VERSION ""

NS_ :

BS_:

BU_: ADSP CH ChassisBus DIPF DIPR ETH FC GTW GTWU HVI HVS ODIN PARTY PartyBus Receiver SDCV SUI UI UIS VEH VIRT VITALS VehicleBus X

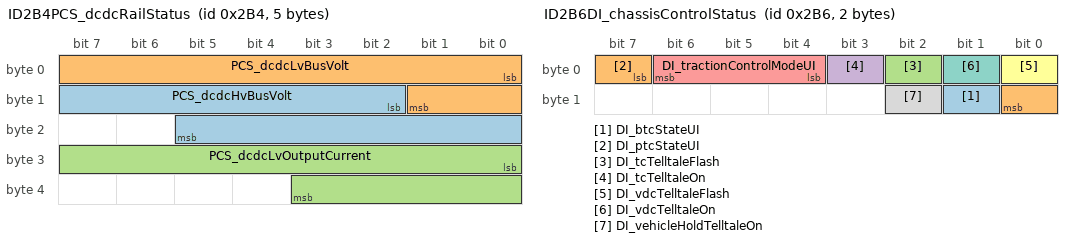
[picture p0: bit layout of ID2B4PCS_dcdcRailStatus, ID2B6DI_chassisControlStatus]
BO_ 692 ID2B4PCS_dcdcRailStatus: 5 VehicleBus
 SG_ PCS_dcdcHvBusVolt : 10|12@1+ (0.146484,0) [0|599.854] "V"  Receiver
 SG_ PCS_dcdcLvBusVolt : 0|10@1+ (0.0390625,0) [0|39.9609] "V"  Receiver
 SG_ PCS_dcdcLvOutputCurrent : 24|12@1+ (0.1,0) [0|400] "A"  Receiver

BO_ 694 ID2B6DI_chassisControlStatus: 2 VehicleBus
 SG_ DI_btcStateUI : 9|1@1+ (1,0) [0|1] ""  Receiver
 SG_ DI_ptcStateUI : 7|2@1+ (1,0) [0|3] ""  Receiver
 SG_ DI_tcTelltaleFlash : 2|1@1+ (1,0) [0|1] ""  Receiver
 SG_ DI_tcTelltaleOn : 3|1@1+ (1,0) [0|1] ""  Receiver
 SG_ DI_tractionControlModeUI : 4|3@1+ (1,0) [0|6] ""  Receiver
 SG_ DI_vdcTelltaleFlash : 0|1@1+ (1,0) [0|1] ""  Receiver
 SG_ DI_vdcTelltaleOn : 1|1@1+ (1,0) [0|1] ""  Receiver
 SG_ DI_vehicleHoldTelltaleOn : 10|1@1+ (1,0) [0|1] ""  Receiver

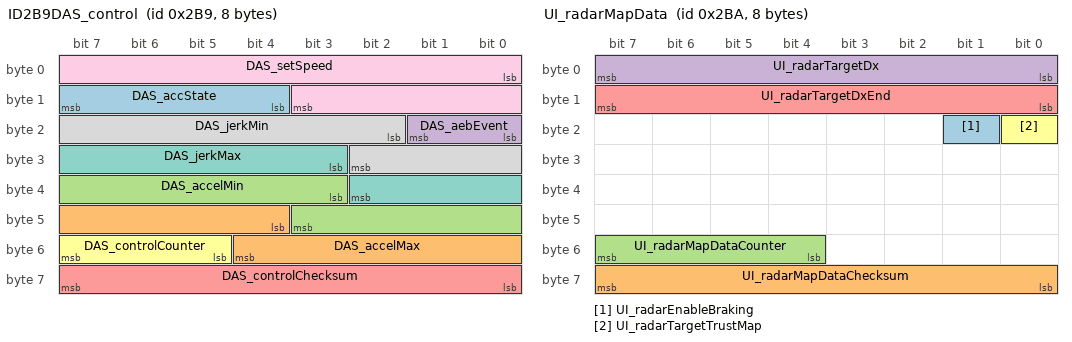
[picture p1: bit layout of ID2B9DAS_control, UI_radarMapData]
BO_ 697 ID2B9DAS_control: 8 ChassisBus
 SG_ DAS_accState : 12|4@1+ (1,0) [0|15] ""  Receiver
 SG_ DAS_accelMax : 44|9@1+ (0.04,-15) [-15|5.44] "m/s^2"  Receiver
 SG_ DAS_accelMin : 35|9@1+ (0.04,-15) [-15|5.44] "m/s^2"  Receiver
 SG_ DAS_aebEvent : 16|2@1+ (1,0) [0|3] ""  Receiver
 SG_ DAS_controlChecksum : 56|8@1+ (1,0) [0|255] ""  Receiver
 SG_ DAS_controlCounter : 53|3@1+ (1,0) [0|7] ""  Receiver
 SG_ DAS_jerkMax : 27|8@1+ (0.059,0) [0|15.045] "m/s^3"  Receiver
 SG_ DAS_jerkMin : 18|9@1+ (0.03,-15.232) [-15.232|0.098] "m/s^3"  Receiver
 SG_ DAS_setSpeed : 0|12@1+ (0.1,0) [0|409.4] "kph"  Receiver

BO_ 698 UI_radarMapData: 8 VEH
 SG_ UI_radarEnableBraking: 17|1@1+ (1,0) [0|0] "" X
 SG_ UI_radarMapDataChecksum: 56|8@1+ (1,0) [0|0] "" X
 SG_ UI_radarMapDataCounter: 52|4@1+ (1,0) [0|0] "" X
 SG_ UI_radarTargetDx: 0|8@1+ (1,-95) [0|0] "m" X
 SG_ UI_radarTargetDxEnd: 8|8@1+ (1,0) [0|0] "m" X
 SG_ UI_radarTargetTrustMap: 16|1@1+ (1,0) [0|0] "" X

BO_ 701 ID2BDCP_dcPowerLimits: 4 VehicleBus
 SG_ CP_evseInstantDcPowerLimit : 0|13@1+ (0.0622559,0) [0|509.938] "kW"  Receiver
 SG_ CP_evseMaxDcPowerLimit : 16|13@1+ (0.0622559,0) [0|509.938] "kW"  Receiver

BO_ 705 VCFRONT_logging10Hz: 8 VEH
 SG_ VCFRONT_logging10HzIndex M : 0|3@1+ (1,0) [0|7] "" X
 SG_ VCFRONT_activeLouverAbnormalKT m4 : 3|1@1+ (1,0) [0|1] "" X
 SG_ VCFRONT_activeLouverCalibRange m4 : 53|8@1+ (1,630) [630|880] "ticks" X
 SG_ VCFRONT_activeLouverCommSuccess m4 : 63|1@1+ (1,0) [0|1] "" X
 SG_ VCFRONT_activeLouverDemand m4 : 32|7@1+ (1,0) [0|100] "%" X
 SG_ VCFRONT_activeLouverDisconnect m4 : 6|1@1+ (1,0) [0|1] "" X
 SG_ VCFRONT_activeLouverFalsStallCal m4 : 62|1@1+ (1,0) [0|1] "" X
 SG_ VCFRONT_activeLouverFalsStallRun m4 : 61|1@1+ (1,0) [0|1] "" X
 SG_ VCFRONT_activeLouverIsCalibrated m4 : 15|1@1+ (1,0) [0|1] "" X
 SG_ VCFRONT_activeLouverMotorCounts m4 : 16|11@1+ (1,-100) [-100|1900] "ticks" X
 SG_ VCFRONT_activeLouverMotorState m4 : 8|3@1+ (1,0) [0|7] "" X
 SG_ VCFRONT_activeLouverOverCurrent m4 : 4|1@1+ (1,0) [0|1] "" X
 SG_ VCFRONT_activeLouverOverTemp m4 : 5|1@1+ (1,0) [0|1] "" X
 SG_ VCFRONT_activeLouverStallCounter m4 : 40|3@1+ (1,0) [0|7] "" X
 SG_ VCFRONT_activeLouverStallLength m4 : 43|10@1+ (1,0) [0|1000] "ticks" X
 SG_ VCFRONT_activeLouverStalled m4 : 7|1@1+ (1,0) [0|1] "" X
 SG_ VCFRONT_activeLouverState m4 : 11|4@1+ (1,0) [0|8] "" X
 SG_ VCFRONT_compLimitDeadband m3 : 8|1@1+ (1,0) [0|1] "" X
 SG_ VCFRONT_compLimitNvh m3 : 6|1@1+ (1,0) [0|1] "" X
 SG_ VCFRONT_compLimitPresDischargeHi m3 : 3|1@1+ (1,0) [0|1] "" X
 SG_ VCFRONT_compLimitScrollSepRamp m3 : 7|1@1+ (1,0) [0|1] "" X
 SG_ VCFRONT_compLimitScrollSepRegion m3 : 5|1@1+ (1,0) [0|1] "" X
 SG_ VCFRONT_compLimitTempDischargeHi m3 : 4|1@1+ (1,0) [0|1] "" X
 SG_ VCFRONT_compLimitTempDischargeSi m3 : 19|1@1+ (1,0) [0|1] "" X
 SG_ VCFRONT_compRampRateUpMax m3 : 20|6@1+ (0.1,0) [0|6] "%/s" X
 SG_ VCFRONT_compStandbyCoastDownMode m3 : 15|1@1+ (1,0) [0|1] "" X
 SG_ VCFRONT_compStandbyCommunication m3 : 10|1@1+ (1,0) [0|1] "" X
 SG_ VCFRONT_compStandbyHVNotReady m3 : 11|1@1+ (1,0) [0|1] "" X
 SG_ VCFRONT_compStandbyHighSuctionSu m3 : 16|1@1+ (1,0) [0|1] "" X
 SG_ VCFRONT_compStandbyLowAmbient m3 : 12|1@1+ (1,0) [0|1] "" X
 SG_ VCFRONT_compStandbyLowDischPress m3 : 13|1@1+ (1,0) [0|1] "" X
 SG_ VCFRONT_compStandbyMultiplePdCut m3 : 17|1@1+ (1,0) [0|1] "" X
 SG_ VCFRONT_compStandbyRefrigNotOk m3 : 14|1@1+ (1,0) [0|1] "" X
 SG_ VCFRONT_compStandbySelfNotReady m3 : 9|1@1+ (1,0) [0|1] "" X
 SG_ VCFRONT_compStandbyShowroomMode m3 : 18|1@1+ (1,0) [0|1] "" X
 SG_ VCFRONT_coolantFlowAmbSourceActu m0 : 48|8@1+ (0.1,0) [0|25] "LPM" X
 SG_ VCFRONT_coolantFlowAmbSourceTarg m0 : 56|8@1+ (0.1,0) [0|25] "LPM" X
 SG_ VCFRONT_coolantTempBasedMode m2 : 3|2@1+ (1,0) [0|3] "" X
 SG_ VCFRONT_coolantValveAngleActual m2 : 8|11@1+ (0.25,-100) [-100|410] "deg" X
 SG_ VCFRONT_coolantValveAngleTarget m2 : 19|10@1+ (0.25,-5) [-5|245] "deg" X
 SG_ VCFRONT_coolantValveAngleTravel m2 : 40|10@1+ (5,0) [0|5000] "deg" X
 SG_ VCFRONT_coolantValveDuty m2 : 32|8@1- (1,0) [-100|100] "%" X
 SG_ VCFRONT_coolantValveISense m2 : 56|7@1+ (0.01,0) [0|1.2] "A" X
 SG_ VCFRONT_coolantValveModeWrong m2 : 5|1@1+ (1,0) [0|1] "" X
 SG_ VCFRONT_coolantValveState m2 : 29|2@1+ (1,0) [0|3] "" X
 SG_ VCFRONT_exvFlow m3 : 32|10@1+ (0.1,0) [0|100] "%" X
 SG_ VCFRONT_exvIsFlooding m3 : 42|1@1+ (1,0) [0|1] "" X
 SG_ VCFRONT_exvMotorState m3 : 28|4@1+ (1,0) [0|10] "" X
 SG_ VCFRONT_exvPrechillActive m3 : 43|1@1+ (1,0) [0|1] "" X
 SG_ VCFRONT_pumpBatSpiError m0 : 46|1@1+ (1,0) [0|1] "" X
 SG_ VCFRONT_pumpBatteryEnabled m0 : 41|1@1+ (1,0) [0|1] "" X
 SG_ VCFRONT_pumpBatteryInitd m0 : 39|1@1+ (1,0) [0|1] "" X
 SG_ VCFRONT_pumpBatteryOutVoltage m0 : 24|7@1+ (0.2,0) [0|20] "V" X
 SG_ VCFRONT_pumpBatteryPowerOn m0 : 43|1@1+ (1,0) [0|1] "" X
 SG_ VCFRONT_pumpBatteryRPMTarget m0 : 3|10@1+ (10,0) [0|10000] "rpm" X
 SG_ VCFRONT_pumpPowertrainEnabled m0 : 42|1@1+ (1,0) [0|1] "" X
 SG_ VCFRONT_pumpPowertrainInitd m0 : 40|1@1+ (1,0) [0|1] "" X
 SG_ VCFRONT_pumpPowertrainOutVoltage m0 : 32|7@1+ (0.2,0) [0|20] "V" X
 SG_ VCFRONT_pumpPowertrainPowerOn m0 : 44|1@1+ (1,0) [0|1] "" X
 SG_ VCFRONT_pumpPowertrainRPMTarget m0 : 13|10@1+ (10,0) [0|10000] "rpm" X
 SG_ VCFRONT_pumpPtSpiError m0 : 47|1@1+ (1,0) [0|1] "" X
 SG_ VCFRONT_pumpsWake m0 : 45|1@1+ (1,0) [0|1] "" X
 SG_ VCFRONT_radarHeaterCurrent m6 : 8|8@1+ (0.1,0) [0|25.5] "A" X
 SG_ VCFRONT_radarHeaterDuty m6 : 16|7@1+ (1,0) [0|100] "%" X
 SG_ VCFRONT_radarHeaterTargetVoltage m6 : 24|8@1+ (0.1,0) [0|16] "V" X
 SG_ VCFRONT_radiatorFanDemandLimit m1 : 48|7@1+ (1,0) [0|100] "%" X
 SG_ VCFRONT_radiatorFanDemandLimited m1 : 47|1@1+ (1,0) [0|1] "" X
 SG_ VCFRONT_radiatorFanEnabled m1 : 27|1@1+ (1,0) [0|1] "" X
 SG_ VCFRONT_radiatorFanInitd m1 : 26|1@1+ (1,0) [0|1] "" X
 SG_ VCFRONT_radiatorFanOutVoltage m1 : 8|7@1+ (0.2,0) [0|20] "V" X
 SG_ VCFRONT_radiatorFanPhaseCurrent m1 : 32|8@1+ (0.25,-10) [-10|50] "A" X
 SG_ VCFRONT_radiatorFanPhaseIMax m1 : 40|7@1+ (0.25,0) [5|35] "A" X
 SG_ VCFRONT_radiatorFanPowerOn m1 : 28|1@1+ (1,0) [0|1] "" X
 SG_ VCFRONT_radiatorFanRPMTarget m1 : 16|10@1+ (10,0) [0|10000] "rpm" X
 SG_ VCFRONT_refrigerantHasBeenFilled m3 : 27|1@1+ (1,0) [0|1] "" X
 SG_ VCFRONT_refrigerantValvesClosed m3 : 26|1@1+ (1,0) [0|1] "" X
 SG_ VCFRONT_solenoidEvapCurrent m3 : 58|6@1+ (0.04,0) [0|2.4] "A" X
 SG_ VCFRONT_subcoolFeedbackFlow m5 : 13|10@1- (0.1,0) [-50|50] "%" X
 SG_ VCFRONT_subcoolFeedforwardFlow m5 : 3|10@1+ (0.1,0) [0|100] "%" X
 SG_ VCFRONT_subcoolProtectionFlow m5 : 24|10@1+ (0.1,0) [0|100] "%" X
 SG_ VCFRONT_subcoolProtectionType m5 : 34|3@1+ (1,0) [0|4] "" X
 SG_ VCFRONT_tempDischargeSimulated m3 : 44|11@1+ (0.125,-40) [-40|150] "C" X
 SG_ VCFRONT_thmlFanSpiError m1 : 55|1@1+ (1,0) [0|1] "" X
 SG_ VCFRONT_usingSimulatedAmbTemp m3 : 57|1@1+ (1,0) [0|1] "" X
 SG_ VCFRONT_usingSimulatedDischTemp m3 : 56|1@1+ (1,0) [0|1] "" X
 SG_ VCFRONT_usingSimulatedSuctTemp m3 : 55|1@1+ (1,0) [0|1] "" X

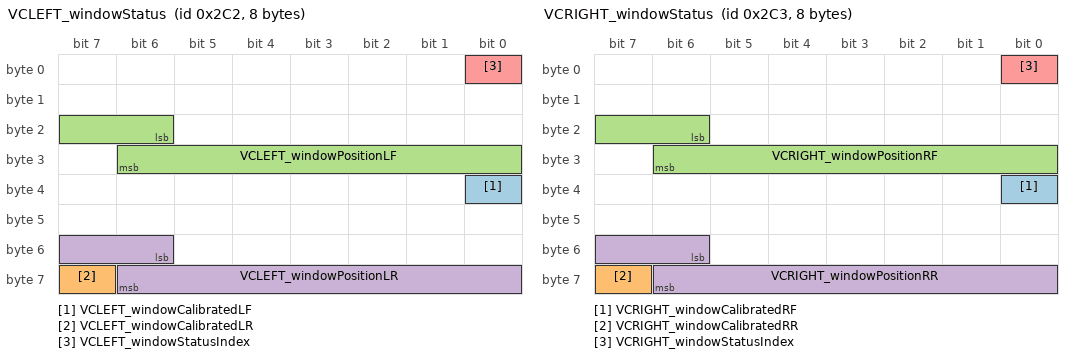
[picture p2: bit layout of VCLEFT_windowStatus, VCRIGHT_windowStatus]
BO_ 706 VCLEFT_windowStatus: 8 GTW
 SG_ VCLEFT_windowCalibratedLF : 32|1@1+ (1,0) [0|1] "" ODIN,SUI,UI
 SG_ VCLEFT_windowCalibratedLR : 63|1@1+ (1,0) [0|1] "" ODIN,SUI,UI
 SG_ VCLEFT_windowPositionLF : 22|9@1- (1.25,265.0) [-50|580] "mm" ODIN,UI
 SG_ VCLEFT_windowPositionLR : 54|9@1- (1.25,265.0) [-50|580] "mm" ODIN,UI
 SG_ VCLEFT_windowStatusIndex : 0|1@1+ (1,0) [0|1] "" XXX

BO_ 707 VCRIGHT_windowStatus: 8 GTW
 SG_ VCRIGHT_windowCalibratedRF : 32|1@1+ (1,0) [0|1] "" ODIN,SUI,UI
 SG_ VCRIGHT_windowCalibratedRR : 63|1@1+ (1,0) [0|1] "" ODIN,SUI,UI
 SG_ VCRIGHT_windowPositionRF : 22|9@1- (1.25,265.0) [-50|580] "mm" ODIN,UI
 SG_ VCRIGHT_windowPositionRR : 54|9@1- (1.25,265.0) [-50|580] "mm" ODIN,UI
 SG_ VCRIGHT_windowStatusIndex : 0|1@1+ (1,0) [0|1] "" XXX

BO_ 708 PCS_logging: 8 VEH
 SG_ PCS_logMessageSelect M: 0|5@1+ (1,0) [0|0] "" X
 SG_ PCS_chgPhAInputIrms m0: 5|9@1+ (0.1,0) [0|0] "A" X
 SG_ PCS_chgPhAIntBusV m0: 14|9@1+ (1,0) [0|0] "V" X
 SG_ PCS_chgPhAIntBusVTarget m0: 23|9@1+ (1,0) [0|0] "V" X
 SG_ PCS_chgPhAOutputI m0: 32|8@1+ (0.1,0) [0|0] "A" X
 SG_ PCS_chgPhBInputIrms m1: 5|9@1+ (0.1,0) [0|0] "A" X
 SG_ PCS_chgPhBIntBusV m1: 14|9@1+ (1,0) [0|0] "V" X
 SG_ PCS_chgPhBIntBusVTarget m1: 23|9@1+ (1,0) [0|0] "V" X
 SG_ PCS_chgPhBOutputI m1: 32|8@1+ (0.1,0) [0|0] "A" X
 SG_ PCS_chgPhCInputIrms m2: 5|9@1+ (0.1,0) [0|0] "A" X
 SG_ PCS_chgPhCIntBusV m2: 14|9@1+ (1,0) [0|0] "V" X
 SG_ PCS_chgPhCIntBusVTarget m2: 23|9@1+ (1,0) [0|0] "V" X
 SG_ PCS_chgPhCOutputI m2: 32|8@1+ (0.1,0) [0|0] "A" X
 SG_ PCS_chgInputL1NVrms m3: 5|12@1+ (0.2,0) [0|0] "V" X
 SG_ PCS_chgInputL2NVrms m3: 17|12@1+ (0.2,0) [0|0] "V" X
 SG_ PCS_chgInputL3NVrms m3: 29|12@1+ (0.2,0) [0|0] "V" X
 SG_ PCS_chgInputL1L2Vrms m3: 41|12@1+ (0.2,0) [0|0] "V" X
 SG_ PCS_chgInputNGVrms m3: 53|9@1+ (1,0) [0|0] "V" X
 SG_ PCS_chgInputFrequencyL1N m4: 8|12@1+ (0.01,40) [0|0] "Hz" X
 SG_ PCS_chgInputFrequencyL2N m4: 20|12@1+ (0.01,40) [0|0] "Hz" X
 SG_ PCS_chgInputFrequencyL3N m4: 32|12@1+ (0.01,40) [0|0] "Hz" X
 SG_ PCS_chgInternalPhaseConfig m4: 44|3@1+ (1,0) [0|0] "" X
 SG_ PCS_chgOutputV m4: 48|12@1+ (0.146484,0) [0|0] "V" X
 SG_ PCS_chgPhAState m5: 5|4@1+ (1,0) [0|0] "" X
 SG_ PCS_chgPhBState m5: 9|4@1+ (1,0) [0|0] "" X
 SG_ PCS_chgPhCState m5: 13|4@1+ (1,0) [0|0] "" X
 SG_ PCS_chgPhALastShutdownReason m5: 17|5@1+ (1,0) [0|0] "" X
 SG_ PCS_chgPhBLastShutdownReason m5: 22|5@1+ (1,0) [0|0] "" X
 SG_ PCS_chgPhCLastShutdownReason m5: 27|5@1+ (1,0) [0|0] "" X
 SG_ PCS_chgPhARetryCount m5: 32|3@1+ (1,0) [0|0] "" X
 SG_ PCS_chgPhBRetryCount m5: 35|3@1+ (1,0) [0|0] "" X
 SG_ PCS_chgPhCRetryCount m5: 38|3@1+ (1,0) [0|0] "" X
 SG_ PCS_chgRetryCount m5: 41|3@1+ (1,0) [0|0] "" X
 SG_ PCS_chgPhManCurrentToDist m5: 44|10@1+ (0.1,0) [0|0] "A" X
 SG_ PCS_chgL1NPllLocked m5: 54|1@1+ (1,0) [0|0] "" X
 SG_ PCS_chgL2NPllLocked m5: 55|1@1+ (1,0) [0|0] "" X
 SG_ PCS_chgL3NPllLocked m5: 56|1@1+ (1,0) [0|0] "" X
 SG_ PCS_chgL1L2PllLocked m5: 57|1@1+ (1,0) [0|0] "" X
 SG_ PCS_chgNgPllLocked m5: 58|1@1+ (1,0) [0|0] "" X
 SG_ PCS_chgPhManOptimalPhsToUse m5: 59|2@1+ (1,0) [0|0] "" X
 SG_ PCS_chg5VL1Enable m5: 61|1@1+ (1,0) [0|0] "" X
 SG_ PCS_dcdcMaxLvOutputCurrent m6: 28|12@1+ (0.1,0) [0|0] "A" X
 SG_ PCS_dcdcCurrentLimit m6: 40|12@1+ (0.1,0) [0|0] "A" X
 SG_ PCS_dcdcLvOutputCurrentTempLimit m6: 52|12@1+ (0.1,0) [0|0] "A" X
 SG_ PCS_dcdcUnifiedCommand m7: 5|10@1+ (0.001,0) [0|0] "1" X
 SG_ PCS_dcdcCLAControllerOutput m7: 16|10@1+ (0.001,0) [0|0] "1" X
 SG_ PCS_dcdcTankVoltage m7: 26|11@1- (1,0) [0|0] "V" X
 SG_ PCS_dcdcTankVoltageTarget m7: 37|10@1+ (1,0) [0|0] "V" X
 SG_ PCS_dcdcClaCurrentFreq m7: 48|12@1+ (0.0976563,0) [0|0] "kHz" X
 SG_ PCS_dcdcTCommMeasured m8: 8|16@1- (0.00195313,0) [0|0] "us" X
 SG_ PCS_dcdcShortTimeUs m8: 24|16@1+ (0.000488281,0) [0|0] "us" X
 SG_ PCS_dcdcHalfPeriodUs m8: 40|16@1+ (0.000488281,0) [0|0] "us" X
 SG_ PCS_cpu2BootState m9: 5|2@1+ (1,0) [0|0] "" X
 SG_ PCS_acChargeSelfTestState m9: 7|1@1+ (1,0) [0|0] "" X
 SG_ PCS_1V5Min10s m9: 8|11@1+ (0.001,0) [0|0] "V" X
 SG_ PCS_1V5Max10s m9: 19|11@1+ (0.001,0) [0|0] "V" X
 SG_ PCS_1V2Min10s m9: 32|11@1+ (0.001,0) [0|0] "V" X
 SG_ PCS_1V2Max10s m9: 43|11@1+ (0.001,0) [0|0] "V" X
 SG_ PCS_numAlertsSet m9: 56|7@1+ (1,0) [0|0] "" X
 SG_ PCS_chgPhAIntBusVMin10s m10: 5|9@1+ (1,0) [0|0] "V" X
 SG_ PCS_chgPhAIntBusVMax10s m10: 14|9@1+ (1,0) [0|0] "V" X
 SG_ PCS_chgPhAPchgVoltDeltaMax10s m10: 23|8@1+ (0.5,0) [0|0] "V" X
 SG_ PCS_chgPhALifetimekWh m10: 31|24@1+ (0.01,0) [0|0] "kWh" X
 SG_ PCS_chgPhATransientRetryCount m10: 55|9@1+ (0.1,0) [0|0] "-" X
 SG_ PCS_chgPhBIntBusVMin10s m11: 5|9@1+ (1,0) [0|0] "V" X
 SG_ PCS_chgPhBIntBusVMax10s m11: 14|9@1+ (1,0) [0|0] "V" X
 SG_ PCS_chgPhBPchgVoltDeltaMax10s m11: 23|8@1+ (0.5,0) [0|0] "V" X
 SG_ PCS_chgPhBLifetimekWh m11: 31|24@1+ (0.01,0) [0|0] "kWh" X
 SG_ PCS_chgPhBTransientRetryCount m11: 55|9@1+ (0.1,0) [0|0] "-" X
 SG_ PCS_chgPhCIntBusVMin10s m12: 5|9@1+ (1,0) [0|0] "V" X
 SG_ PCS_chgPhCIntBusVMax10s m12: 14|9@1+ (1,0) [0|0] "V" X
 SG_ PCS_chgPhCPchgVoltDeltaMax10s m12: 23|8@1+ (0.5,0) [0|0] "V" X
 SG_ PCS_chgPhCLifetimekWh m12: 31|24@1+ (0.01,0) [0|0] "kWh" X
 SG_ PCS_chgPhCTransientRetryCount m12: 55|9@1+ (0.1,0) [0|0] "-" X
 SG_ PCS_chgInputL1NVPeak10s m13: 5|9@1+ (1,0) [0|0] "V" X
 SG_ PCS_chgInputL2NVPeak10s m13: 14|9@1+ (1,0) [0|0] "V" X
 SG_ PCS_chgInputL3NVPeak10s m13: 23|9@1+ (1,0) [0|0] "V" X
 SG_ PCS_chgInputFreqWobblePHAPeak m13: 32|8@1+ (0.01,0) [0|0] "Hz" X
 SG_ PCS_chgInputFreqWobblePHBPeak m13: 40|8@1+ (0.01,0) [0|0] "Hz" X
 SG_ PCS_chgInputFreqWobblePHCPeak m13: 48|8@1+ (0.01,0) [0|0] "Hz" X
 SG_ PCS_dLogPhAChannel1Content m14: 5|2@1+ (1,0) [0|0] "" X
 SG_ PCS_dLogPhBChannel1Content m14: 8|2@1+ (1,0) [0|0] "" X
 SG_ PCS_dLogPhCChannel1Content m14: 10|2@1+ (1,0) [0|0] "" X
 SG_ PCS_dLogPhAChannel1Data m14: 16|16@1- (0.02,0) [0|0] "-" X
 SG_ PCS_dLogPhBChannel1Data m14: 32|16@1- (0.02,0) [0|0] "-" X
 SG_ PCS_dLogPhCChannel1Data m14: 48|16@1- (0.02,0) [0|0] "-" X
 SG_ PCS_dLogPhAChannel2Content m15: 5|2@1+ (1,0) [0|0] "" X
 SG_ PCS_dLogPhBChannel2Content m15: 8|2@1+ (1,0) [0|0] "" X
 SG_ PCS_dLogPhCChannel2Content m15: 10|2@1+ (1,0) [0|0] "" X
 SG_ PCS_dLogPhAChannel2Data m15: 16|16@1- (0.02,0) [0|0] "-" X
 SG_ PCS_dLogPhBChannel2Data m15: 32|16@1- (0.02,0) [0|0] "-" X
 SG_ PCS_dLogPhCChannel2Data m15: 48|16@1- (0.02,0) [0|0] "-" X
 SG_ PCS_dLogPhAChannel3Content m16: 5|2@1+ (1,0) [0|0] "" X
 SG_ PCS_dLogPhBChannel3Content m16: 8|2@1+ (1,0) [0|0] "" X
 SG_ PCS_dLogPhCChannel3Content m16: 10|2@1+ (1,0) [0|0] "" X
 SG_ PCS_dLogPhAChannel3Data m16: 16|16@1- (0.02,0) [0|0] "-" X
 SG_ PCS_dLogPhBChannel3Data m16: 32|16@1- (0.02,0) [0|0] "-" X
 SG_ PCS_dLogPhCChannel3Data m16: 48|16@1- (0.02,0) [0|0] "-" X
 SG_ PCS_dLogPhAChannel4Content m17: 5|2@1+ (1,0) [0|0] "" X
 SG_ PCS_dLogPhBChannel4Content m17: 8|2@1+ (1,0) [0|0] "" X
 SG_ PCS_dLogPhCChannel4Content m17: 10|2@1+ (1,0) [0|0] "" X
 SG_ PCS_dLogPhAChannel4Data m17: 16|16@1- (0.02,0) [0|0] "-" X
 SG_ PCS_dLogPhBChannel4Data m17: 32|16@1- (0.02,0) [0|0] "-" X
 SG_ PCS_dLogPhCChannel4Data m17: 48|16@1- (0.02,0) [0|0] "-" X
 SG_ PCS_dcdcIntervalMaxFrequency m18: 8|12@1+ (1,0) [0|0] "kHz" X
 SG_ PCS_dcdcIntervalMaxHvBusVolt m18: 24|13@1+ (0.1,0) [0|0] "V" X
 SG_ PCS_dcdcIntervalMaxLvBusVolt m18: 37|9@1+ (0.1,0) [0|0] "V" X
 SG_ PCS_dcdcIntervalMaxLvOutputCurr m18: 48|12@1+ (1,0) [0|0] "A" X
 SG_ PCS_dcdcIntervalMinFrequency m19: 8|12@1+ (1,0) [0|0] "kHz" X
 SG_ PCS_dcdcIntervalMinHvBusVolt m19: 24|13@1+ (0.1,0) [0|0] "V" X
 SG_ PCS_dcdcIntervalMinLvBusVolt m19: 37|9@1+ (0.1,0) [0|0] "V" X
 SG_ PCS_dcdcIntervalMinLvOutputCurr m19: 48|12@1+ (1,0) [0|0] "A" X
 SG_ PCS_chgPhANoFlowBucket m20: 5|9@1+ (0.01,0) [0|0] "-" X
 SG_ PCS_chgPhBNoFlowBucket m20: 14|9@1+ (0.01,0) [0|0] "-" X
 SG_ PCS_chgPhCNoFlowBucket m20: 23|9@1+ (0.01,0) [0|0] "-" X
 SG_ PCS_chgInputL1NVdc m21: 5|10@1- (1,0) [0|0] "V" X
 SG_ PCS_chgInputL2NVdc m21: 16|10@1- (1,0) [0|0] "V" X
 SG_ PCS_chgInputL3NVdc m21: 26|10@1- (1,0) [0|0] "V" X
 SG_ PCS_chgInputL1L2Vdc m21: 36|10@1- (1,0) [0|0] "V" X
 SG_ PCS_chgInputNGVdc m21: 46|10@1- (1,0) [0|0] "V" X
 SG_ PCS_dcdc12vSupportLifetimekWh m22: 8|24@1+ (0.01,0) [0|0] "kWh" X

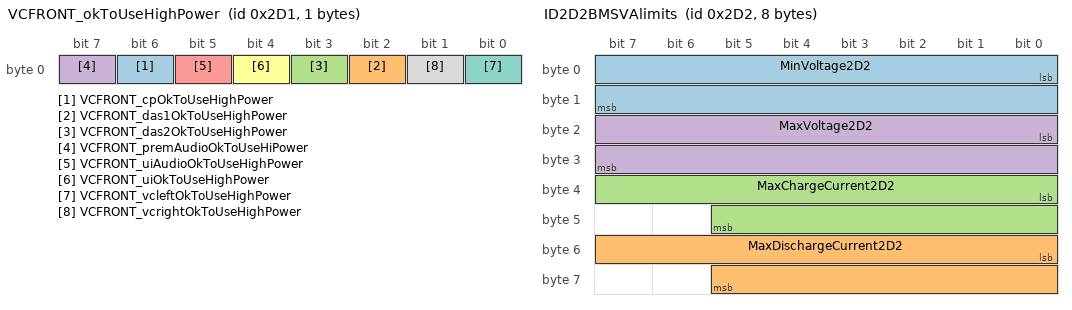
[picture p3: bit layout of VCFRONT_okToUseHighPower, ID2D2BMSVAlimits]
BO_ 721 VCFRONT_okToUseHighPower: 1 VEH
 SG_ VCFRONT_cpOkToUseHighPower: 6|1@1+ (1,0) [0|0] "" X
 SG_ VCFRONT_das1OkToUseHighPower: 2|1@1+ (1,0) [0|0] "" X
 SG_ VCFRONT_das2OkToUseHighPower: 3|1@1+ (1,0) [0|0] "" X
 SG_ VCFRONT_premAudioOkToUseHiPower: 7|1@1+ (1,0) [0|0] "" X
 SG_ VCFRONT_uiAudioOkToUseHighPower: 5|1@1+ (1,0) [0|0] "" X
 SG_ VCFRONT_uiOkToUseHighPower: 4|1@1+ (1,0) [0|0] "" X
 SG_ VCFRONT_vcleftOkToUseHighPower: 0|1@1+ (1,0) [0|0] "" X
 SG_ VCFRONT_vcrightOkToUseHighPower: 1|1@1+ (1,0) [0|0] "" X

BO_ 722 ID2D2BMSVAlimits: 8 VehicleBus
 SG_ MinVoltage2D2 : 0|16@1+ (0.01,0) [0|430] "V"  Receiver
 SG_ MaxDischargeCurrent2D2 : 48|14@1+ (0.128,0) [0|2096.9] "A"  Receiver
 SG_ MaxChargeCurrent2D2 : 32|14@1+ (0.1,0) [0|1638.2] "A"  Receiver
 SG_ MaxVoltage2D2 : 16|16@1+ (0.01,0) [0|430] "V"  Receiver

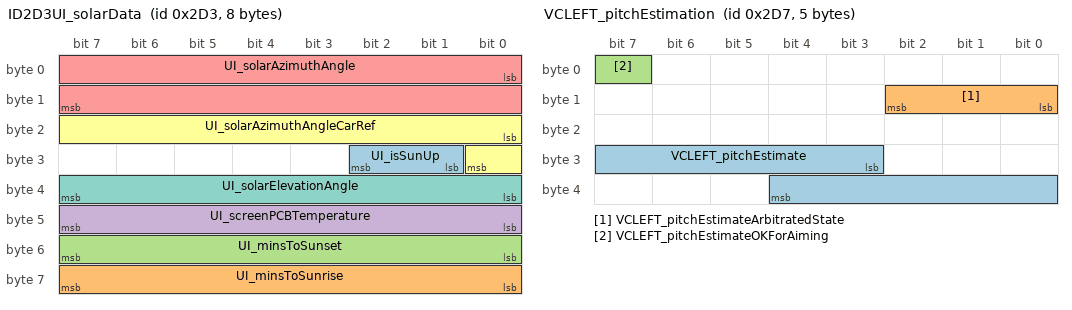
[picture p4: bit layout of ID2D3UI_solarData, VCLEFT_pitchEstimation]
BO_ 723 ID2D3UI_solarData: 8 ChassisBus
 SG_ UI_isSunUp : 25|2@1+ (1,0) [0|3] ""  Receiver
 SG_ UI_minsToSunrise : 56|8@1+ (10,0) [0|2550] "min"  Receiver
 SG_ UI_minsToSunset : 48|8@1+ (10,0) [0|2550] "min"  Receiver
 SG_ UI_screenPCBTemperature : 40|8@1- (0.5,40) [-20|100] "C"  Receiver
 SG_ UI_solarAzimuthAngle : 0|16@1- (1,0) [-32767|32767] "deg"  Receiver
 SG_ UI_solarAzimuthAngleCarRef : 16|9@1- (1,0) [-256|254] "deg"  Receiver
 SG_ UI_solarElevationAngle : 32|8@1- (1,0) [-128|126] "deg"  Receiver

BO_ 725 DIF_status: 7 GTW
 SG_ DIF_wasteState : 32|2@1+ (1,0) [0|3] "" ODIN,SUI

BO_ 727 VCLEFT_pitchEstimation: 5 GTW
 SG_ VCLEFT_pitchEstimate : 27|10@1- (0.0002,0) [-0.1022|0.1022] "rad" ODIN
 SG_ VCLEFT_pitchEstimateArbitratedState : 8|3@1+ (1,0) [0|7] "" ODIN
 SG_ VCLEFT_pitchEstimateOKForAiming : 7|1@1+ (1,0) [0|1] "" ODIN,UI

BO_ 737 ID2E1VCFRONT_status: 8 VehicleBus
 SG_ VCFRONT_statusIndex M : 0|3@1+ (1,0) [0|6] ""  Receiver
 SG_ VCFRONT_12VARailStable m5 : 5|1@1+ (1,0) [0|1] ""  Receiver
 SG_ VCFRONT_12VBRailStable m5 : 6|1@1+ (1,0) [0|1] ""  Receiver
 SG_ VCFRONT_12VOverchargeCounter m4 : 16|4@1+ (1,0) [0|15] ""  Receiver
 SG_ VCFRONT_5VARailStable m5 : 3|1@1+ (1,0) [0|1] ""  Receiver
 SG_ VCFRONT_5VBRailStable m5 : 4|1@1+ (1,0) [0|1] ""  Receiver
 SG_ VCFRONT_AS8510Voltage m5 : 28|12@1+ (0.00544368,0) [0|22.2864] "V"  Receiver
 SG_ VCFRONT_ChargePumpVoltageStable m5 : 9|1@1+ (1,0) [0|1] ""  Receiver
 SG_ VCFRONT_HSDInitCompleteU13 m5 : 11|1@1+ (1,0) [0|1] ""  Receiver
 SG_ VCFRONT_HSDInitCompleteU16 m5 : 12|1@1+ (1,0) [0|1] ""  Receiver
 SG_ VCFRONT_IBSFault m4 : 15|1@1+ (1,0) [0|1] ""  Receiver
 SG_ VCFRONT_PCSMia m4 : 14|1@1+ (1,0) [0|1] ""  Receiver
 SG_ VCFRONT_PEResetLineState m5 : 10|1@1+ (1,0) [0|1] ""  Receiver
 SG_ VCFRONT_airCompressorStatus m0 : 25|3@1+ (1,0) [0|7] ""  Receiver
 SG_ VCFRONT_anyClosureOpen m0 : 49|1@1+ (1,0) [0|1] ""  Receiver
 SG_ VCFRONT_anyDoorOpen m0 : 50|1@1+ (1,0) [0|1] ""  Receiver
 SG_ VCFRONT_batterySMState m1 : 16|4@1+ (1,0) [0|8] ""  Receiver
 SG_ VCFRONT_chargeNeeded m4 : 13|1@1+ (1,0) [0|1] ""  Receiver
 SG_ VCFRONT_chillerDemandActive m3 : 26|1@1+ (1,0) [0|1] ""  Receiver
 SG_ VCFRONT_compPerfRecoveryLimited m3 : 27|1@1+ (1,0) [0|1] ""  Receiver
 SG_ VCFRONT_coolantFillRoutineStatus m3 : 50|2@1+ (1,0) [0|3] ""  Receiver
 SG_ VCFRONT_crashDetectedType m0 : 20|2@1+ (1,0) [0|3] ""  Receiver
 SG_ VCFRONT_crashState m0 : 22|2@1+ (1,0) [0|3] ""  Receiver
 SG_ VCFRONT_crashUnlockOverrideSet m0 : 24|1@1+ (1,0) [0|1] ""  Receiver
 SG_ VCFRONT_epasWakeLine m1 : 4|1@1+ (1,0) [0|1] ""  Receiver
 SG_ VCFRONT_freezeEvapITerm m3 : 24|1@1+ (1,0) [0|1] ""  Receiver
 SG_ VCFRONT_frunkAccessPost m0 : 62|1@1+ (1,0) [0|1] ""  Receiver
 SG_ VCFRONT_frunkInteriorRelSwitch m0 : 48|1@1+ (1,0) [0|1] ""  Receiver
 SG_ VCFRONT_frunkLatchStatus m0 : 3|4@1+ (1,0) [0|8] ""  Receiver
 SG_ VCFRONT_frunkLatchType m0 : 58|2@1+ (1,0) [0|2] ""  Receiver
 SG_ VCFRONT_hasLowRefrigerant m3 : 29|1@1+ (1,0) [0|1] ""  Receiver
 SG_ VCFRONT_headlampLeftFanStatus m0 : 60|1@1+ (1,0) [0|1] ""  Receiver
 SG_ VCFRONT_headlampRightFanStatus m0 : 61|1@1+ (1,0) [0|1] ""  Receiver
 SG_ VCFRONT_headlightLeftVPosition m0 : 28|10@1+ (1,0) [0|1023] "ticks"  Receiver
 SG_ VCFRONT_headlightRightVPosition m0 : 38|10@1+ (1,0) [0|1023] "ticks"  Receiver
 SG_ VCFRONT_homelinkCommStatus m2 : 48|2@1+ (1,0) [0|3] ""  Receiver
 SG_ VCFRONT_homelinkV2Response0 m2 : 8|8@1+ (1,0) [0|255] ""  Receiver
 SG_ VCFRONT_homelinkV2Response1 m2 : 16|8@1+ (1,0) [0|255] ""  Receiver
 SG_ VCFRONT_homelinkV2Response2 m2 : 24|8@1+ (1,0) [0|255] ""  Receiver
 SG_ VCFRONT_homelinkV2Response3 m2 : 32|8@1+ (1,0) [0|255] ""  Receiver
 SG_ VCFRONT_homelinkV2Response4 m2 : 40|8@1+ (1,0) [0|255] ""  Receiver
 SG_ VCFRONT_hornOn m0 : 51|1@1+ (1,0) [0|1] ""  Receiver
 SG_ VCFRONT_hvacModeNotAttainable m3 : 28|1@1+ (1,0) [0|1] ""  Receiver
 SG_ VCFRONT_hvacPerfTestCommand m3 : 48|2@1+ (1,0) [0|3] ""  Receiver
 SG_ VCFRONT_iBoosterStateDBG m1 : 5|3@1+ (1,0) [0|4] ""  Receiver
 SG_ VCFRONT_iBoosterWakeLine m1 : 3|1@1+ (1,0) [0|1] ""  Receiver
 SG_ VCFRONT_isActiveHeatingBattery m0 : 63|1@1+ (1,0) [0|1] ""  Receiver
 SG_ VCFRONT_isColdStartRunning m3 : 30|1@1+ (1,0) [0|1] ""  Receiver
 SG_ VCFRONT_isEvapOperationAllowed m3 : 25|1@1+ (1,0) [0|1] ""  Receiver
 SG_ VCFRONT_isHeatPumpOilPurgeActive m3 : 31|1@1+ (1,0) [0|1] ""  Receiver
 SG_ VCFRONT_maxEvapHeatRejection m3 : 8|8@1+ (65,0) [0|16575] "W"  Receiver
 SG_ VCFRONT_minEvapHeatRejection m3 : 16|8@1+ (10,0) [0|2500] "W"  Receiver
 SG_ VCFRONT_passengerBuckleStatus m0 : 57|1@1+ (1,0) [0|1] ""  Receiver
 SG_ VCFRONT_pressureRefrigDischarge m3 : 40|8@1+ (0.125,0) [0|31.75] "bar"  Receiver
 SG_ VCFRONT_pressureRefrigSuction m3 : 32|7@1+ (0.125,0) [0|11.5] "bar"  Receiver
 SG_ VCFRONT_radarHeaterState m0 : 52|3@1+ (1,0) [0|4] ""  Receiver
 SG_ VCFRONT_railAState m5 : 7|1@1+ (1,0) [0|1] ""  Receiver
 SG_ VCFRONT_railBState m5 : 8|1@1+ (1,0) [0|1] ""  Receiver
 SG_ VCFRONT_refrigFillRoutineStatus m3 : 52|2@1+ (1,0) [0|3] ""  Receiver
 SG_ VCFRONT_reverseBatteryFault m4 : 30|1@1+ (1,0) [0|1] ""  Receiver
 SG_ VCFRONT_shortedCellFaultCounter m4 : 44|3@1+ (1,0) [0|7] ""  Receiver
 SG_ VCFRONT_silentWakeIBSCurrent m4 : 32|12@1- (0.1,-204.7) [-409.5|0] "mA"  Receiver
 SG_ VCFRONT_sleepCurrent m1 : 32|12@1- (0.1,-204.7) [-409.5|0] "mA"  Receiver
 SG_ VCFRONT_tempCompTargetVoltage m4 : 3|10@1+ (0.01,9) [9|16] "V"  Receiver
 SG_ VCFRONT_timeSpentSleeping m1 : 24|8@1+ (1,0) [0|255] "s"  Receiver
 SG_ VCFRONT_vbatMonitorVoltage m5 : 16|12@1+ (0.00544368,0) [0|22.2864] "V"  Receiver
 SG_ VCFRONT_vbatProt m5 : 40|12@1+ (0.00544368,0) [0|22.2919] "V"  Receiver
 SG_ VCFRONT_vehicleStatusDBG m1 : 8|5@1+ (1,0) [0|17] ""  Receiver
 SG_ VCFRONT_voltageDropCounter m4 : 20|4@1+ (1,0) [0|15] ""  Receiver
 SG_ VCFRONT_voltageFloorReachedCount m4 : 24|4@1+ (1,0) [0|15] ""  Receiver
 SG_ VCFRONT_voltageProfile m4 : 28|2@1+ (1,0) [0|3] ""  Receiver
 SG_ VCFRONT_wiperPosition m0 : 12|3@1+ (1,0) [0|4] ""  Receiver
 SG_ VCFRONT_wiperSpeed m0 : 8|4@1+ (1,0) [0|8] ""  Receiver
 SG_ VCFRONT_wiperState m0 : 16|4@1+ (1,0) [0|12] ""  Receiver

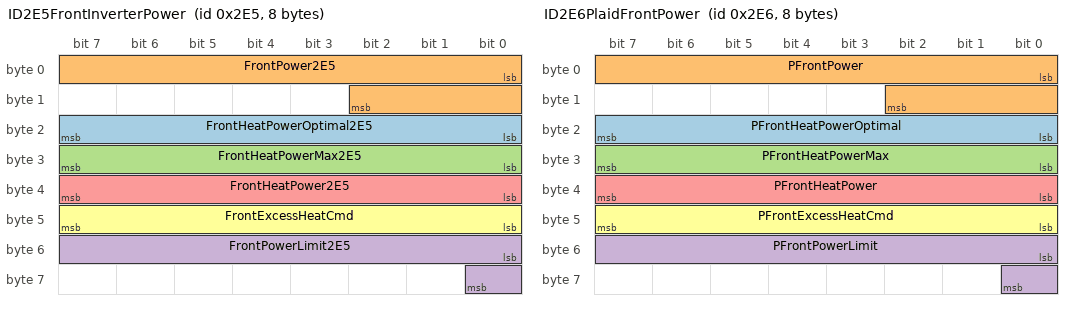
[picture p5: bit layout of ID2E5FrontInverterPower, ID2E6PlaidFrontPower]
BO_ 741 ID2E5FrontInverterPower: 8 VehicleBus
 SG_ FrontHeatPowerOptimal2E5 : 16|8@1+ (0.08,0) [0|20.4] "kW"  Receiver
 SG_ FrontPower2E5 : 0|11@1- (0.5,0) [-512|511.5] "kW"  Receiver
 SG_ FrontHeatPowerMax2E5 : 24|8@1+ (0.08,0) [0|20.4] "kW"  Receiver
 SG_ FrontPowerLimit2E5 : 48|9@1+ (1,0) [0|400] "kW"  Receiver
 SG_ FrontHeatPower2E5 : 32|8@1+ (0.08,0) [0|20.4] "kW"  Receiver
 SG_ FrontExcessHeatCmd : 40|8@1+ (0.08,0) [0|20] "kW"  Receiver

BO_ 742 ID2E6PlaidFrontPower: 8 VehicleBus
 SG_ PFrontHeatPowerOptimal : 16|8@1+ (0.08,0) [0|20.4] "kW"  Receiver
 SG_ PFrontPower : 0|11@1- (0.5,0) [-512|511.5] "kW"  Receiver
 SG_ PFrontHeatPowerMax : 24|8@1+ (0.08,0) [0|20.4] "kW"  Receiver
 SG_ PFrontPowerLimit : 48|9@1+ (1,0) [0|400] "kW"  Receiver
 SG_ PFrontHeatPower : 32|8@1+ (0.08,0) [0|20.4] "kW"  Receiver
 SG_ PFrontExcessHeatCmd : 40|8@1+ (0.08,0) [0|20] "kW"  Receiver

BO_ 744 EPBR_status: 8 GTW
 SG_ EPBR_systemStatus : 0|4@1+ (1,0) [0|8] "" ODIN,SUI,UI,VITALS

BO_ 753 ID2F1VCFRONT_eFuseDebugStatus: 8 VehicleBus
 SG_ VCFRONT_eFuseDebugStatusIndex M : 0|5@1+ (1,0) [0|18] ""  Receiver
 SG_ VCFRONT_ChargePumpVoltage m16 : 24|16@1+ (0.00544368,0) [0|356.751] "V"  Receiver
 SG_ VCFRONT_EPAS3PCurrent m4 : 47|16@1+ (0.1,0) [0|6553.5] "A"  Receiver
 SG_ VCFRONT_EPAS3PFault m4 : 10|1@1+ (1,0) [0|1] ""  Receiver
 SG_ VCFRONT_EPAS3PSelfTestResult m4 : 11|4@1+ (1,0) [0|11] ""  Receiver
 SG_ VCFRONT_EPAS3PState m4 : 8|2@1+ (1,0) [0|2] ""  Receiver
 SG_ VCFRONT_EPAS3PTemp m4 : 15|11@1+ (0.125,-40) [-40|150] "C"  Receiver
 SG_ VCFRONT_EPAS3PVoltage m4 : 31|16@1+ (0.1,0) [0|6553.5] "V"  Receiver
 SG_ VCFRONT_EPAS3SCurrent m5 : 47|16@1+ (0.1,0) [0|6553.5] "A"  Receiver
 SG_ VCFRONT_EPAS3SFault m5 : 10|1@1+ (1,0) [0|1] ""  Receiver
 SG_ VCFRONT_EPAS3SSelfTestResult m5 : 11|4@1+ (1,0) [0|11] ""  Receiver
 SG_ VCFRONT_EPAS3SState m5 : 8|2@1+ (1,0) [0|2] ""  Receiver
 SG_ VCFRONT_EPAS3STemp m5 : 15|11@1+ (0.125,-40) [-40|150] "C"  Receiver
 SG_ VCFRONT_EPAS3SVoltage m5 : 31|16@1+ (0.1,0) [0|6553.5] "V"  Receiver
 SG_ VCFRONT_ESPMotorCurrent m6 : 47|16@1+ (0.1,0) [0|6553.5] "A"  Receiver
 SG_ VCFRONT_ESPMotorFault m6 : 10|1@1+ (1,0) [0|1] ""  Receiver
 SG_ VCFRONT_ESPMotorSelfTestResult m6 : 11|4@1+ (1,0) [0|11] ""  Receiver
 SG_ VCFRONT_ESPMotorState m6 : 8|2@1+ (1,0) [0|2] ""  Receiver
 SG_ VCFRONT_ESPMotorTemp m6 : 15|11@1+ (0.125,-40) [-40|150] "C"  Receiver
 SG_ VCFRONT_ESPMotorVoltage m6 : 31|16@1+ (0.1,0) [0|6553.5] "V"  Receiver
 SG_ VCFRONT_ESPValveCurrent m7 : 44|16@1+ (0.1,0) [0|6553.5] "A"  Receiver
 SG_ VCFRONT_ESPValveFault m7 : 10|1@1+ (1,0) [0|1] ""  Receiver
 SG_ VCFRONT_ESPValveState m7 : 8|2@1+ (1,0) [0|2] ""  Receiver
 SG_ VCFRONT_ESPValveTemp m7 : 12|11@1+ (0.125,-40) [-40|150] "C"  Receiver
 SG_ VCFRONT_ESPValveVoltage m7 : 28|16@1+ (0.1,0) [0|6553.5] "V"  Receiver
 SG_ VCFRONT_IBSUnfilteredTemperature m17 : 40|16@1- (0.01,0) [-327.68|327.67] "C"  Receiver
 SG_ VCFRONT_PCSCurrent m2 : 47|16@1- (0.1,0) [-3276.8|3276.7] "A"  Receiver
 SG_ VCFRONT_PCSFault m2 : 10|1@1+ (1,0) [0|1] ""  Receiver
 SG_ VCFRONT_PCSState m2 : 8|2@1+ (1,0) [0|2] ""  Receiver
 SG_ VCFRONT_PCSTemp m2 : 15|11@1+ (0.125,-40) [-40|150] "C"  Receiver
 SG_ VCFRONT_PCSVoltage m2 : 31|16@1+ (0.1,0) [0|6553.5] "V"  Receiver
 SG_ VCFRONT_autopilot1Current m8 : 43|16@1+ (0.1,0) [0|6553.5] "A"  Receiver
 SG_ VCFRONT_autopilot1Fault m8 : 10|1@1+ (1,0) [0|1] ""  Receiver
 SG_ VCFRONT_autopilot1State m8 : 8|2@1+ (1,0) [0|2] ""  Receiver
 SG_ VCFRONT_autopilot1Temp m8 : 11|11@1+ (0.125,-40) [-40|150] "C"  Receiver
 SG_ VCFRONT_autopilot1Voltage m8 : 27|16@1+ (0.1,0) [0|6553.5] "V"  Receiver
 SG_ VCFRONT_autopilot2Current m9 : 43|16@1+ (0.1,0) [0|6553.5] "A"  Receiver
 SG_ VCFRONT_autopilot2Fault m9 : 10|1@1+ (1,0) [0|1] ""  Receiver
 SG_ VCFRONT_autopilot2State m9 : 8|2@1+ (1,0) [0|2] ""  Receiver
 SG_ VCFRONT_autopilot2Temp m9 : 11|11@1+ (0.125,-40) [-40|150] "C"  Receiver
 SG_ VCFRONT_autopilot2Voltage m9 : 27|16@1+ (0.1,0) [0|6553.5] "V"  Receiver
 SG_ VCFRONT_chargedIBSAmpHours m17 : 8|16@1+ (1,0) [0|65535] "Ah"  Receiver
 SG_ VCFRONT_dischargedIBSAmpHours m17 : 24|16@1+ (1,0) [0|65535] "Ah"  Receiver
 SG_ VCFRONT_eFuseLockoutVoltage m16 : 8|12@1+ (0.00544368,0) [0|22.2919] "V"  Receiver
 SG_ VCFRONT_headlampLeftCurrent m12 : 10|10@1+ (0.1,0) [0|102.3] "A"  Receiver
 SG_ VCFRONT_headlampLeftFault m12 : 9|1@1+ (1,0) [0|1] ""  Receiver
 SG_ VCFRONT_headlampLeftState m12 : 8|1@1+ (1,0) [0|1] ""  Receiver
 SG_ VCFRONT_headlampLeftTemperature m12 : 48|8@1- (1,-40) [-40|150] "C"  Receiver
 SG_ VCFRONT_headlampLeftVoltage m12 : 20|8@1+ (0.1,0) [0|25.4] "V"  Receiver
 SG_ VCFRONT_headlampRightCurrent m12 : 30|10@1+ (0.1,0) [0|102.3] "A"  Receiver
 SG_ VCFRONT_headlampRightFault m12 : 29|1@1+ (1,0) [0|1] ""  Receiver
 SG_ VCFRONT_headlampRightState m12 : 28|1@1+ (1,0) [0|1] ""  Receiver
 SG_ VCFRONT_headlampRightTemperature m12 : 56|8@1- (1,-40) [-40|150] "C"  Receiver
 SG_ VCFRONT_headlampRightVoltage m12 : 40|8@1+ (0.1,0) [0|25.4] "V"  Receiver
 SG_ VCFRONT_iBoosterCurrent m3 : 47|16@1+ (0.1,0) [0|6553.5] "A"  Receiver
 SG_ VCFRONT_iBoosterFault m3 : 10|1@1+ (1,0) [0|1] ""  Receiver
 SG_ VCFRONT_iBoosterSelfTestResult m3 : 11|4@1+ (1,0) [0|11] ""  Receiver
 SG_ VCFRONT_iBoosterState m3 : 8|2@1+ (1,0) [0|2] ""  Receiver
 SG_ VCFRONT_iBoosterTemp m3 : 15|11@1+ (0.125,-40) [-40|150] "C"  Receiver
 SG_ VCFRONT_iBoosterVoltage m3 : 31|16@1+ (0.1,0) [0|6553.5] "V"  Receiver
 SG_ VCFRONT_leftControllerCurrent m1 : 47|16@1+ (0.1,0) [0|6553.5] "A"  Receiver
 SG_ VCFRONT_leftControllerFault m1 : 10|1@1+ (1,0) [0|1] ""  Receiver
 SG_ VCFRONT_leftControllerState m1 : 8|2@1+ (1,0) [0|2] ""  Receiver
 SG_ VCFRONT_leftControllerTemp m1 : 15|11@1+ (0.125,-40) [-40|150] "C"  Receiver
 SG_ VCFRONT_leftControllerVoltage m1 : 31|16@1+ (0.1,0) [0|6553.5] "V"  Receiver
 SG_ VCFRONT_pcsSelfTestResult m2 : 11|4@1+ (1,0) [0|11] ""  Receiver
 SG_ VCFRONT_pump1AndFanCurrent m14 : 6|16@1+ (0.1,0) [0|6553.5] "A"  Receiver
 SG_ VCFRONT_pump1AndFanState m14 : 5|1@1+ (1,0) [0|1] ""  Receiver
 SG_ VCFRONT_pump1AndFanVoltage m14 : 22|12@1+ (0.1,0) [0|409.5] "V"  Receiver
 SG_ VCFRONT_pump2AndAirCompCurrent m14 : 35|16@1+ (0.1,0) [0|6553.5] "A"  Receiver
 SG_ VCFRONT_pump2AndAirCompState m14 : 34|1@1+ (1,0) [0|1] ""  Receiver
 SG_ VCFRONT_pump2AndAirCompVoltage m14 : 51|12@1+ (0.1,0) [0|409.5] "V"  Receiver
 SG_ VCFRONT_railA_12v m15 : 8|12@1+ (0.00544368,0) [0|22.2919] "V"  Receiver
 SG_ VCFRONT_railA_5v m15 : 32|12@1+ (0.00544368,0) [0|22.2919] "V"  Receiver
 SG_ VCFRONT_railB_12v m15 : 20|12@1+ (0.00544368,0) [0|22.2919] "V"  Receiver
 SG_ VCFRONT_railB_5v m15 : 44|12@1+ (0.00544368,0) [0|22.2919] "V"  Receiver
 SG_ VCFRONT_rightControllerCurrent m0 : 47|16@1+ (0.1,0) [0|6553.5] "A"  Receiver
 SG_ VCFRONT_rightControllerFault m0 : 10|1@1+ (1,0) [0|1] ""  Receiver
 SG_ VCFRONT_rightControllerState m0 : 8|2@1+ (1,0) [0|2] ""  Receiver
 SG_ VCFRONT_rightControllerTemp m0 : 15|11@1+ (0.125,-40) [-40|150] "C"  Receiver
 SG_ VCFRONT_rightControllerVoltage m0 : 31|16@1+ (0.1,0) [0|6553.5] "V"  Receiver
 SG_ VCFRONT_sleepBypassCurrent m10 : 26|16@1+ (0.1,0) [0|6553.5] "A"  Receiver
 SG_ VCFRONT_sleepBypassFault m10 : 9|1@1+ (1,0) [0|1] ""  Receiver
 SG_ VCFRONT_sleepBypassState m10 : 8|1@1+ (1,0) [0|1] ""  Receiver
 SG_ VCFRONT_sleepBypassVoltage m10 : 10|16@1+ (0.1,0) [0|6553.5] "V"  Receiver
 SG_ VCFRONT_uiAudioCurrent m11 : 8|16@1+ (0.1,0) [0|6553.5] "A"  Receiver
 SG_ VCFRONT_uiAudioFault m11 : 6|1@1+ (1,0) [0|1] ""  Receiver
 SG_ VCFRONT_uiAudioState m11 : 5|1@1+ (1,0) [0|1] ""  Receiver
 SG_ VCFRONT_uiCurrent m11 : 32|16@1+ (0.1,0) [0|6553.5] "A"  Receiver
 SG_ VCFRONT_uiFault m11 : 25|1@1+ (1,0) [0|1] ""  Receiver
 SG_ VCFRONT_uiState m11 : 24|1@1+ (1,0) [0|1] ""  Receiver
 SG_ VCFRONT_vbatFusedHighCurrent m13 : 46|16@1+ (0.1,0) [0|6553.5] "A"  Receiver
 SG_ VCFRONT_vbatFusedHighFault m13 : 9|1@1+ (1,0) [0|1] ""  Receiver
 SG_ VCFRONT_vbatFusedHighState m13 : 8|1@1+ (1,0) [0|1] ""  Receiver
 SG_ VCFRONT_vbatFusedHighTemp m13 : 14|11@1+ (0.125,-40) [-40|150] "C"  Receiver
 SG_ VCFRONT_vbatFusedHighVoltage m13 : 30|16@1+ (0.1,0) [0|6553.5] "V"  Receiver
 SG_ VCFRONT_vbatFusedSelfTestResult m13 : 10|4@1+ (1,0) [0|11] ""  Receiver
 SG_ VCFRONT_vcleftSelfTestResult m1 : 11|4@1+ (1,0) [0|11] ""  Receiver
 SG_ VCFRONT_vcrightSelfTestResult m0 : 11|4@1+ (1,0) [0|11] ""  Receiver

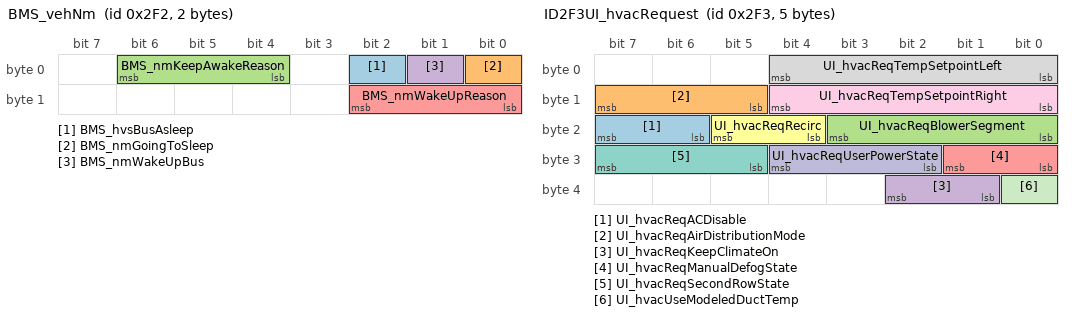
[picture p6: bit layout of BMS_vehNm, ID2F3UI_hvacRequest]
BO_ 754 BMS_vehNm: 2 VEH
 SG_ BMS_hvsBusAsleep: 2|1@1+ (1,0) [0|0] "" X
 SG_ BMS_nmGoingToSleep: 0|1@1+ (1,0) [0|0] "" X
 SG_ BMS_nmKeepAwakeReason: 4|3@1+ (1,0) [0|0] "" X
 SG_ BMS_nmWakeUpBus: 1|1@1+ (1,0) [0|0] "" X
 SG_ BMS_nmWakeUpReason: 8|3@1+ (1,0) [0|0] "" X

BO_ 755 ID2F3UI_hvacRequest: 5 VehicleBus
 SG_ UI_hvacReqACDisable : 22|2@1+ (1,0) [0|2] ""  Receiver
 SG_ UI_hvacReqAirDistributionMode : 13|3@1+ (1,0) [0|7] ""  Receiver
 SG_ UI_hvacReqBlowerSegment : 16|4@1+ (1,0) [0|11] ""  Receiver
 SG_ UI_hvacReqKeepClimateOn : 33|2@1+ (1,0) [0|3] ""  Receiver
 SG_ UI_hvacReqManualDefogState : 24|2@1+ (1,0) [0|2] ""  Receiver
 SG_ UI_hvacReqRecirc : 20|2@1+ (1,0) [0|2] ""  Receiver
 SG_ UI_hvacReqSecondRowState : 29|3@1+ (1,0) [0|4] ""  Receiver
 SG_ UI_hvacReqTempSetpointLeft : 0|5@1+ (0.5,15) [15|28] "C"  Receiver
 SG_ UI_hvacReqTempSetpointRight : 8|5@1+ (0.5,15) [15|28] "C"  Receiver
 SG_ UI_hvacReqUserPowerState : 26|3@1+ (1,0) [0|4] ""  Receiver
 SG_ UI_hvacUseModeledDuctTemp : 32|1@1+ (1,0) [0|1] ""  Receiver

BO_ 768 ID300BMS_info: 8 VehicleBus
 SG_ BMS_infoIndex M : 0|8@1+ (1,0) [0|255] ""  Receiver
 SG_ BMS_appCrc m13 : 32|32@1+ (1,0) [0|4294970000] ""  Receiver
 SG_ BMS_appGitHash m17 : 8|56@1+ (1,0) [0|7.20576E+016] ""  Receiver
 SG_ BMS_assemblyId m11 : 24|8@1+ (1,0) [0|255] ""  Receiver
 SG_ BMS_bootCrc m20 : 32|32@1+ (1,0) [0|4294970000] ""  Receiver
 SG_ BMS_bootGitHash m18 : 8|56@1+ (1,0) [0|7.20576E+016] ""  Receiver
 SG_ BMS_bootUdsProtoVersion m20 : 8|8@1+ (1,0) [0|255] ""  Receiver
 SG_ BMS_buildConfigId m10 : 16|16@1+ (1,0) [0|65535] ""  Receiver
 SG_ BMS_buildType m10 : 8|3@1+ (1,0) [0|4] ""  Receiver
 SG_ BMS_componentId m10 : 48|16@1+ (1,0) [0|65535] ""  Receiver
 SG_ BMS_hardwareId m10 : 32|16@1+ (1,0) [0|65535] ""  Receiver
 SG_ BMS_pcbaId m11 : 16|8@1+ (1,0) [0|255] ""  Receiver
 SG_ BMS_platformType m13 : 8|8@1+ (1,0) [0|255] ""  Receiver
 SG_ BMS_subUsageId m11 : 48|16@1+ (1,0) [0|65535] ""  Receiver
 SG_ BMS_usageId m11 : 32|16@1+ (1,0) [0|65535] ""  Receiver

BO_ 769 ID301VCFRONT_info: 8 VehicleBus
 SG_ VCFRONT_infoIndex M : 0|8@1+ (1,0) [0|255] ""  Receiver
 SG_ VCFRONT_hcmlAppCRC m16 : 32|32@1+ (1,0) [0|4294970000] ""  Receiver
 SG_ VCFRONT_hcmrAppCRC m23 : 32|32@1+ (1,0) [0|4294970000] ""  Receiver
 SG_ VCFRONT_infoAppCrc m13 : 8|32@1+ (1,0) [0|4294970000] ""  Receiver
 SG_ VCFRONT_infoAppGitHash m17 : 8|56@1+ (1,0) [0|7.20576E+016] ""  Receiver
 SG_ VCFRONT_infoAssemblyId m11 : 16|8@1+ (1,0) [0|255] ""  Receiver
 SG_ VCFRONT_infoBootCrc m20 : 24|32@1+ (1,0) [0|4294970000] ""  Receiver
 SG_ VCFRONT_infoBootGitHash m18 : 8|56@1+ (1,0) [0|7.20576E+016] ""  Receiver
 SG_ VCFRONT_infoBootUdsProtoVersion m20 : 8|16@1+ (1,0) [0|65535] ""  Receiver
 SG_ VCFRONT_infoBuildConfigId m10 : 16|16@1+ (1,0) [0|65535] ""  Receiver
 SG_ VCFRONT_infoBuildType m10 : 8|3@1+ (1,0) [0|4] ""  Receiver
 SG_ VCFRONT_infoComponentId m10 : 48|16@1+ (1,0) [0|65535] ""  Receiver
 SG_ VCFRONT_infoHardwareId m10 : 32|16@1+ (1,0) [0|65535] ""  Receiver
 SG_ VCFRONT_infoPcbaId m11 : 8|8@1+ (1,0) [0|255] ""  Receiver
 SG_ VCFRONT_infoPlatformType m19 : 8|8@1+ (1,0) [0|255] ""  Receiver
 SG_ VCFRONT_infoSubUsageId m11 : 40|16@1+ (1,0) [0|65535] ""  Receiver
 SG_ VCFRONT_infoSubcomponent3 m24 : 32|32@1+ (1,0) [0|4294970000] ""  Receiver
 SG_ VCFRONT_infoSubcomponent4 m31 : 32|32@1+ (1,0) [0|4294970000] ""  Receiver
 SG_ VCFRONT_infoSubcomponent5 m32 : 32|32@1+ (1,0) [0|4294970000] ""  Receiver
 SG_ VCFRONT_infoSubcomponent6 m33 : 32|32@1+ (1,0) [0|4294970000] ""  Receiver
 SG_ VCFRONT_infoUsageId m11 : 24|16@1+ (1,0) [0|65535] ""  Receiver

BO_ 770 VCLEFT_info: 8 VEH
 SG_ VCLEFT_infoIndex M: 0|8@1+ (1,0) [0|0] "" X
 SG_ VCLEFT_infoBuildType m10: 8|3@1+ (1,0) [0|0] "" X
 SG_ VCLEFT_infoBuildConfigId m10: 16|16@1+ (1,0) [0|0] "" X
 SG_ VCLEFT_infoHardwareId m10: 32|16@1+ (1,0) [0|0] "" X
 SG_ VCLEFT_infoComponentId m10: 48|16@1+ (1,0) [0|0] "" X
 SG_ VCLEFT_infoPcbaId m11: 8|8@1+ (1,0) [0|0] "" X
 SG_ VCLEFT_infoAssemblyId m11: 16|8@1+ (1,0) [0|0] "" X
 SG_ VCLEFT_infoUsageId m11: 24|16@1+ (1,0) [0|0] "" X
 SG_ VCLEFT_infoSubUsageId m11: 40|16@1+ (1,0) [0|0] "" X
 SG_ VCLEFT_infoAppCrc m13: 8|32@1+ (1,0) [0|0] "" X
 SG_ VCLEFT_infoSubcomponent1 m16: 32|32@1+ (1,0) [0|0] "" X
 SG_ VCLEFT_infoAppGitHash m17: 10|54@1+ (4,0) [0|0] "" X
 SG_ VCLEFT_infoBootGitHash m18: 10|54@1+ (4,0) [0|0] "" X
 SG_ VCLEFT_infoPlatformType m19: 8|8@1+ (1,0) [0|0] "" X
 SG_ VCLEFT_infoBootUdsProtoVersion m20: 8|16@1+ (1,0) [0|0] "" X
 SG_ VCLEFT_infoBootCrc m20: 24|32@1+ (1,0) [0|0] "" X
 SG_ VCLEFT_swcAppCRC m23: 32|32@1+ (1,0) [0|0] "" X
 SG_ VCLEFT_infoSubcomponent3 m24: 32|32@1+ (1,0) [0|0] "" X
 SG_ VCLEFT_infoCBCAppCRC m31: 32|32@1+ (1,0) [0|0] "" X

BO_ 771 OCS1P_status: 8 GTW
 SG_ OCS1P_occupiedState : 9|2@1+ (1,0) [0|3] "" ODIN

BO_ 772 PM_alertMatrix1: 8 VEH
 SG_ PM_a001_absoluteTorque: 0|1@1+ (1,0) [0|0] "" X
 SG_ PM_a002_accumulatedTorque: 1|1@1+ (1,0) [0|0] "" X
 SG_ PM_a003_torqueReversal: 2|1@1+ (1,0) [0|0] "" X
 SG_ PM_a004_regenTorque: 3|1@1+ (1,0) [0|0] "" X
 SG_ PM_a005_torqueInNeutral: 4|1@1+ (1,0) [0|0] "" X
 SG_ PM_a006_inconsistentDIGear: 5|1@1+ (1,0) [0|0] "" X
 SG_ PM_a007_watchdogReset: 6|1@1+ (1,0) [0|0] "" X
 SG_ PM_a008_memoryError: 7|1@1+ (1,0) [0|0] "" X
 SG_ PM_a009_espMIA: 8|1@1+ (1,0) [0|0] "" X
 SG_ PM_a010_diMIA: 9|1@1+ (1,0) [0|0] "" X
 SG_ PM_a011_phaseCurrentIrrational: 10|1@1+ (1,0) [0|0] "" X
 SG_ PM_a012_canDataBusA: 11|1@1+ (1,0) [0|0] "" X
 SG_ PM_a013_canHardwareBusA: 12|1@1+ (1,0) [0|0] "" X
 SG_ PM_a014_accelPedalError: 13|1@1+ (1,0) [0|0] "" X
 SG_ PM_a015_shifterMIA: 14|1@1+ (1,0) [0|0] "" X
 SG_ PM_a016_cruiseMIA: 15|1@1+ (1,0) [0|0] "" X
 SG_ PM_a017_brakeMIA: 16|1@1+ (1,0) [0|0] "" X
 SG_ PM_a018_encoderIrrational: 17|1@1+ (1,0) [0|0] "" X
 SG_ PM_a019_statorTempIrrational: 18|1@1+ (1,0) [0|0] "" X
 SG_ PM_a023_crsCmdOffStateOn: 22|1@1+ (1,0) [0|0] "" X
 SG_ PM_a024_brakeIrrational: 23|1@1+ (1,0) [0|0] "" X
 SG_ PM_a026_diHeartBeatMIA: 25|1@1+ (1,0) [0|0] "" X
 SG_ PM_a027_torqueOutOfMap: 26|1@1+ (1,0) [0|0] "" X
 SG_ PM_a028_torqueCmdError: 27|1@1+ (1,0) [0|0] "" X
 SG_ PM_a030_inconsistentAebState: 29|1@1+ (1,0) [0|0] "" X
 SG_ PM_a031_highStackUsage: 30|1@1+ (1,0) [0|0] "" X
 SG_ PM_a032_registerConfigError: 31|1@1+ (1,0) [0|0] "" X
 SG_ PM_a033_selfTest: 32|1@1+ (1,0) [0|0] "" X
 SG_ PM_a034_trqCrossCheck: 33|1@1+ (1,0) [0|0] "" X
 SG_ PM_a038_inconsistentTorqueSign: 37|1@1+ (1,0) [0|0] "" X
 SG_ PM_a039_disMIA: 38|1@1+ (1,0) [0|0] "" X
 SG_ PM_a040_pmMIA: 39|1@1+ (1,0) [0|0] "" X
 SG_ PM_a041_dasMIA: 40|1@1+ (1,0) [0|0] "" X
 SG_ PM_a042_gtwMIA: 41|1@1+ (1,0) [0|0] "" X
 SG_ PM_a043_inconsistentConfig: 42|1@1+ (1,0) [0|0] "" X
 SG_ PM_a044_ebrIntervention: 43|1@1+ (1,0) [0|0] "" X
 SG_ PM_a045_motorMovementDetected: 44|1@1+ (1,0) [0|0] "" X
 SG_ PM_a046_inconsVehicleHoldState: 45|1@1+ (1,0) [0|0] "" X
 SG_ PM_a047_inconsAutoparkState: 46|1@1+ (1,0) [0|0] "" X
 SG_ PM_a048_stabilityControlInhibit: 47|1@1+ (1,0) [0|0] "" X
 SG_ PM_a049_stbCtrlInWrongDir: 48|1@1+ (1,0) [0|0] "" X
 SG_ PM_a050_excessiveStbCtrlTrq: 49|1@1+ (1,0) [0|0] "" X
 SG_ PM_a051_unintDecelStbCtrl: 50|1@1+ (1,0) [0|0] "" X
 SG_ PM_a052_stbCtrlDrvrDecelCflct: 51|1@1+ (1,0) [0|0] "" X
 SG_ PM_a053_vcfrontMIA: 52|1@1+ (1,0) [0|0] "" X
 SG_ PM_a054_uiMIA: 53|1@1+ (1,0) [0|0] "" X
 SG_ PM_a055_resolver: 54|1@1+ (1,0) [0|0] "" X
 SG_ PM_a056_canHardwareBusB: 55|1@1+ (1,0) [0|0] "" X
 SG_ PM_a057_canDataBusB: 56|1@1+ (1,0) [0|0] "" X
 SG_ PM_a058_cmpMIA: 57|1@1+ (1,0) [0|0] "" X
 SG_ PM_a059_ptcMIA: 58|1@1+ (1,0) [0|0] "" X
 SG_ PM_a061_DIPMVersionMismatch: 60|1@1+ (1,0) [0|0] "" X
 SG_ PM_a063_debugAlert: 62|1@1+ (1,0) [0|0] "" X
 SG_ PM_a064_torqueIntervention: 63|1@1+ (1,0) [0|0] "" X

BO_ 774 VCRIGHT_info: 8 VEH
 SG_ VCRIGHT_infoIndex M: 0|8@1+ (1,0) [0|0] "" X
 SG_ VCRIGHT_infoBuildType m10: 8|3@1+ (1,0) [0|0] "" X
 SG_ VCRIGHT_infoBuildConfigId m10: 16|16@1+ (1,0) [0|0] "" X
 SG_ VCRIGHT_infoHardwareId m10: 32|16@1+ (1,0) [0|0] "" X
 SG_ VCRIGHT_infoComponentId m10: 48|16@1+ (1,0) [0|0] "" X
 SG_ VCRIGHT_infoPcbaId m11: 8|8@1+ (1,0) [0|0] "" X
 SG_ VCRIGHT_infoAssemblyId m11: 16|8@1+ (1,0) [0|0] "" X
 SG_ VCRIGHT_infoUsageId m11: 24|16@1+ (1,0) [0|0] "" X
 SG_ VCRIGHT_infoSubUsageId m11: 40|16@1+ (1,0) [0|0] "" X
 SG_ VCRIGHT_infoAppCrc m13: 8|32@1+ (1,0) [0|0] "" X
 SG_ VCRIGHT_infoAppGitHash m17: 10|54@1+ (4,0) [0|0] "" X
 SG_ VCRIGHT_infoBootGitHash m18: 10|54@1+ (4,0) [0|0] "" X
 SG_ VCRIGHT_infoPlatformType m19: 8|8@1+ (1,0) [0|0] "" X
 SG_ VCRIGHT_infoBootUdsProtoVersion m20: 8|16@1+ (1,0) [0|0] "" X
 SG_ VCRIGHT_infoBootCrc m20: 24|32@1+ (1,0) [0|0] "" X

BO_ 777 ID309DAS_object: 8 VehicleBus
 SG_ DAS_objectId M : 0|3@1+ (1,0) [0|5] ""  Receiver
 SG_ DAS_cutinVehDx m3 : 8|8@1+ (0.5,0) [0|127] "m"  Receiver
 SG_ DAS_cutinVehDy m3 : 20|7@1+ (0.35,-22.05) [-22.05|22.4] "m"  Receiver
 SG_ DAS_cutinVehHeading m5 : 56|8@1+ (0.0245437,-3.14159) [-3.14159|3.09251] "rad"  Receiver
 SG_ DAS_cutinVehId m3 : 27|7@1+ (1,0) [0|127] ""  Receiver
 SG_ DAS_cutinVehRelevantForControl m3 : 7|1@1+ (1,0) [0|1] ""  Receiver
 SG_ DAS_cutinVehType m3 : 3|3@1+ (1,0) [0|5] ""  Receiver
 SG_ DAS_cutinVehVxRel m3 : 16|4@1+ (4,-30) [-30|26] "m/s"  Receiver
 SG_ DAS_leadVeh2Dx m0 : 39|8@1+ (0.5,0) [0|127] "m"  Receiver
 SG_ DAS_leadVeh2Dy m0 : 51|7@1+ (0.35,-22.05) [-22.05|22.4] "m"  Receiver
 SG_ DAS_leadVeh2Heading m5 : 16|8@1+ (0.0245437,-3.14159) [-3.14159|3.09251] "rad"  Receiver
 SG_ DAS_leadVeh2Id m0 : 58|6@1+ (1,0) [0|63] ""  Receiver
 SG_ DAS_leadVeh2RelevantForControl m0 : 38|1@1+ (1,0) [0|1] ""  Receiver
 SG_ DAS_leadVeh2Type m0 : 34|3@1+ (1,0) [0|5] ""  Receiver
 SG_ DAS_leadVeh2VxRel m0 : 47|4@1+ (4,-30) [-30|26] "m/s"  Receiver
 SG_ DAS_leadVehDx m0 : 8|8@1+ (0.5,0) [0|127] "m"  Receiver
 SG_ DAS_leadVehDy m0 : 20|7@1+ (0.35,-22.05) [-22.05|22.4] "m"  Receiver
 SG_ DAS_leadVehHeading m5 : 8|8@1+ (0.0245437,-3.14159) [-3.14159|3.09251] "rad"  Receiver
 SG_ DAS_leadVehId m0 : 27|7@1+ (1,0) [0|127] ""  Receiver
 SG_ DAS_leadVehRelevantForControl m0 : 7|1@1+ (1,0) [0|1] ""  Receiver
 SG_ DAS_leadVehType m0 : 3|3@1+ (1,0) [0|6] ""  Receiver
 SG_ DAS_leadVehVxRel m0 : 16|4@1+ (4,-30) [-30|26] "m/s"  Receiver
 SG_ DAS_leftVeh2Dx m1 : 39|8@1+ (0.5,0) [0|127] "m"  Receiver
 SG_ DAS_leftVeh2Dy m1 : 51|7@1+ (0.35,-22.05) [-22.05|22.4] "m"  Receiver
 SG_ DAS_leftVeh2Heading m5 : 32|8@1+ (0.0245437,-3.14159) [-3.14159|3.09251] "rad"  Receiver
 SG_ DAS_leftVeh2Id m1 : 58|6@1+ (1,0) [0|63] ""  Receiver
 SG_ DAS_leftVeh2RelevantForControl m1 : 38|1@1+ (1,0) [0|1] ""  Receiver
 SG_ DAS_leftVeh2Type m1 : 34|3@1+ (1,0) [0|5] ""  Receiver
 SG_ DAS_leftVeh2VxRel m1 : 47|4@1+ (4,-30) [-30|26] "m/s"  Receiver
 SG_ DAS_leftVehDx m1 : 8|8@1+ (0.5,0) [0|127] "m"  Receiver
 SG_ DAS_leftVehDy m1 : 20|7@1+ (0.35,-22.05) [-22.05|22.4] "m"  Receiver
 SG_ DAS_leftVehHeading m5 : 24|8@1+ (0.0245437,-3.14159) [-3.14159|3.09251] "rad"  Receiver
 SG_ DAS_leftVehId m1 : 27|7@1+ (1,0) [0|127] ""  Receiver
 SG_ DAS_leftVehRelevantForControl m1 : 7|1@1+ (1,0) [0|1] ""  Receiver
 SG_ DAS_leftVehType m1 : 3|3@1+ (1,0) [0|5] ""  Receiver
 SG_ DAS_leftVehVxRel m1 : 16|4@1+ (4,-30) [-30|26] "m/s"  Receiver
 SG_ DAS_rightVeh2Dx m2 : 39|8@1+ (0.5,0) [0|127] "m"  Receiver
 SG_ DAS_rightVeh2Dy m2 : 51|7@1+ (0.35,-22.05) [-22.05|22.4] "m"  Receiver
 SG_ DAS_rightVeh2Heading m5 : 48|8@1+ (0.0245437,-3.14159) [-3.14159|3.09251] "rad"  Receiver
 SG_ DAS_rightVeh2Id m2 : 58|6@1+ (1,0) [0|63] ""  Receiver
 SG_ DAS_rightVeh2RelevantForControl m2 : 38|1@1+ (1,0) [0|1] ""  Receiver
 SG_ DAS_rightVeh2Type m2 : 34|3@1+ (1,0) [0|5] ""  Receiver
 SG_ DAS_rightVeh2VxRel m2 : 47|4@1+ (4,-30) [-30|26] "m/s"  Receiver
 SG_ DAS_rightVehDx m2 : 8|8@1+ (0.5,0) [0|127] "m"  Receiver
 SG_ DAS_rightVehDy m2 : 20|7@1+ (0.35,-22.05) [-22.05|22.4] "m"  Receiver
 SG_ DAS_rightVehHeading m5 : 40|8@1+ (0.0245437,-3.14159) [-3.14159|3.09251] "rad"  Receiver
 SG_ DAS_rightVehId m2 : 27|7@1+ (1,0) [0|127] ""  Receiver
 SG_ DAS_rightVehRelevantForControl m2 : 7|1@1+ (1,0) [0|1] ""  Receiver
 SG_ DAS_rightVehType m2 : 3|3@1+ (1,0) [0|5] ""  Receiver
 SG_ DAS_rightVehVxRel m2 : 16|4@1+ (4,-30) [-30|26] "m/s"  Receiver
 SG_ DAS_roadSignArrow m4 : 27|3@1+ (1,0) [0|4] ""  Receiver
 SG_ DAS_roadSignColor m4 : 3|3@1+ (1,0) [0|4] ""  Receiver
 SG_ DAS_roadSignControlActive m4 : 24|1@1+ (1,0) [0|1] ""  Receiver
 SG_ DAS_roadSignId m4 : 6|8@1+ (1,0) [0|255] ""  Receiver
 SG_ DAS_roadSignOrientation m4 : 30|2@1+ (1,0) [0|2] ""  Receiver
 SG_ DAS_roadSignSource m4 : 25|2@1+ (1,0) [0|2] ""  Receiver
 SG_ DAS_roadSignStopLineDist m4 : 14|10@1+ (0.2,-20) [-20|184.4] "m"  Receiver

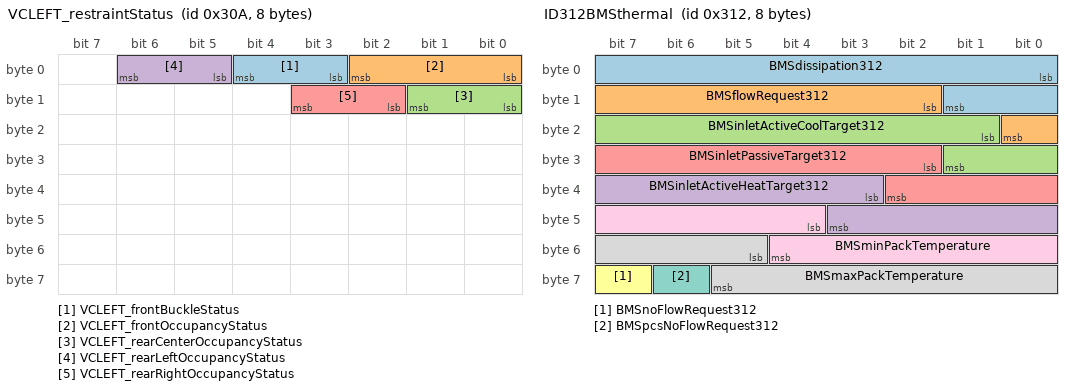
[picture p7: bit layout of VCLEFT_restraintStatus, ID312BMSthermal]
BO_ 778 VCLEFT_restraintStatus: 8 GTW
 SG_ VCLEFT_frontBuckleStatus : 3|2@1+ (1,0) [0|3] "" ODIN,SUI,UI
 SG_ VCLEFT_frontOccupancyStatus : 0|3@1+ (1,0) [0|7] "" ODIN,SUI,UI
 SG_ VCLEFT_rearCenterOccupancyStatus : 8|2@1+ (1,0) [0|3] "" ODIN,SUI,UI
 SG_ VCLEFT_rearLeftOccupancyStatus : 5|2@1+ (1,0) [0|3] "" ODIN,SUI,UI
 SG_ VCLEFT_rearRightOccupancyStatus : 10|2@1+ (1,0) [0|3] "" ODIN,SUI,UI

BO_ 782 PARK_status2: 8 GTW
 SG_ PARK_sdiActive : 24|1@1+ (1,0) [0|1] "" ODIN,SUI,UI

BO_ 784 HVP_info: 8 VEH
 SG_ HVP_infoIndex M: 0|8@1+ (1,0) [0|0] "" X
 SG_ HVP_buildType m10: 8|3@1+ (1,0) [0|0] "" X
 SG_ HVP_buildConfigId m10: 16|16@1+ (1,0) [0|0] "" X
 SG_ HVP_hardwareId m10: 32|16@1+ (1,0) [0|0] "" X
 SG_ HVP_componentId m10: 48|16@1+ (1,0) [0|0] "" X
 SG_ HVP_pcbaId m11: 16|8@1+ (1,0) [0|0] "" X
 SG_ HVP_assemblyId m11: 24|8@1+ (1,0) [0|0] "" X
 SG_ HVP_usageId m11: 32|16@1+ (1,0) [0|0] "" X
 SG_ HVP_subUsageId m11: 48|16@1+ (1,0) [0|0] "" X
 SG_ HVP_platformType m13: 8|8@1+ (1,0) [0|0] "" X
 SG_ HVP_appCrc m13: 32|32@1+ (1,0) [0|0] "" X
 SG_ HVP_appGitHash m17: 10|54@1+ (4,0) [0|0] "" X
 SG_ HVP_bootGitHash m18: 10|54@1+ (4,0) [0|0] "" X
 SG_ HVP_bootUdsProtoVersion m20: 8|8@1+ (1,0) [0|0] "" X
 SG_ HVP_bootCrc m20: 32|32@1+ (1,0) [0|0] "" X

BO_ 785 EPAS3S_info: 8 CH
 SG_ EPAS3S_infoIndex M: 0|8@1+ (1,0) [0|0] "" X
 SG_ EPAS3S_infoBuildType m10: 8|8@1+ (1,0) [0|0] "" X
 SG_ EPAS3S_infoComponentID m10: 48|16@1+ (1,0) [0|0] "" X
 SG_ EPAS3S_infoPcbaID m11: 16|8@1+ (1,0) [0|0] "" X
 SG_ EPAS3S_infoAssemblyID m11: 24|8@1+ (1,0) [0|0] "" X
 SG_ EPAS3S_infoUsageID m11: 32|16@1+ (1,0) [0|0] "" X
 SG_ EPAS3S_infoBootUdsProtoVersion m20: 8|8@1+ (1,0) [0|0] "" X
 SG_ EPAS3S_infoBootloaderCRC m20: 32|32@1+ (1,0) [0|0] "" X
 SG_ EPAS3S_infoApplicationCRC m13: 32|32@1+ (1,0) [0|0] "" X

BO_ 786 ID312BMSthermal: 8 VehicleBus
 SG_ BMSdissipation312 : 0|10@1+ (0.02,0) [0|20] "kW"  Receiver
 SG_ BMSflowRequest312 : 10|7@1+ (0.3,0) [0|30] "LPM"  Receiver
 SG_ BMSinletActiveCoolTarget312 : 17|9@1+ (0.25,-25) [-25|100] "C"  Receiver
 SG_ BMSinletActiveHeatTarget312 : 35|9@1+ (0.25,-25) [-25|100] "C"  Receiver
 SG_ BMSinletPassiveTarget312 : 26|9@1+ (0.25,-25) [-25|100] "C"  Receiver
 SG_ BMSnoFlowRequest312 : 63|1@1+ (1,0) [0|1] ""  Receiver
 SG_ BMSpcsNoFlowRequest312 : 62|1@1+ (1,0) [0|1] ""  Receiver
 SG_ BMSmaxPackTemperature : 53|9@1+ (0.25,-25) [-25|100] "C"  Receiver
 SG_ BMSminPackTemperature : 44|9@1+ (0.25,-25) [-25|100] "C"  Receiver

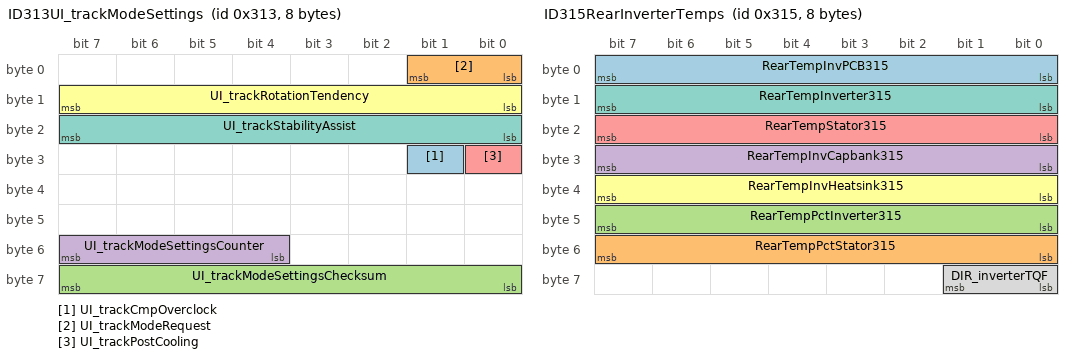
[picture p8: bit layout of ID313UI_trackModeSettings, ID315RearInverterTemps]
BO_ 787 ID313UI_trackModeSettings: 8 VehicleBus
 SG_ UI_trackCmpOverclock : 25|1@1+ (1,0) [0|1] ""  Receiver
 SG_ UI_trackModeRequest : 0|2@1+ (1,0) [0|2] ""  Receiver
 SG_ UI_trackModeSettingsChecksum : 56|8@1+ (1,0) [0|255] ""  Receiver
 SG_ UI_trackModeSettingsCounter : 52|4@1+ (1,0) [0|15] ""  Receiver
 SG_ UI_trackPostCooling : 24|1@1+ (1,0) [0|1] ""  Receiver
 SG_ UI_trackRotationTendency : 8|8@1+ (0.5,0) [0|100] "%"  Receiver
 SG_ UI_trackStabilityAssist : 16|8@1+ (0.5,0) [0|100] "%"  Receiver

BO_ 789 ID315RearInverterTemps: 8 VehicleBus
 SG_ RearTempInvPCB315 : 0|8@1+ (1,-40) [-40|215] "C"  Receiver
 SG_ RearTempPctStator315 : 48|8@1+ (0.4,0) [0|102] "%"  Receiver
 SG_ RearTempPctInverter315 : 40|8@1+ (0.4,0) [0|102] "%"  Receiver
 SG_ RearTempInvCapbank315 : 24|8@1+ (1,-40) [-40|215] "C"  Receiver
 SG_ RearTempStator315 : 16|8@1+ (1,-40) [-40|215] "C"  Receiver
 SG_ RearTempInvHeatsink315 : 32|8@1+ (1,-40) [-40|215] "C"  Receiver
 SG_ RearTempInverter315 : 8|8@1+ (1,-40) [-40|215] "C"  Receiver
 SG_ DIR_inverterTQF : 56|2@1+ (1,0) [0|3] ""  Receiver

BO_ 790 PM_info: 8 VEH
 SG_ PM_infoIndex M: 0|8@1+ (1,0) [0|0] "" X
 SG_ PM_buildType m10: 8|8@1+ (1,0) [0|0] "" X
 SG_ PM_buildConfigurationId m10: 16|16@1+ (1,0) [0|0] "" X
 SG_ PM_hardwareId m10: 32|8@1+ (1,0) [0|0] "" X
 SG_ PM_componentId m10: 48|16@1+ (1,0) [0|0] "" X
 SG_ PM_pcbaId m11: 16|8@1+ (1,0) [0|0] "" X
 SG_ PM_assemblyId m11: 24|8@1+ (1,0) [0|0] "" X
 SG_ PM_usageId m11: 32|16@1+ (1,0) [0|0] "" X
 SG_ PM_subUsageId m11: 48|16@1+ (1,0) [0|0] "" X
 SG_ PM_applicationCrc m13: 32|32@1+ (1,0) [0|0] "" X
 SG_ PM_bootloaderSvnRevision m14: 8|24@1+ (1,0) [0|0] "" X
 SG_ PM_bootloaderSvnUrlHash m14: 32|32@1+ (1,0) [0|0] "" X
 SG_ PM_appGitHash m17: 10|54@1+ (4,0) [0|0] "" X
 SG_ PM_bootGitHash m18: 10|54@1+ (4,0) [0|0] "" X
 SG_ PM_platformTyp m19: 8|8@1+ (1,0) [0|0] "" X
 SG_ PM_udsProtocolVersion m20: 8|8@1+ (1,0) [0|0] "" X
 SG_ PM_bootloaderCrc m20: 32|32@1+ (1,0) [0|0] "" X

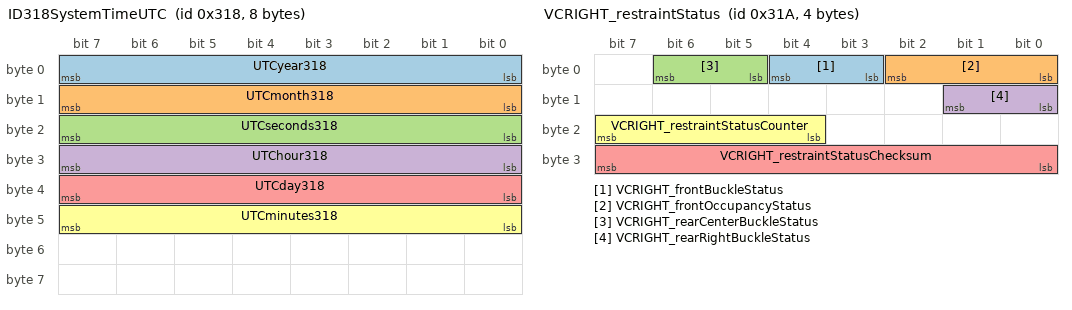
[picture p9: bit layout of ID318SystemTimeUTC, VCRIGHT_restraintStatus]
BO_ 792 ID318SystemTimeUTC: 8 VehicleBus
 SG_ UTCyear318 : 0|8@1+ (1,0) [0|0] "yr"  Receiver
 SG_ UTCmonth318 : 8|8@1+ (1,0) [0|0] "mo"  Receiver
 SG_ UTCseconds318 : 16|8@1+ (1,0) [0|0] "sec"  Receiver
 SG_ UTChour318 : 24|8@1+ (1,0) [0|0] "hr"  Receiver
 SG_ UTCday318 : 32|8@1+ (1,0) [0|0] "dy"  Receiver
 SG_ UTCminutes318 : 40|8@1+ (1,0) [0|0] "min"  Receiver

BO_ 793 VCSEC_info: 8 VEH
 SG_ VCSEC_infoIndex M: 0|8@1+ (1,0) [0|0] "" X
 SG_ VCSEC_infoBuildType m10: 8|3@1+ (1,0) [0|0] "" X
 SG_ VCSEC_infoBuildConfigId m10: 16|16@1+ (1,0) [0|0] "" X
 SG_ VCSEC_infoHardwareId m10: 32|16@1+ (1,0) [0|0] "" X
 SG_ VCSEC_infoComponentId m10: 48|16@1+ (1,0) [0|0] "" X
 SG_ VCSEC_infoPcbaId m11: 8|8@1+ (1,0) [0|0] "" X
 SG_ VCSEC_infoAssemblyId m11: 16|8@1+ (1,0) [0|0] "" X
 SG_ VCSEC_infoUsageId m11: 32|16@1+ (1,0) [0|0] "" X
 SG_ VCSEC_infoSubUsageId m11: 48|16@1+ (1,0) [0|0] "" X
 SG_ VCSEC_infoAppCrc m13: 32|32@1+ (1,0) [0|0] "" X
 SG_ VCSEC_infoSubcomponent1 m16: 32|32@1+ (1,0) [0|0] "" X
 SG_ VCSEC_infoAppGitHash m17: 10|54@1+ (4,0) [0|0] "" X
 SG_ VCSEC_infoBootGitHash m18: 10|54@1+ (4,0) [0|0] "" X
 SG_ VCSEC_infoPlatformType m19: 8|8@1+ (1,0) [0|0] "" X
 SG_ VCSEC_infoBootUdsProtoVersion m20: 8|16@1+ (1,0) [0|0] "" X
 SG_ VCSEC_infoBootCrc m20: 24|32@1+ (1,0) [0|0] "" X
 SG_ VCSEC_infoSubcomponent2 m23: 32|32@1+ (1,0) [0|0] "" X
 SG_ VCSEC_infoSubcomponent3 m24: 32|32@1+ (1,0) [0|0] "" X
 SG_ VCSEC_infoSubcomponent4 m31: 32|32@1+ (1,0) [0|0] "" X

BO_ 794 VCRIGHT_restraintStatus: 4 VEH
 SG_ VCRIGHT_frontBuckleStatus: 3|2@1+ (1,0) [0|0] "" X
 SG_ VCRIGHT_frontOccupancyStatus: 0|3@1+ (1,0) [0|0] "" X
 SG_ VCRIGHT_rearCenterBuckleStatus: 5|2@1+ (1,0) [0|0] "" X
 SG_ VCRIGHT_rearRightBuckleStatus: 8|2@1+ (1,0) [0|0] "" X
 SG_ VCRIGHT_restraintStatusChecksum: 24|8@1+ (1,0) [0|0] "" X
 SG_ VCRIGHT_restraintStatusCounter: 20|4@1+ (1,0) [0|0] "" X

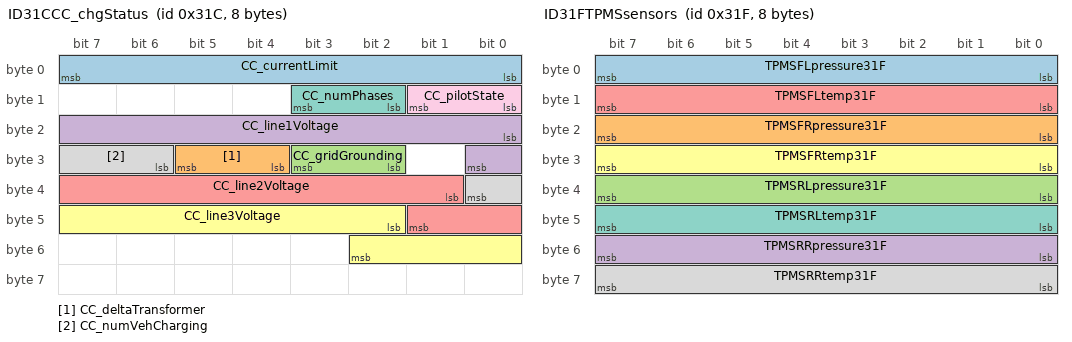
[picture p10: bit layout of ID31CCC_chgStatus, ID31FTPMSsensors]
BO_ 796 ID31CCC_chgStatus: 8 VehicleBus
 SG_ CC_currentLimit : 0|8@1+ (0.5,0) [0|127.5] "A"  Receiver
 SG_ CC_deltaTransformer : 28|2@1+ (1,0) [0|3] ""  Receiver
 SG_ CC_gridGrounding : 26|2@1+ (1,0) [0|2] ""  Receiver
 SG_ CC_line1Voltage : 16|9@1+ (1,0) [0|511] "V"  Receiver
 SG_ CC_line2Voltage : 33|9@1+ (1,0) [0|511] "V"  Receiver
 SG_ CC_line3Voltage : 42|9@1+ (1,0) [0|511] "V"  Receiver
 SG_ CC_numPhases : 10|2@1+ (1,0) [0|3] ""  Receiver
 SG_ CC_numVehCharging : 30|3@1+ (1,0) [0|7] ""  Receiver
 SG_ CC_pilotState : 8|2@1+ (1,0) [0|3] ""  Receiver

BO_ 797 CC_chgStatus2: 8 VEH
 SG_ CC_chgStatus2Index M: 0|8@1+ (1,0) [0|0] "" X
 SG_ CC_buttonState m0: 8|1@1+ (1,0) [0|0] "" X

BO_ 798 CP_alertMatrix: 8 VEH
 SG_ CP_matrixIndex M: 0|4@1+ (1,0) [0|0] "" X
 SG_ CP_a001_canRx m0: 4|1@1+ (1,0) [0|0] "" X
 SG_ CP_a002_canTx m0: 5|1@1+ (1,0) [0|0] "" X
 SG_ CP_a003_canError m0: 6|1@1+ (1,0) [0|0] "" X
 SG_ CP_a004_proximityRationality m0: 7|1@1+ (1,0) [0|0] "" X
 SG_ CP_a005_gbdcLiveDisconnect m0: 8|1@1+ (1,0) [0|0] "" X
 SG_ CP_a006_lostCommsBMS m0: 9|1@1+ (1,0) [0|0] "" X
 SG_ CP_a007_watchdog m0: 10|1@1+ (1,0) [0|0] "" X
 SG_ CP_a008_memoryError m0: 11|1@1+ (1,0) [0|0] "" X
 SG_ CP_a009_coverOpen m0: 12|1@1+ (1,0) [0|0] "" X
 SG_ CP_a010_pilotRationality m0: 13|1@1+ (1,0) [0|0] "" X
 SG_ CP_a011_eeprom m0: 14|1@1+ (1,0) [0|0] "" X
 SG_ CP_a012_ledDriver m0: 15|1@1+ (1,0) [0|0] "" X
 SG_ CP_a013_lostCommsGTW m0: 16|1@1+ (1,0) [0|0] "" X
 SG_ CP_a014_lostCommsCHG m0: 17|1@1+ (1,0) [0|0] "" X
 SG_ CP_a015_apsVov m0: 18|1@1+ (1,0) [0|0] "" X
 SG_ CP_a016_apsVuv m0: 19|1@1+ (1,0) [0|0] "" X
 SG_ CP_a017_fiveVov m0: 20|1@1+ (1,0) [0|0] "" X
 SG_ CP_a018_fiveVuv m0: 21|1@1+ (1,0) [0|0] "" X
 SG_ CP_a019_threeVov m0: 22|1@1+ (1,0) [0|0] "" X
 SG_ CP_a020_threeVuv m0: 23|1@1+ (1,0) [0|0] "" X
 SG_ CP_a021_zeroVov m0: 24|1@1+ (1,0) [0|0] "" X
 SG_ CP_a022_zeroVuv m0: 25|1@1+ (1,0) [0|0] "" X
 SG_ CP_a023_gbdcSessionFailed m0: 26|1@1+ (1,0) [0|0] "" X
 SG_ CP_a024_ledsUC m0: 27|1@1+ (1,0) [0|0] "" X
 SG_ CP_a025_ledsOC m0: 28|1@1+ (1,0) [0|0] "" X
 SG_ CP_a026_networkManagement m0: 29|1@1+ (1,0) [0|0] "" X
 SG_ CP_a027_doorSensorOutOfSpec m0: 30|1@1+ (1,0) [0|0] "" X
 SG_ CP_a028_insertEnableMismatch m0: 31|1@1+ (1,0) [0|0] "" X
 SG_ CP_a029_doorClosedProxPilot m0: 32|1@1+ (1,0) [0|0] "" X
 SG_ CP_a030_busOff m0: 33|1@1+ (1,0) [0|0] "" X
 SG_ CP_a031_doorClosedCommandedOpen m0: 34|1@1+ (1,0) [0|0] "" X
 SG_ CP_a032_doorOpenExpectedClosed m0: 35|1@1+ (1,0) [0|0] "" X
 SG_ CP_a033_spiOpen m0: 36|1@1+ (1,0) [0|0] "" X
 SG_ CP_a034_calibrationIncomplete m0: 37|1@1+ (1,0) [0|0] "" X
 SG_ CP_a035_latchMovement_1 m0: 38|1@1+ (1,0) [0|0] "" X
 SG_ CP_a036_latchNotDisengaged m0: 39|1@1+ (1,0) [0|0] "" X
 SG_ CP_a037_latchNotEngaged m0: 40|1@1+ (1,0) [0|0] "" X
 SG_ CP_a038_latchNotBlocking m0: 41|1@1+ (1,0) [0|0] "" X
 SG_ CP_a039_latchMovement_2 m0: 42|1@1+ (1,0) [0|0] "" X
 SG_ CP_a040_doNotUse m0: 43|1@1+ (1,0) [0|0] "" X
 SG_ CP_a041_doorSensorUnplugged m0: 44|1@1+ (1,0) [0|0] "" X
 SG_ CP_a042_doorAssemblyBroken m0: 45|1@1+ (1,0) [0|0] "" X
 SG_ CP_a043_doorPotIrrational m0: 46|1@1+ (1,0) [0|0] "" X
 SG_ CP_a044_lostCommsHVP m0: 47|1@1+ (1,0) [0|0] "" X
 SG_ CP_a045_lostCommsVCSEC m0: 48|1@1+ (1,0) [0|0] "" X
 SG_ CP_a046_lostCommsEVSE m0: 49|1@1+ (1,0) [0|0] "" X
 SG_ CP_a047_lostCommsVCFRONT m0: 50|1@1+ (1,0) [0|0] "" X
 SG_ CP_a048_lostCommsUI m0: 51|1@1+ (1,0) [0|0] "" X
 SG_ CP_a049_multipleCablesDetected m0: 52|1@1+ (1,0) [0|0] "" X
 SG_ CP_a050_latchNotConnected m0: 53|1@1+ (1,0) [0|0] "" X
 SG_ CP_a051_doorInductiveSensorMIA m0: 54|1@1+ (1,0) [0|0] "" X
 SG_ CP_a052_evseNotSupported m0: 55|1@1+ (1,0) [0|0] "" X
 SG_ CP_a053_proxLatchedNoPilot m0: 56|1@1+ (1,0) [0|0] "" X
 SG_ CP_a054_cableNotSecured m0: 57|1@1+ (1,0) [0|0] "" X
 SG_ CP_a055_chargeStoppedNoPilot m0: 58|1@1+ (1,0) [0|0] "" X
 SG_ CP_a056_proxDisconnected m0: 59|1@1+ (1,0) [0|0] "" X
 SG_ CP_a057_evseFaulted m0: 60|1@1+ (1,0) [0|0] "" X
 SG_ CP_a058_acChargingBlocked m0: 61|1@1+ (1,0) [0|0] "" X
 SG_ CP_a059_swcanError m0: 62|1@1+ (1,0) [0|0] "" X
 SG_ CP_a060_lostCommsPCS m0: 63|1@1+ (1,0) [0|0] "" X
 SG_ CP_a061_uhfReceiverMIA m1: 4|1@1+ (1,0) [0|0] "" X
 SG_ CP_a062_scOutOfService m1: 5|1@1+ (1,0) [0|0] "" X
 SG_ CP_a063_scUpdateInProgress m1: 6|1@1+ (1,0) [0|0] "" X
 SG_ CP_a064_superchargingBlocked m1: 7|1@1+ (1,0) [0|0] "" X
 SG_ CP_a065_selfTestFailed m1: 8|1@1+ (1,0) [0|0] "" X
 SG_ CP_a066_proxLatchedIdlePilot m1: 9|1@1+ (1,0) [0|0] "" X
 SG_ CP_a067_gbdcConnFault m1: 10|1@1+ (1,0) [0|0] "" X
 SG_ CP_a068_doorSensorMismatch m1: 11|1@1+ (1,0) [0|0] "" X
 SG_ CP_a069_doorInductiveSensorError m1: 12|1@1+ (1,0) [0|0] "" X
 SG_ CP_a256_unused m1: 13|1@1+ (1,0) [0|0] "" X

BO_ 799 ID31FTPMSsensors: 8 ChassisBus
 SG_ TPMSFLpressure31F : 0|8@1+ (0.025,0) [0|6.375] "bar"  Receiver
 SG_ TPMSFRpressure31F : 16|8@1+ (0.025,0) [0|6.375] "bar"  Receiver
 SG_ TPMSRLpressure31F : 32|8@1+ (0.025,0) [0|6.375] "bar"  Receiver
 SG_ TPMSRRpressure31F : 48|8@1+ (0.025,0) [0|6.375] "bar"  Receiver
 SG_ TPMSFLtemp31F : 8|8@1+ (1,-40) [-40|215] "C"  Receiver
 SG_ TPMSFRtemp31F : 24|8@1+ (1,-40) [-40|215] "C"  Receiver
 SG_ TPMSRLtemp31F : 40|8@1+ (1,-40) [-40|215] "C"  Receiver
 SG_ TPMSRRtemp31F : 56|8@1+ (1,-40) [-40|215] "C"  Receiver

BO_ 800 BMS_alertMatrix: 8 VEH
 SG_ BMS_matrixIndex M: 0|4@1+ (1,0) [0|0] "" X
 SG_ BMS_a017_SW_Brick_OV m0: 20|1@1+ (1,0) [0|0] "" X
 SG_ BMS_a018_SW_Brick_UV m0: 21|1@1+ (1,0) [0|0] "" X
 SG_ BMS_a019_SW_Module_OT m0: 22|1@1+ (1,0) [0|0] "" X
 SG_ BMS_a021_SW_Dr_Limits_Regulation m0: 24|1@1+ (1,0) [0|0] "" X
 SG_ BMS_a022_SW_Over_Current m0: 25|1@1+ (1,0) [0|0] "" X
 SG_ BMS_a023_SW_Stack_OV m0: 26|1@1+ (1,0) [0|0] "" X
 SG_ BMS_a024_SW_Islanded_Brick m0: 27|1@1+ (1,0) [0|0] "" X
 SG_ BMS_a025_SW_PwrBalance_Anomaly m0: 28|1@1+ (1,0) [0|0] "" X
 SG_ BMS_a026_SW_HFCurrent_Anomaly m0: 29|1@1+ (1,0) [0|0] "" X
 SG_ BMS_a034_SW_Passive_Isolation m0: 37|1@1+ (1,0) [0|0] "" X
 SG_ BMS_a035_SW_Isolation m0: 38|1@1+ (1,0) [0|0] "" X
 SG_ BMS_a036_SW_HvpHvilFault m0: 39|1@1+ (1,0) [0|0] "" X
 SG_ BMS_a037_SW_Flood_Port_Open m0: 40|1@1+ (1,0) [0|0] "" X
 SG_ BMS_a039_SW_DC_Link_Over_Voltage m0: 42|1@1+ (1,0) [0|0] "" X
 SG_ BMS_a041_SW_Power_On_Reset m0: 44|1@1+ (1,0) [0|0] "" X
 SG_ BMS_a042_SW_MPU_Error m0: 45|1@1+ (1,0) [0|0] "" X
 SG_ BMS_a043_SW_Watch_Dog_Reset m0: 46|1@1+ (1,0) [0|0] "" X
 SG_ BMS_a044_SW_Assertion m0: 47|1@1+ (1,0) [0|0] "" X
 SG_ BMS_a045_SW_Exception m0: 48|1@1+ (1,0) [0|0] "" X
 SG_ BMS_a046_SW_Task_Stack_Usage m0: 49|1@1+ (1,0) [0|0] "" X
 SG_ BMS_a047_SW_Task_Stack_Overflow m0: 50|1@1+ (1,0) [0|0] "" X
 SG_ BMS_a048_SW_Log_Upload_Request m0: 51|1@1+ (1,0) [0|0] "" X
 SG_ BMS_a050_SW_Brick_Voltage_MIA m0: 53|1@1+ (1,0) [0|0] "" X
 SG_ BMS_a051_SW_HVC_Vref_Bad m0: 54|1@1+ (1,0) [0|0] "" X
 SG_ BMS_a052_SW_PCS_MIA m0: 55|1@1+ (1,0) [0|0] "" X
 SG_ BMS_a053_SW_ThermalModel_Sanity m0: 56|1@1+ (1,0) [0|0] "" X
 SG_ BMS_a054_SW_Ver_Supply_Fault m0: 57|1@1+ (1,0) [0|0] "" X
 SG_ BMS_a059_SW_Pack_Voltage_Sensing m0: 62|1@1+ (1,0) [0|0] "" X
 SG_ BMS_a060_SW_Leakage_Test_Failure m0: 63|1@1+ (1,0) [0|0] "" X
 SG_ BMS_a061_robinBrickOverVoltage m1: 4|1@1+ (1,0) [0|0] "" X
 SG_ BMS_a062_SW_BrickV_Imbalance m1: 5|1@1+ (1,0) [0|0] "" X
 SG_ BMS_a063_SW_ChargePort_Fault m1: 6|1@1+ (1,0) [0|0] "" X
 SG_ BMS_a064_SW_SOC_Imbalance m1: 7|1@1+ (1,0) [0|0] "" X
 SG_ BMS_a069_SW_Low_Power m1: 12|1@1+ (1,0) [0|0] "" X
 SG_ BMS_a071_SW_SM_TransCon_Not_Met m1: 14|1@1+ (1,0) [0|0] "" X
 SG_ BMS_a075_SW_Chg_Disable_Failure m1: 18|1@1+ (1,0) [0|0] "" X
 SG_ BMS_a076_SW_Dch_While_Charging m1: 19|1@1+ (1,0) [0|0] "" X
 SG_ BMS_a077_SW_Charger_Regulation m1: 20|1@1+ (1,0) [0|0] "" X
 SG_ BMS_a081_SW_Ctr_Close_Blocked m1: 24|1@1+ (1,0) [0|0] "" X
 SG_ BMS_a082_SW_Ctr_Force_Open m1: 25|1@1+ (1,0) [0|0] "" X
 SG_ BMS_a083_SW_Ctr_Close_Failure m1: 26|1@1+ (1,0) [0|0] "" X
 SG_ BMS_a084_SW_Sleep_Wake_Aborted m1: 27|1@1+ (1,0) [0|0] "" X
 SG_ BMS_a087_SW_Feim_Test_Blocked m1: 30|1@1+ (1,0) [0|0] "" X
 SG_ BMS_a088_SW_VcFront_MIA_InDrive m1: 31|1@1+ (1,0) [0|0] "" X
 SG_ BMS_a089_SW_VcFront_MIA m1: 32|1@1+ (1,0) [0|0] "" X
 SG_ BMS_a090_SW_Gateway_MIA m1: 33|1@1+ (1,0) [0|0] "" X
 SG_ BMS_a091_SW_ChargePort_MIA m1: 34|1@1+ (1,0) [0|0] "" X
 SG_ BMS_a092_SW_ChargePort_Mia_On_Hvs m1: 35|1@1+ (1,0) [0|0] "" X
 SG_ BMS_a094_SW_Drive_Inverter_MIA m1: 37|1@1+ (1,0) [0|0] "" X
 SG_ BMS_a099_SW_BMB_Communication m1: 42|1@1+ (1,0) [0|0] "" X
 SG_ BMS_a105_SW_One_Module_Tsense m1: 48|1@1+ (1,0) [0|0] "" X
 SG_ BMS_a106_SW_All_Module_Tsense m1: 49|1@1+ (1,0) [0|0] "" X
 SG_ BMS_a107_SW_Stack_Voltage_MIA m1: 50|1@1+ (1,0) [0|0] "" X
 SG_ BMS_a121_SW_NVRAM_Config_Error m2: 4|1@1+ (1,0) [0|0] "" X
 SG_ BMS_a122_SW_BMS_Therm_Irrational m2: 5|1@1+ (1,0) [0|0] "" X
 SG_ BMS_a123_SW_Internal_Isolation m2: 6|1@1+ (1,0) [0|0] "" X
 SG_ BMS_a127_SW_shunt_SNA m2: 10|1@1+ (1,0) [0|0] "" X
 SG_ BMS_a128_SW_shunt_MIA m2: 11|1@1+ (1,0) [0|0] "" X
 SG_ BMS_a129_SW_VSH_Failure m2: 12|1@1+ (1,0) [0|0] "" X
 SG_ BMS_a130_IO_CAN_Error m2: 13|1@1+ (1,0) [0|0] "" X
 SG_ BMS_a131_Bleed_FET_Failure m2: 14|1@1+ (1,0) [0|0] "" X
 SG_ BMS_a132_HW_BMB_OTP_Uncorrctbl m2: 15|1@1+ (1,0) [0|0] "" X
 SG_ BMS_a134_SW_Delayed_Ctr_Off m2: 17|1@1+ (1,0) [0|0] "" X
 SG_ BMS_a136_SW_Module_OT_Warning m2: 19|1@1+ (1,0) [0|0] "" X
 SG_ BMS_a137_SW_Brick_UV_Warning m2: 20|1@1+ (1,0) [0|0] "" X
 SG_ BMS_a138_SW_Brick_OV_Warning m2: 21|1@1+ (1,0) [0|0] "" X
 SG_ BMS_a139_SW_DC_Link_V_Irrational m2: 22|1@1+ (1,0) [0|0] "" X
 SG_ BMS_a141_SW_BMB_Status_Warning m2: 24|1@1+ (1,0) [0|0] "" X
 SG_ BMS_a144_Hvp_Config_Mismatch m2: 27|1@1+ (1,0) [0|0] "" X
 SG_ BMS_a145_SW_SOC_Change m2: 28|1@1+ (1,0) [0|0] "" X
 SG_ BMS_a146_SW_Brick_Overdischarged m2: 29|1@1+ (1,0) [0|0] "" X
 SG_ BMS_a149_SW_Missing_Config_Block m2: 32|1@1+ (1,0) [0|0] "" X
 SG_ BMS_a151_SW_external_isolation m2: 34|1@1+ (1,0) [0|0] "" X
 SG_ BMS_a156_SW_BMB_Vref_bad m2: 39|1@1+ (1,0) [0|0] "" X
 SG_ BMS_a157_SW_HVP_HVS_Comms m2: 40|1@1+ (1,0) [0|0] "" X
 SG_ BMS_a158_SW_HVP_HVI_Comms m2: 41|1@1+ (1,0) [0|0] "" X
 SG_ BMS_a159_SW_HVP_ECU_Error m2: 42|1@1+ (1,0) [0|0] "" X
 SG_ BMS_a161_SW_DI_Open_Request m2: 44|1@1+ (1,0) [0|0] "" X
 SG_ BMS_a162_SW_No_Power_For_Support m2: 45|1@1+ (1,0) [0|0] "" X
 SG_ BMS_a163_SW_Contactor_Mismatch m2: 46|1@1+ (1,0) [0|0] "" X
 SG_ BMS_a164_SW_Uncontrolled_Regen m2: 47|1@1+ (1,0) [0|0] "" X
 SG_ BMS_a165_SW_Pack_Partial_Weld m2: 48|1@1+ (1,0) [0|0] "" X
 SG_ BMS_a166_SW_Pack_Full_Weld m2: 49|1@1+ (1,0) [0|0] "" X
 SG_ BMS_a167_SW_FC_Partial_Weld m2: 50|1@1+ (1,0) [0|0] "" X
 SG_ BMS_a168_SW_FC_Full_Weld m2: 51|1@1+ (1,0) [0|0] "" X
 SG_ BMS_a169_SW_FC_Pack_Weld m2: 52|1@1+ (1,0) [0|0] "" X
 SG_ BMS_a170_SW_Limp_Mode m2: 53|1@1+ (1,0) [0|0] "" X
 SG_ BMS_a171_SW_Stack_Voltage_Sense m2: 54|1@1+ (1,0) [0|0] "" X
 SG_ BMS_a174_SW_Charge_Failure m2: 57|1@1+ (1,0) [0|0] "" X
 SG_ BMS_a176_SW_GracefulPowerOff m2: 59|1@1+ (1,0) [0|0] "" X
 SG_ BMS_a179_SW_Hvp_12V_Fault m2: 62|1@1+ (1,0) [0|0] "" X
 SG_ BMS_a180_SW_ECU_reset_blocked m2: 63|1@1+ (1,0) [0|0] "" X

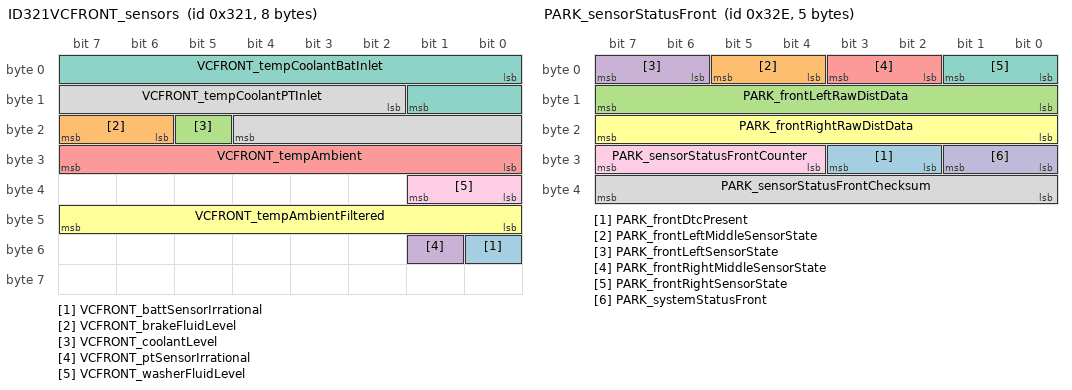
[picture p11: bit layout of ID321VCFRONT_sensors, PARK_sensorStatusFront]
BO_ 801 ID321VCFRONT_sensors: 8 VehicleBus
 SG_ VCFRONT_battSensorIrrational : 48|1@1+ (1,0) [0|1] ""  Receiver
 SG_ VCFRONT_brakeFluidLevel : 22|2@1+ (1,0) [0|2] ""  Receiver
 SG_ VCFRONT_coolantLevel : 21|1@1+ (1,0) [0|1] ""  Receiver
 SG_ VCFRONT_ptSensorIrrational : 49|1@1+ (1,0) [0|1] ""  Receiver
 SG_ VCFRONT_tempAmbient : 24|8@1+ (0.5,-40) [-40|80] "C"  Receiver
 SG_ VCFRONT_tempAmbientFiltered : 40|8@1+ (0.5,-40) [-40|80] "C"  Receiver
 SG_ VCFRONT_tempCoolantBatInlet : 0|10@1+ (0.125,-40) [-40|85] "C"  Receiver
 SG_ VCFRONT_tempCoolantPTInlet : 10|11@1+ (0.125,-40) [-40|200] "C"  Receiver
 SG_ VCFRONT_washerFluidLevel : 32|2@1+ (1,0) [0|2] ""  Receiver

BO_ 805 FC_alertMatrix1: 8 VEH
 SG_ FC_a001_scPostOutOfService: 0|1@1+ (1,0) [0|0] "" X
 SG_ FC_a002_scPowerShared: 1|1@1+ (1,0) [0|0] "" X

BO_ 806 PARK_info: 8 CH
 SG_ PARK_infoIndex M: 0|8@1+ (1,0) [0|0] "" X
 SG_ PARK_infoBuildType m10: 8|8@1+ (1,0) [0|0] "" X
 SG_ PARK_infoComponentID m10: 48|16@1+ (1,0) [0|0] "" X
 SG_ PARK_infoPcbaID m11: 16|8@1+ (1,0) [0|0] "" X
 SG_ PARK_infoAssemblyID m11: 24|8@1+ (1,0) [0|0] "" X
 SG_ PARK_infoUsageID m11: 32|16@1+ (1,0) [0|0] "" X
 SG_ PARK_infoBootUdsProtoVersion m20: 8|8@1+ (1,0) [0|0] "" X
 SG_ PARK_infoBootloaderCRC m20: 32|32@1+ (1,0) [0|0] "" X
 SG_ PARK_infoApplicationCRC m13: 32|32@1+ (1,0) [0|0] "" X

BO_ 808 ESP_info: 8 VEH
 SG_ ESP_infoIndex M: 0|8@1+ (1,0) [0|0] "" X
 SG_ ESP_infoBuildType m10: 8|8@1+ (1,0) [0|0] "" X
 SG_ ESP_infoComponentID m10: 48|16@1+ (1,0) [0|0] "" X
 SG_ ESP_infoPcbaID m11: 16|8@1+ (1,0) [0|0] "" X
 SG_ ESP_infoAssemblyID m11: 24|8@1+ (1,0) [0|0] "" X
 SG_ ESP_infoUsageID m11: 32|16@1+ (1,0) [0|0] "" X
 SG_ ESP_infoApplicationCRC m13: 32|32@0+ (1,0) [0|0] "" X
 SG_ ESP_infoVehicleVariant m16: 16|8@1+ (1,0) [0|0] "" X
 SG_ ESP_infoBootUdsProtoVersion m20: 8|8@1+ (1,0) [0|0] "" X
 SG_ ESP_infoBootloaderCRC m20: 32|32@1+ (1,0) [0|0] "" X
 SG_ ESP_infoVariantCRC m22: 32|32@0+ (1,0) [0|0] "" X

BO_ 809 APP_warningMatrix0: 8 CH
 SG_ APP_w001_DEPRECATED: 0|1@1+ (1,0) [0|0] "" X
 SG_ APP_w002_ldwDisabled: 1|1@1+ (1,0) [0|0] "" X
 SG_ APP_w003_isaDisabled: 2|1@1+ (1,0) [0|0] "" X
 SG_ APP_w004_accDisabled: 3|1@1+ (1,0) [0|0] "" X
 SG_ APP_w005_fcwCancelled: 4|1@1+ (1,0) [0|0] "" X
 SG_ APP_w006_aebCancelled: 5|1@1+ (1,0) [0|0] "" X
 SG_ APP_w007_ahlbDisabled: 6|1@1+ (1,0) [0|0] "" X
 SG_ APP_w008_parkDisabled: 7|1@1+ (1,0) [0|0] "" X
 SG_ APP_w009_aebFault: 8|1@1+ (1,0) [0|0] "" X
 SG_ APP_w010_radcCalibIssue: 9|1@1+ (1,0) [0|0] "" X
 SG_ APP_w011_scaEvent: 10|1@1+ (1,0) [0|0] "" X
 SG_ APP_w012_Cam_BootFailure: 11|1@1+ (1,0) [0|0] "" X
 SG_ APP_w013_Cam_Watchdog: 12|1@1+ (1,0) [0|0] "" X
 SG_ APP_w014_swAssert: 13|1@1+ (1,0) [0|0] "" X
 SG_ APP_w015_Camera_Failsafes: 14|1@1+ (1,0) [0|0] "" X
 SG_ APP_w016_aeb_e_event: 15|1@1+ (1,0) [0|0] "" X
 SG_ APP_w017_Cam_Msg_MIA: 16|1@1+ (1,0) [0|0] "" X
 SG_ APP_w018_ECU_Power_Issue: 17|1@1+ (1,0) [0|0] "" X
 SG_ APP_w019_ECU_Stack_Overflow: 18|1@1+ (1,0) [0|0] "" X
 SG_ APP_w020_ECU_checkstopError: 19|1@1+ (1,0) [0|0] "" X
 SG_ APP_w021_ECU_Temperature_Issue: 20|1@1+ (1,0) [0|0] "" X
 SG_ APP_w022_ECU_EEPROM_Failure: 21|1@1+ (1,0) [0|0] "" X
 SG_ APP_w023_ECU_Cam_Statemismatc: 22|1@1+ (1,0) [0|0] "" X
 SG_ APP_w024_ECU_Watchdog_Reset: 23|1@1+ (1,0) [0|0] "" X
 SG_ APP_w025_LC_Steering_Override: 24|1@1+ (1,0) [0|0] "" X
 SG_ APP_w026_ECU_timingIssue: 25|1@1+ (1,0) [0|0] "" X
 SG_ APP_w027_ECU_Reset_Fault: 26|1@1+ (1,0) [0|0] "" X
 SG_ APP_w028_spi_rx_error: 27|1@1+ (1,0) [0|0] "" X
 SG_ APP_w029_spi_tx_error: 28|1@1+ (1,0) [0|0] "" X
 SG_ APP_w030_Heater_Issue: 29|1@1+ (1,0) [0|0] "" X
 SG_ APP_w031_canRxError: 30|1@1+ (1,0) [0|0] "" X
 SG_ APP_w032_canTxError: 31|1@1+ (1,0) [0|0] "" X
 SG_ APP_w033_gtwMia: 32|1@1+ (1,0) [0|0] "" X
 SG_ APP_w034_sccmMia: 33|1@1+ (1,0) [0|0] "" X
 SG_ APP_w035_espMia: 34|1@1+ (1,0) [0|0] "" X
 SG_ APP_w036_bdyMia: 35|1@1+ (1,0) [0|0] "" X
 SG_ APP_w037_camTacIssue: 36|1@1+ (1,0) [0|0] "" X
 SG_ APP_w038_camFailure: 37|1@1+ (1,0) [0|0] "" X
 SG_ APP_w039_sdm_rcm_Mia: 38|1@1+ (1,0) [0|0] "" X
 SG_ APP_w040_autopilotAngleSaturated: 39|1@1+ (1,0) [0|0] "" X
 SG_ APP_w041_autopilotRateSaturated: 40|1@1+ (1,0) [0|0] "" X
 SG_ APP_w042_autopilotAborting: 41|1@1+ (1,0) [0|0] "" X
 SG_ APP_w043_camLongRunTime: 42|1@1+ (1,0) [0|0] "" X
 SG_ APP_w044_appMobileyeFailure: 43|1@1+ (1,0) [0|0] "" X
 SG_ APP_w045_radMia: 44|1@1+ (1,0) [0|0] "" X
 SG_ APP_w046_eepromRecordAbsent: 45|1@1+ (1,0) [0|0] "" X
 SG_ APP_w047_edrEvent: 46|1@1+ (1,0) [0|0] "" X
 SG_ APP_w048_APP_Features_Disabled: 47|1@1+ (1,0) [0|0] "" X
 SG_ APP_w049_eyeqVersionMismatch: 48|1@1+ (1,0) [0|0] "" X
 SG_ APP_w050_aeb_event: 49|1@1+ (1,0) [0|0] "" X
 SG_ APP_w051_radcEcuIssue: 50|1@1+ (1,0) [0|0] "" X
 SG_ APP_w052_radcSensorIssue: 51|1@1+ (1,0) [0|0] "" X
 SG_ APP_w053_radcCommIssue: 52|1@1+ (1,0) [0|0] "" X
 SG_ APP_w054_camAutofix: 53|1@1+ (1,0) [0|0] "" X
 SG_ APP_w055_radcVersionMismatch: 54|1@1+ (1,0) [0|0] "" X
 SG_ APP_w056_diMia: 55|1@1+ (1,0) [0|0] "" X
 SG_ APP_w057_mcuMia: 56|1@1+ (1,0) [0|0] "" X
 SG_ APP_w058_epbMia: 57|1@1+ (1,0) [0|0] "" X
 SG_ APP_w059_parkMia: 58|1@1+ (1,0) [0|0] "" X
 SG_ APP_w060_fcw_event: 59|1@1+ (1,0) [0|0] "" X
 SG_ APP_w061_airSuspensionMia: 60|1@1+ (1,0) [0|0] "" X
 SG_ APP_w062_radcAlignment: 61|1@1+ (1,0) [0|0] "" X
 SG_ APP_w063_parkVersionMismatch: 62|1@1+ (1,0) [0|0] "" X
 SG_ APP_w064_epasMia: 63|1@1+ (1,0) [0|0] "" X

BO_ 810 DAS_warningMatrix0: 8 VEH
 SG_ DAS_w002_ldwDisabled: 1|1@1+ (1,0) [0|0] "" X
 SG_ DAS_w003_isaDisabled: 2|1@1+ (1,0) [0|0] "" X
 SG_ DAS_w004_accDisabled: 3|1@1+ (1,0) [0|0] "" X
 SG_ DAS_w005_fcwCancelled: 4|1@1+ (1,0) [0|0] "" X
 SG_ DAS_w006_aebCancelled: 5|1@1+ (1,0) [0|0] "" X
 SG_ DAS_w007_ahlbDisabled: 6|1@1+ (1,0) [0|0] "" X
 SG_ DAS_w008_parkDisabled: 7|1@1+ (1,0) [0|0] "" X
 SG_ DAS_w009_aebFault: 8|1@1+ (1,0) [0|0] "" X
 SG_ DAS_w010_radcCalibIssue: 9|1@1+ (1,0) [0|0] "" X
 SG_ DAS_w011_scaEvent: 10|1@1+ (1,0) [0|0] "" X
 SG_ DAS_w012_Cam_BootFailure: 11|1@1+ (1,0) [0|0] "" X
 SG_ DAS_w013_Cam_Watchdog: 12|1@1+ (1,0) [0|0] "" X
 SG_ DAS_w014_swAssert: 13|1@1+ (1,0) [0|0] "" X
 SG_ DAS_w015_Camera_Failsafes: 14|1@1+ (1,0) [0|0] "" X
 SG_ DAS_w016_aeb_e_event: 15|1@1+ (1,0) [0|0] "" X
 SG_ DAS_w017_Cam_Msg_MIA: 16|1@1+ (1,0) [0|0] "" X
 SG_ DAS_w018_ECU_Power_Issue: 17|1@1+ (1,0) [0|0] "" X
 SG_ DAS_w019_ECU_Stack_Overflow: 18|1@1+ (1,0) [0|0] "" X
 SG_ DAS_w020_ECU_checkstopError: 19|1@1+ (1,0) [0|0] "" X
 SG_ DAS_w021_ECU_Temperature_Issue: 20|1@1+ (1,0) [0|0] "" X
 SG_ DAS_w022_ECU_EEPROM_Failure: 21|1@1+ (1,0) [0|0] "" X
 SG_ DAS_w023_ECU_Cam_Statemismatc: 22|1@1+ (1,0) [0|0] "" X
 SG_ DAS_w024_ECU_Watchdog_Reset: 23|1@1+ (1,0) [0|0] "" X
 SG_ DAS_w025_LC_Steering_Override: 24|1@1+ (1,0) [0|0] "" X
 SG_ DAS_w026_ECU_timingIssue: 25|1@1+ (1,0) [0|0] "" X
 SG_ DAS_w027_ECU_Reset_Fault: 26|1@1+ (1,0) [0|0] "" X
 SG_ DAS_w028_spi_rx_error: 27|1@1+ (1,0) [0|0] "" X
 SG_ DAS_w029_spi_tx_error: 28|1@1+ (1,0) [0|0] "" X
 SG_ DAS_w030_Heater_Issue: 29|1@1+ (1,0) [0|0] "" X
 SG_ DAS_w031_canRxError: 30|1@1+ (1,0) [0|0] "" X
 SG_ DAS_w032_canTxError: 31|1@1+ (1,0) [0|0] "" X
 SG_ DAS_w033_gtwMia: 32|1@1+ (1,0) [0|0] "" X
 SG_ DAS_w034_sccmMia: 33|1@1+ (1,0) [0|0] "" X
 SG_ DAS_w035_espMia: 34|1@1+ (1,0) [0|0] "" X
 SG_ DAS_w036_bdyMia: 35|1@1+ (1,0) [0|0] "" X
 SG_ DAS_w037_camTacIssue: 36|1@1+ (1,0) [0|0] "" X
 SG_ DAS_w038_camFailure: 37|1@1+ (1,0) [0|0] "" X
 SG_ DAS_w039_sdm_rcm_Mia: 38|1@1+ (1,0) [0|0] "" X
 SG_ DAS_w040_autopilotAngleSaturated: 39|1@1+ (1,0) [0|0] "" X
 SG_ DAS_w041_autopilotRateSaturated: 40|1@1+ (1,0) [0|0] "" X
 SG_ DAS_w042_autopilotAborting: 41|1@1+ (1,0) [0|0] "" X
 SG_ DAS_w043_camLongRunTime: 42|1@1+ (1,0) [0|0] "" X
 SG_ DAS_w044_appMobileyeFailure: 43|1@1+ (1,0) [0|0] "" X
 SG_ DAS_w045_radMia: 44|1@1+ (1,0) [0|0] "" X
 SG_ DAS_w046_eepromRecordAbsent: 45|1@1+ (1,0) [0|0] "" X
 SG_ DAS_w047_edrEvent: 46|1@1+ (1,0) [0|0] "" X
 SG_ DAS_w048_DAS_Features_Disabled: 47|1@1+ (1,0) [0|0] "" X
 SG_ DAS_w049_eyeqVersionMismatch: 48|1@1+ (1,0) [0|0] "" X
 SG_ DAS_w050_aeb_event: 49|1@1+ (1,0) [0|0] "" X
 SG_ DAS_w051_radcEcuIssue: 50|1@1+ (1,0) [0|0] "" X
 SG_ DAS_w052_radcSensorIssue: 51|1@1+ (1,0) [0|0] "" X
 SG_ DAS_w053_radcCommIssue: 52|1@1+ (1,0) [0|0] "" X
 SG_ DAS_w054_camAutofix: 53|1@1+ (1,0) [0|0] "" X
 SG_ DAS_w055_radcVersionMismatch: 54|1@1+ (1,0) [0|0] "" X
 SG_ DAS_w056_diMia: 55|1@1+ (1,0) [0|0] "" X
 SG_ DAS_w057_mcuMia: 56|1@1+ (1,0) [0|0] "" X
 SG_ DAS_w058_epbMia: 57|1@1+ (1,0) [0|0] "" X
 SG_ DAS_w059_parkMia: 58|1@1+ (1,0) [0|0] "" X
 SG_ DAS_w060_fcw_event: 59|1@1+ (1,0) [0|0] "" X
 SG_ DAS_w061_airSuspensionMia: 60|1@1+ (1,0) [0|0] "" X
 SG_ DAS_w062_radcAlignment: 61|1@1+ (1,0) [0|0] "" X
 SG_ DAS_w063_parkVersionMismatch: 62|1@1+ (1,0) [0|0] "" X
 SG_ DAS_w064_epasMia: 63|1@1+ (1,0) [0|0] "" X

BO_ 811 APS_warningMatrix0: 8 CH
 SG_ APS_w001_DEPRECATED: 0|1@1+ (1,0) [0|0] "" X
 SG_ APS_w002_ldwDisabled: 1|1@1+ (1,0) [0|0] "" X
 SG_ APS_w003_isaDisabled: 2|1@1+ (1,0) [0|0] "" X
 SG_ APS_w004_accDisabled: 3|1@1+ (1,0) [0|0] "" X
 SG_ APS_w005_fcwCancelled: 4|1@1+ (1,0) [0|0] "" X
 SG_ APS_w006_aebCancelled: 5|1@1+ (1,0) [0|0] "" X
 SG_ APS_w007_ahlbDisabled: 6|1@1+ (1,0) [0|0] "" X
 SG_ APS_w008_parkDisabled: 7|1@1+ (1,0) [0|0] "" X
 SG_ APS_w009_aebFault: 8|1@1+ (1,0) [0|0] "" X
 SG_ APS_w010_radcCalibIssue: 9|1@1+ (1,0) [0|0] "" X
 SG_ APS_w011_scaEvent: 10|1@1+ (1,0) [0|0] "" X
 SG_ APS_w012_Cam_BootFailure: 11|1@1+ (1,0) [0|0] "" X
 SG_ APS_w013_Cam_Watchdog: 12|1@1+ (1,0) [0|0] "" X
 SG_ APS_w014_swAssert: 13|1@1+ (1,0) [0|0] "" X
 SG_ APS_w015_Camera_Failsafes: 14|1@1+ (1,0) [0|0] "" X
 SG_ APS_w016_aeb_e_event: 15|1@1+ (1,0) [0|0] "" X
 SG_ APS_w017_Cam_Msg_MIA: 16|1@1+ (1,0) [0|0] "" X
 SG_ APS_w018_ECU_Power_Issue: 17|1@1+ (1,0) [0|0] "" X
 SG_ APS_w019_ECU_Stack_Overflow: 18|1@1+ (1,0) [0|0] "" X
 SG_ APS_w020_ECU_checkstopError: 19|1@1+ (1,0) [0|0] "" X
 SG_ APS_w021_ECU_Temperature_Issue: 20|1@1+ (1,0) [0|0] "" X
 SG_ APS_w022_ECU_EEPROM_Failure: 21|1@1+ (1,0) [0|0] "" X
 SG_ APS_w023_ECU_Cam_Statemismatc: 22|1@1+ (1,0) [0|0] "" X
 SG_ APS_w024_ECU_Watchdog_Reset: 23|1@1+ (1,0) [0|0] "" X
 SG_ APS_w025_LC_Steering_Override: 24|1@1+ (1,0) [0|0] "" X
 SG_ APS_w026_ECU_timingIssue: 25|1@1+ (1,0) [0|0] "" X
 SG_ APS_w027_ECU_Reset_Fault: 26|1@1+ (1,0) [0|0] "" X
 SG_ APS_w028_spi_rx_error: 27|1@1+ (1,0) [0|0] "" X
 SG_ APS_w029_spi_tx_error: 28|1@1+ (1,0) [0|0] "" X
 SG_ APS_w030_Heater_Issue: 29|1@1+ (1,0) [0|0] "" X
 SG_ APS_w031_canRxError: 30|1@1+ (1,0) [0|0] "" X
 SG_ APS_w032_canTxError: 31|1@1+ (1,0) [0|0] "" X
 SG_ APS_w033_gtwMia: 32|1@1+ (1,0) [0|0] "" X
 SG_ APS_w034_sccmMia: 33|1@1+ (1,0) [0|0] "" X
 SG_ APS_w035_espMia: 34|1@1+ (1,0) [0|0] "" X
 SG_ APS_w036_bdyMia: 35|1@1+ (1,0) [0|0] "" X
 SG_ APS_w037_camTacIssue: 36|1@1+ (1,0) [0|0] "" X
 SG_ APS_w038_camFailure: 37|1@1+ (1,0) [0|0] "" X
 SG_ APS_w039_sdm_rcm_Mia: 38|1@1+ (1,0) [0|0] "" X
 SG_ APS_w040_autopilotAngleSaturated: 39|1@1+ (1,0) [0|0] "" X
 SG_ APS_w041_autopilotRateSaturated: 40|1@1+ (1,0) [0|0] "" X
 SG_ APS_w042_autopilotAborting: 41|1@1+ (1,0) [0|0] "" X
 SG_ APS_w043_camLongRunTime: 42|1@1+ (1,0) [0|0] "" X
 SG_ APS_w044_appMobileyeFailure: 43|1@1+ (1,0) [0|0] "" X
 SG_ APS_w045_radMia: 44|1@1+ (1,0) [0|0] "" X
 SG_ APS_w046_eepromRecordAbsent: 45|1@1+ (1,0) [0|0] "" X
 SG_ APS_w047_edrEvent: 46|1@1+ (1,0) [0|0] "" X
 SG_ APS_w048_DAS_Features_Disabled: 47|1@1+ (1,0) [0|0] "" X
 SG_ APS_w049_eyeqVersionMismatch: 48|1@1+ (1,0) [0|0] "" X
 SG_ APS_w050_aeb_event: 49|1@1+ (1,0) [0|0] "" X
 SG_ APS_w051_radcEcuIssue: 50|1@1+ (1,0) [0|0] "" X
 SG_ APS_w052_radcSensorIssue: 51|1@1+ (1,0) [0|0] "" X
 SG_ APS_w053_radcCommIssue: 52|1@1+ (1,0) [0|0] "" X
 SG_ APS_w054_camAutofix: 53|1@1+ (1,0) [0|0] "" X
 SG_ APS_w055_radcVersionMismatch: 54|1@1+ (1,0) [0|0] "" X
 SG_ APS_w056_diMia: 55|1@1+ (1,0) [0|0] "" X
 SG_ APS_w057_mcuMia: 56|1@1+ (1,0) [0|0] "" X
 SG_ APS_w058_epbMia: 57|1@1+ (1,0) [0|0] "" X
 SG_ APS_w059_parkMia: 58|1@1+ (1,0) [0|0] "" X
 SG_ APS_w060_fcw_event: 59|1@1+ (1,0) [0|0] "" X
 SG_ APS_w061_tasMia: 60|1@1+ (1,0) [0|0] "" X
 SG_ APS_w062_radcAlignment: 61|1@1+ (1,0) [0|0] "" X
 SG_ APS_w063_parkVersionMismatch: 62|1@1+ (1,0) [0|0] "" X
 SG_ APS_w064_epasMia: 63|1@1+ (1,0) [0|0] "" X

BO_ 812 CC_logData: 8 VEH
 SG_ CC_logIndex M: 0|8@1+ (1,0) [0|0] "" X
 SG_ CC_activeConnectorID m0: 8|8@1+ (1,0) [0|0] "" X
 SG_ CC_temperature1 m0: 16|8@1- (1,88) [0|0] "DegC" X
 SG_ CC_temperature2 m0: 24|8@1- (1,88) [0|0] "DegC" X
 SG_ CC_temperature3 m0: 32|8@1- (1,88) [0|0] "DegC" X
 SG_ CC_contactor1Closed m0: 40|2@1+ (1,0) [0|0] "" X
 SG_ CC_contactor2Closed m0: 42|2@1+ (1,0) [0|0] "" X
 SG_ CC_temperature4 m0: 44|8@1- (1,88) [0|0] "DegC" X
 SG_ CC_conn1Current m1: 8|8@1+ (0.5,0) [0|0] "A" X
 SG_ CC_conn2Current m2: 8|8@1+ (0.5,0) [0|0] "A" X
 SG_ CC_conn3Current m3: 8|8@1+ (0.5,0) [0|0] "A" X
 SG_ CC_conn4Current m4: 8|8@1+ (0.5,0) [0|0] "A" X
 SG_ CC_lifetimei2t m10: 32|32@1+ (0.1,0) [0|0] "A2h" X
 SG_ CC_lifetimeCtrCycles m11: 8|28@1+ (1,0) [0|0] "" X
 SG_ CC_lifetimeCtrCyclesLoaded m11: 36|28@1+ (1,0) [0|0] "" X
 SG_ CC_lifetimeAlertCount m12: 8|28@1+ (1,0) [0|0] "" X
 SG_ CC_lifetimVEHermalFoldbacks m12: 36|28@1+ (1,0) [0|0] "" X
 SG_ CC_lifetimeAvgStartupTemp m13: 36|28@1- (0.1,0) [0|0] "degC" X

BO_ 813 IBST_info: 8 CH
 SG_ IBST_infoIndex M: 0|8@1+ (1,0) [0|0] "" X
 SG_ IBST_infoBuildType m10: 8|8@1+ (1,0) [0|0] "" X
 SG_ IBST_infoComponentID m10: 48|16@1+ (1,0) [0|0] "" X
 SG_ IBST_infoPcbaID m11: 16|8@1+ (1,0) [0|0] "" X
 SG_ IBST_infoAssemblyID m11: 24|8@1+ (1,0) [0|0] "" X
 SG_ IBST_infoUsageID m11: 32|16@1+ (1,0) [0|0] "" X
 SG_ IBST_infoBootUdsProtoVersion m20: 8|8@1+ (1,0) [0|0] "" X
 SG_ IBST_infoBootloaderCRC m20: 32|32@1+ (1,0) [0|0] "" X
 SG_ IBST_infoApplicationCRC m13: 32|32@1+ (1,0) [0|0] "" X
 SG_ IBST_infoVariantCRC m22: 32|32@1+ (1,0) [0|0] "" X

BO_ 814 PARK_sensorStatusFront: 5 CH
 SG_ PARK_frontDtcPresent: 26|2@1+ (1,0) [0|0] "" X
 SG_ PARK_frontLeftMiddleSensorState: 4|2@1+ (1,0) [0|0] "" X
 SG_ PARK_frontLeftRawDistData: 8|8@1+ (1,0) [0|0] "cm" X
 SG_ PARK_frontLeftSensorState: 6|2@1+ (1,0) [0|0] "" X
 SG_ PARK_frontRightMiddleSensorState: 2|2@1+ (1,0) [0|0] "" X
 SG_ PARK_frontRightRawDistData: 16|8@1+ (1,0) [0|0] "cm" X
 SG_ PARK_frontRightSensorState: 0|2@1+ (1,0) [0|0] "" X
 SG_ PARK_sensorStatusFrontChecksum: 32|8@1+ (1,0) [0|0] "" X
 SG_ PARK_sensorStatusFrontCounter: 28|4@1+ (1,0) [0|0] "" X
 SG_ PARK_systemStatusFront: 24|2@1+ (1,0) [0|0] "" X

BO_ 815 SCM_alertMatrix1: 8 CH
 SG_ SCM_a001_hwDSPfault: 0|1@1+ (1,0) [0|0] "" X
 SG_ SCM_a002_hwIbatOC: 1|1@1+ (1,0) [0|0] "" X
 SG_ SCM_a003_hwCordOT: 2|1@1+ (1,0) [0|0] "" X
 SG_ SCM_a004_hwVbusOV: 3|1@1+ (1,0) [0|0] "" X
 SG_ SCM_a005_hwHVIL: 4|1@1+ (1,0) [0|0] "" X
 SG_ SCM_a006_hwWeld_V1: 5|1@1+ (1,0) [0|0] "" X
 SG_ SCM_a007_hwWeld_V2: 6|1@1+ (1,0) [0|0] "" X
 SG_ SCM_a008_hwOpen_V1: 7|1@1+ (1,0) [0|0] "" X
 SG_ SCM_a009_hwOpen_V2: 8|1@1+ (1,0) [0|0] "" X
 SG_ SCM_a010_hwIllegalCntrCmdV1: 9|1@1+ (1,0) [0|0] "" X
 SG_ SCM_a011_hwIllegalCntrCmdInt: 10|1@1+ (1,0) [0|0] "" X
 SG_ SCM_a012_hwIllegalCntrCmdV2: 11|1@1+ (1,0) [0|0] "" X
 SG_ SCM_a013_cordTempHiFoldBk: 12|1@1+ (1,0) [0|0] "" X
 SG_ SCM_a014_coolantTempHiFoldBk: 13|1@1+ (1,0) [0|0] "" X
 SG_ SCM_a015_unusedHW15: 14|1@1+ (1,0) [0|0] "" X
 SG_ SCM_a016_unusedHW16: 15|1@1+ (1,0) [0|0] "" X
 SG_ SCM_a017_unusedHW17: 16|1@1+ (1,0) [0|0] "" X
 SG_ SCM_a018_unusedHW18: 17|1@1+ (1,0) [0|0] "" X
 SG_ SCM_a019_unusedHW19: 18|1@1+ (1,0) [0|0] "" X
 SG_ SCM_a020_unusedHW20: 19|1@1+ (1,0) [0|0] "" X
 SG_ SCM_a021_unusedHW21: 20|1@1+ (1,0) [0|0] "" X
 SG_ SCM_a022_fastChargeLimitActiveV1: 21|1@1+ (1,0) [0|0] "" X
 SG_ SCM_a023_fastChargeLimitActiveV2: 22|1@1+ (1,0) [0|0] "" X
 SG_ SCM_a024_emergencyShutdown: 23|1@1+ (1,0) [0|0] "" X
 SG_ SCM_a025_internalIsolationFault: 24|1@1+ (1,0) [0|0] "" X
 SG_ SCM_a026_internalIsolationLow: 25|1@1+ (1,0) [0|0] "" X
 SG_ SCM_a027_externalIsolationLow: 26|1@1+ (1,0) [0|0] "" X
 SG_ SCM_a028_isolationRationality: 27|1@1+ (1,0) [0|0] "" X
 SG_ SCM_a029_VbatOV: 28|1@1+ (1,0) [0|0] "" X
 SG_ SCM_a030_VbusOV: 29|1@1+ (1,0) [0|0] "" X
 SG_ SCM_a031_IbatOC: 30|1@1+ (1,0) [0|0] "" X
 SG_ SCM_a032_VBatRationality: 31|1@1+ (1,0) [0|0] "" X
 SG_ SCM_a033_VBusRationality: 32|1@1+ (1,0) [0|0] "" X
 SG_ SCM_a034_IBatRationality: 33|1@1+ (1,0) [0|0] "" X
 SG_ SCM_a035_unexpectedVbusBehavior: 34|1@1+ (1,0) [0|0] "" X
 SG_ SCM_a036_internalContactorWelded: 35|1@1+ (1,0) [0|0] "" X
 SG_ SCM_a037_outputContactorWelded: 36|1@1+ (1,0) [0|0] "" X
 SG_ SCM_a038_contactorFailedOpen: 37|1@1+ (1,0) [0|0] "" X
 SG_ SCM_a039_ibatRegulation: 38|1@1+ (1,0) [0|0] "" X
 SG_ SCM_a040_plus12VOutOfRange: 39|1@1+ (1,0) [0|0] "" X
 SG_ SCM_a041_minus12VOutOfRange: 40|1@1+ (1,0) [0|0] "" X
 SG_ SCM_a042_pilotOutOfRange: 41|1@1+ (1,0) [0|0] "" X
 SG_ SCM_a043_pilotRationality: 42|1@1+ (1,0) [0|0] "" X
 SG_ SCM_a044_proximityRationality: 43|1@1+ (1,0) [0|0] "" X
 SG_ SCM_a045_pcbaOT: 44|1@1+ (1,0) [0|0] "" X
 SG_ SCM_a046_coolantOT: 45|1@1+ (1,0) [0|0] "" X
 SG_ SCM_a047_cordOT: 46|1@1+ (1,0) [0|0] "" X
 SG_ SCM_a048_ambientOT: 47|1@1+ (1,0) [0|0] "" X
 SG_ SCM_a049_pcbaTempRationality: 48|1@1+ (1,0) [0|0] "" X
 SG_ SCM_a050_coolantTempRationality: 49|1@1+ (1,0) [0|0] "" X
 SG_ SCM_a051_cordTempRationality: 50|1@1+ (1,0) [0|0] "" X
 SG_ SCM_a052_ambientTempRationality: 51|1@1+ (1,0) [0|0] "" X
 SG_ SCM_a053_unexpectedThermalBehavi: 52|1@1+ (1,0) [0|0] "" X
 SG_ SCM_a054_pumpRegulation: 53|1@1+ (1,0) [0|0] "" X
 SG_ SCM_a055_coolantLevelLow: 54|1@1+ (1,0) [0|0] "" X
 SG_ SCM_a056_stateTransitionDenied: 55|1@1+ (1,0) [0|0] "" X
 SG_ SCM_a057_watchdogReset: 56|1@1+ (1,0) [0|0] "" X
 SG_ SCM_a058_adcRef: 57|1@1+ (1,0) [0|0] "" X
 SG_ SCM_a059_memoryError: 58|1@1+ (1,0) [0|0] "" X
 SG_ SCM_a060_swHVIL: 59|1@1+ (1,0) [0|0] "" X
 SG_ SCM_a061_postOutOfService: 60|1@1+ (1,0) [0|0] "" X
 SG_ SCM_a062_unused: 61|1@1+ (1,0) [0|0] "" X
 SG_ SCM_a063_canRationality: 62|1@1+ (1,0) [0|0] "" X
 SG_ SCM_a064_vehicleCommandTimeout: 63|1@1+ (1,0) [0|0] "" X

BO_ 816 SCCM_info: 8 VEH
 SG_ SCCM_infoIndex M: 0|8@1+ (1,0) [0|0] "" X
 SG_ SCCM_infoBuildType m10: 8|8@1+ (1,0) [0|0] "" X
 SG_ SCCM_infoBuildConfigId m10: 16|16@1+ (1,0) [0|0] "" X
 SG_ SCCM_infoHardwareId m10: 32|16@1+ (1,0) [0|0] "" X
 SG_ SCCM_infoComponentId m10: 48|16@1+ (1,0) [0|0] "" X
 SG_ SCCM_infoPcbaId m11: 16|8@1+ (1,0) [0|0] "" X
 SG_ SCCM_infoAssemblyId m11: 24|8@1+ (1,0) [0|0] "" X
 SG_ SCCM_infoUsageId m11: 32|16@1+ (1,0) [0|0] "" X
 SG_ SCCM_infoSubUsageId m11: 48|16@1+ (1,0) [0|0] "" X
 SG_ SCCM_infoPlatformType m13: 8|8@1+ (1,0) [0|0] "" X
 SG_ SCCM_infoAppCrc m13: 32|32@0+ (1,0) [0|0] "" X
 SG_ SCCM_infoBootSvnRev m14: 8|24@1+ (1,0) [0|0] "" X
 SG_ SCCM_infoBootSvnUrlHash m14: 32|32@1+ (1,0) [0|0] "" X
 SG_ SCCM_infoSubcomponent1Version m16: 16|32@1+ (1,0) [0|0] "" X
 SG_ SCCM_infoAppSvnHash m17: 10|54@1+ (4,0) [0|0] "" X
 SG_ SCCM_infoBootSvnHash m18: 10|54@1+ (4,0) [0|0] "" X
 SG_ SCCM_infoUdsProtoVersion m20: 8|8@1+ (1,0) [0|0] "" X
 SG_ SCCM_infoBootCrc m20: 32|32@1+ (1,0) [0|0] "" X

BO_ 817 EPAS3P_info: 8 VEH
 SG_ EPAS3P_infoIndex M: 0|8@1+ (1,0) [0|0] "" X
 SG_ EPAS3P_infoBuildType m10: 8|8@1+ (1,0) [0|0] "" X
 SG_ EPAS3P_infoComponentID m10: 48|16@1+ (1,0) [0|0] "" X
 SG_ EPAS3P_infoPcbaID m11: 16|8@1+ (1,0) [0|0] "" X
 SG_ EPAS3P_infoAssemblyID m11: 24|8@1+ (1,0) [0|0] "" X
 SG_ EPAS3P_infoUsageID m11: 32|16@1+ (1,0) [0|0] "" X
 SG_ EPAS3P_infoBootUdsProtoVersion m20: 8|8@1+ (1,0) [0|0] "" X
 SG_ EPAS3P_infoBootloaderCRC m20: 32|32@1+ (1,0) [0|0] "" X
 SG_ EPAS3P_infoApplicationCRC m13: 32|32@1+ (1,0) [0|0] "" X

BO_ 818 ID332BattBrickMinMax: 6 VehicleBus
 SG_ BattBrickMultiplexer332 M : 0|2@1+ (1,0) [0|0] ""  Receiver
 SG_ BattBrickempMaxNum332 m0 : 2|4@1+ (1,0) [0|0] ""  Receiver
 SG_ BattBrickTempMinNum332 m0 : 8|4@1+ (1,0) [0|0] ""  Receiver
 SG_ BattBrickTempMax332 m0 : 16|8@1+ (0.5,-40) [0|0] "C"  Receiver
 SG_ BattBrickTempMin332 m0 : 24|8@1+ (0.5,-40) [0|0] "C"  Receiver
 SG_ BattBrickModelTMax332 m0 : 32|8@1+ (0.5,-40) [0|0] "C"  Receiver
 SG_ BattBrickModelTMin332 m0 : 40|8@1+ (0.5,-40) [0|0] "C"  Receiver
 SG_ BattBrickVoltageMax332 m1 : 2|12@1+ (0.002,0) [0|0] "V"  Receiver
 SG_ BattBrickVoltageMin332 m1 : 16|12@1+ (0.002,0) [0|0] "V"  Receiver
 SG_ BattBrickVoltageMaxNum332 m1 : 32|7@1+ (1,1) [0|0] ""  Receiver
 SG_ BattBrickVoltageMinNum332 m1 : 40|7@1+ (1,1) [0|0] ""  Receiver

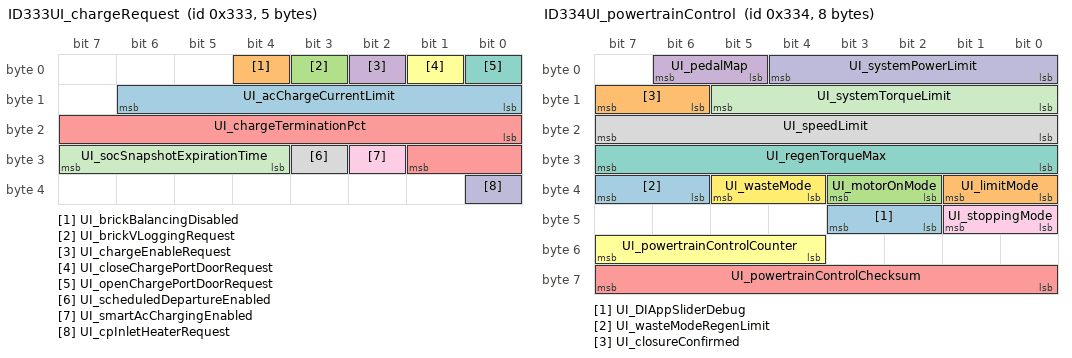
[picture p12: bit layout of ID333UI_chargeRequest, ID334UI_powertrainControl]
BO_ 819 ID333UI_chargeRequest: 5 VehicleBus
 SG_ UI_acChargeCurrentLimit : 8|7@1+ (1,0) [0|127] "A"  Receiver
 SG_ UI_brickBalancingDisabled : 4|1@1+ (1,0) [0|1] ""  Receiver
 SG_ UI_brickVLoggingRequest : 3|1@1+ (1,0) [0|1] ""  Receiver
 SG_ UI_chargeEnableRequest : 2|1@1+ (1,0) [0|1] ""  Receiver
 SG_ UI_chargeTerminationPct : 16|10@1+ (0.1,0) [25|100] "%"  Receiver
 SG_ UI_closeChargePortDoorRequest : 1|1@1+ (1,0) [0|1] ""  Receiver
 SG_ UI_openChargePortDoorRequest : 0|1@1+ (1,0) [0|1] ""  Receiver
 SG_ UI_scheduledDepartureEnabled : 27|1@1+ (1,0) [0|1] ""  Receiver
 SG_ UI_smartAcChargingEnabled : 26|1@1+ (1,0) [0|1] ""  Receiver
 SG_ UI_cpInletHeaterRequest : 32|1@1+ (1,0) [0|0] ""  Receiver
 SG_ UI_socSnapshotExpirationTime : 28|4@1+ (1,2) [0|0] "weeks"  Receiver

BO_ 820 ID334UI_powertrainControl: 8 VehicleBus
 SG_ UI_DIAppSliderDebug : 42|2@1+ (1,0) [0|3] ""  Receiver
 SG_ UI_limitMode : 32|2@1+ (1,0) [0|3] ""  Receiver
 SG_ UI_motorOnMode : 34|2@1+ (1,0) [0|2] ""  Receiver
 SG_ UI_pedalMap : 5|2@1+ (1,0) [0|2] ""  Receiver
 SG_ UI_powertrainControlChecksum : 56|8@1+ (1,0) [0|255] ""  Receiver
 SG_ UI_powertrainControlCounter : 52|4@1+ (1,0) [0|15] ""  Receiver
 SG_ UI_regenTorqueMax : 24|8@1+ (0.5,0) [0|100] "%"  Receiver
 SG_ UI_speedLimit : 16|8@1+ (1,50) [50|285] "kph"  Receiver
 SG_ UI_stoppingMode : 40|2@1+ (1,0) [0|2] ""  Receiver
 SG_ UI_systemPowerLimit : 0|5@1+ (20,20) [20|640] "kW"  Receiver
 SG_ UI_systemTorqueLimit : 8|6@1+ (100,4000) [4000|10300] "Nm"  Receiver
 SG_ UI_wasteMode : 36|2@1+ (1,0) [0|2] ""  Receiver
 SG_ UI_wasteModeRegenLimit : 38|2@1+ (1,0) [0|3] ""  Receiver
 SG_ UI_closureConfirmed : 14|2@1+ (1,0) [0|2] ""  Receiver

BO_ 821 ID335RearDIinfo: 8 VehicleBus
 SG_ DIR_infoIndex M : 0|8@1+ (1,0) [0|255] ""  Receiver
 SG_ DIR_FPGA_version m16 : 48|8@1+ (1,0) [0|255] ""  Receiver
 SG_ DIR_appGitHash m17 : 8|56@1+ (1,0) [0|7.20576E+016] ""  Receiver
 SG_ DIR_applicationCrc m13 : 32|32@1+ (1,0) [0|4294970000] ""  Receiver
 SG_ DIR_assemblyId m11 : 24|8@1+ (1,0) [0|255] ""  Receiver
 SG_ DIR_bootGitHash m18 : 8|56@1+ (1,0) [0|7.20576E+016] ""  Receiver
 SG_ DIR_bootloaderCrc m20 : 32|32@1+ (1,0) [0|4294970000] ""  Receiver
 SG_ DIR_buildConfigurationId m10 : 16|16@1+ (1,0) [0|65535] ""  Receiver
 SG_ DIR_buildType m10 : 8|3@1+ (1,0) [0|4] ""  Receiver
 SG_ DIR_componentId m10 : 48|16@1+ (1,0) [0|65535] ""  Receiver
 SG_ DIR_hardwareId m10 : 32|8@1+ (1,0) [0|252] ""  Receiver
 SG_ DIR_infoBootLdUdsProtocolVersion m20 : 8|8@1+ (1,0) [0|255] ""  Receiver
 SG_ DIR_oilPumpAppCrc m16 : 16|32@1+ (1,0) [0|4294970000] ""  Receiver
 SG_ DIR_oilPumpBuildType m16 : 8|3@1+ (1,0) [0|4] ""  Receiver
 SG_ DIR_pcbaId m11 : 16|8@1+ (1,0) [0|255] ""  Receiver
 SG_ DIR_platformTyp m19 : 8|8@1+ (1,0) [0|255] ""  Receiver
 SG_ DIR_subUsageId m11 : 48|16@1+ (1,0) [0|65535] ""  Receiver
 SG_ DIR_subcomponentGitHash m31 : 8|56@1+ (1,0) [0|7.20576E+016] ""  Receiver
 SG_ DIR_usageId m11 : 32|16@1+ (1,0) [0|65535] ""  Receiver

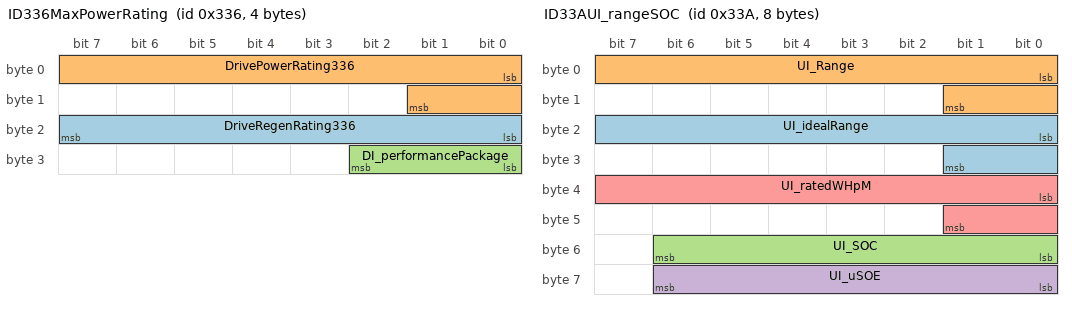
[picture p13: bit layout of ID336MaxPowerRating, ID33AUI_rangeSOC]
BO_ 822 ID336MaxPowerRating: 4 VehicleBus
 SG_ DriveRegenRating336 : 16|8@1+ (1,-100) [-100|155] "kW"  Receiver
 SG_ DrivePowerRating336 : 0|10@1+ (1,0) [0|600] "kW"  Receiver
 SG_ DI_performancePackage : 24|3@1+ (1,0) [0|4] ""  Receiver

BO_ 824 UMC_alertMatrix1: 8 VEH
 SG_ UMC_a001_gndMonIntrptLineSide: 0|1@1+ (1,0) [0|0] "" X
 SG_ UMC_a002_GFCITripped: 1|1@1+ (1,0) [0|0] "" X
 SG_ UMC_a003_GFCISelfTestFault: 2|1@1+ (1,0) [0|0] "" X
 SG_ UMC_a004_inputOverVoltage: 3|1@1+ (1,0) [0|0] "" X
 SG_ UMC_a005_inputUnderVoltage: 4|1@1+ (1,0) [0|0] "" X
 SG_ UMC_a006_contactorWelded: 5|1@1+ (1,0) [0|0] "" X
 SG_ UMC_a007_pcbaOT: 6|1@1+ (1,0) [0|0] "" X
 SG_ UMC_a008_wallPlugOT: 7|1@1+ (1,0) [0|0] "" X
 SG_ UMC_a009_vehConnOT: 8|1@1+ (1,0) [0|0] "" X
 SG_ UMC_a010_inputOT: 9|1@1+ (1,0) [0|0] "" X
 SG_ UMC_a011_proxDisconnected: 10|1@1+ (1,0) [0|0] "" X
 SG_ UMC_a012_pilotFault: 11|1@1+ (1,0) [0|0] "" X
 SG_ UMC_a013_SA_Temperature: 12|1@1+ (1,0) [0|0] "" X
 SG_ UMC_a014_SA_Genealogy: 13|1@1+ (1,0) [0|0] "" X
 SG_ UMC_a015_SA_Connection: 14|1@1+ (1,0) [0|0] "" X
 SG_ UMC_a016_pcbaOTFoldback: 15|1@1+ (1,0) [0|0] "" X
 SG_ UMC_a017_wallPlugOTFoldback: 16|1@1+ (1,0) [0|0] "" X
 SG_ UMC_a018_vehConnOTFoldback: 17|1@1+ (1,0) [0|0] "" X
 SG_ UMC_a019_inputOTFoldback: 18|1@1+ (1,0) [0|0] "" X
 SG_ UMC_a020_applicationCRC: 19|1@1+ (1,0) [0|0] "" X
 SG_ UMC_a021_dataBus: 20|1@1+ (1,0) [0|0] "" X
 SG_ UMC_a022_criticalRAM: 21|1@1+ (1,0) [0|0] "" X
 SG_ UMC_a023_adcSelfTest: 22|1@1+ (1,0) [0|0] "" X

BO_ 825 VCSEC_authentication: 8 VEH
 SG_ VCSEC_MCUCommandType: 36|3@1+ (1,0) [0|0] "" X
 SG_ VCSEC_alarmStatus: 43|4@1+ (1,0) [0|0] "" X
 SG_ VCSEC_authRequested: 60|1@1+ (1,0) [0|0] "" X
 SG_ VCSEC_authenticationStatus: 16|2@1+ (1,0) [0|0] "" X
 SG_ VCSEC_chargePortLockStatus: 18|1@1+ (1,0) [0|0] "" X
 SG_ VCSEC_frunkRequest: 34|2@1+ (1,0) [0|0] "" X
 SG_ VCSEC_immobilizerState: 48|3@1+ (1,0) [0|0] "" X
 SG_ VCSEC_keyChannelIndexed: 56|4@1+ (1,0) [0|0] "" X
 SG_ VCSEC_leftFrontLockStatus: 19|1@1+ (1,0) [0|0] "" X
 SG_ VCSEC_leftRearLockStatus: 20|1@1+ (1,0) [0|0] "" X
 SG_ VCSEC_lockIndicationRequest: 51|3@1+ (1,0) [0|0] "" X
 SG_ VCSEC_lockRequestType: 24|5@1+ (1,0) [0|0] "" X
 SG_ VCSEC_numberOfPubKeysOnWhitelist: 6|5@1+ (1,0) [0|0] "" X
 SG_ VCSEC_prsntRsnDeltaD: 3|1@1+ (1,0) [0|0] "" X
 SG_ VCSEC_prsntRsnDeltaP: 39|1@1+ (1,0) [0|0] "" X
 SG_ VCSEC_prsntRsnDeltaR: 4|1@1+ (1,0) [0|0] "" X
 SG_ VCSEC_prsntRsnHighThresholdC: 0|1@1+ (1,0) [0|0] "" X
 SG_ VCSEC_prsntRsnHighThresholdD: 1|1@1+ (1,0) [0|0] "" X
 SG_ VCSEC_prsntRsnHighThresholdP: 2|1@1+ (1,0) [0|0] "" X
 SG_ VCSEC_prsntRsnHighThresholdR: 5|1@1+ (1,0) [0|0] "" X
 SG_ VCSEC_rightFrontLockStatus: 21|1@1+ (1,0) [0|0] "" X
 SG_ VCSEC_rightRearLockStatus: 22|1@1+ (1,0) [0|0] "" X
 SG_ VCSEC_simpleLockStatus: 54|2@1+ (1,0) [0|0] "" X
 SG_ VCSEC_summonRequest: 29|3@1+ (1,0) [0|0] "" X
 SG_ VCSEC_trunkLockStatus: 23|1@1+ (1,0) [0|0] "" X
 SG_ VCSEC_trunkRequest: 32|2@1+ (1,0) [0|0] "" X
 SG_ VCSEC_usingModifiedMACAddress: 40|1@1+ (1,0) [0|0] "" X
 SG_ VCSEC_vehicleLockStatus: 12|4@1+ (1,0) [0|0] "" X

BO_ 826 ID33AUI_rangeSOC: 8 VehicleBus
 SG_ UI_idealRange : 16|10@1+ (1,0) [0|1023] "mi"  Receiver
 SG_ UI_Range : 0|10@1+ (1,0) [0|1023] "mi"  Receiver
 SG_ UI_SOC : 48|7@1+ (1,0) [0|127] "%"  Receiver
 SG_ UI_uSOE : 56|7@1+ (1,0) [0|127] "%"  Receiver
 SG_ UI_ratedWHpM : 32|10@1+ (1,0) [0|1023] "WHpM"  Receiver

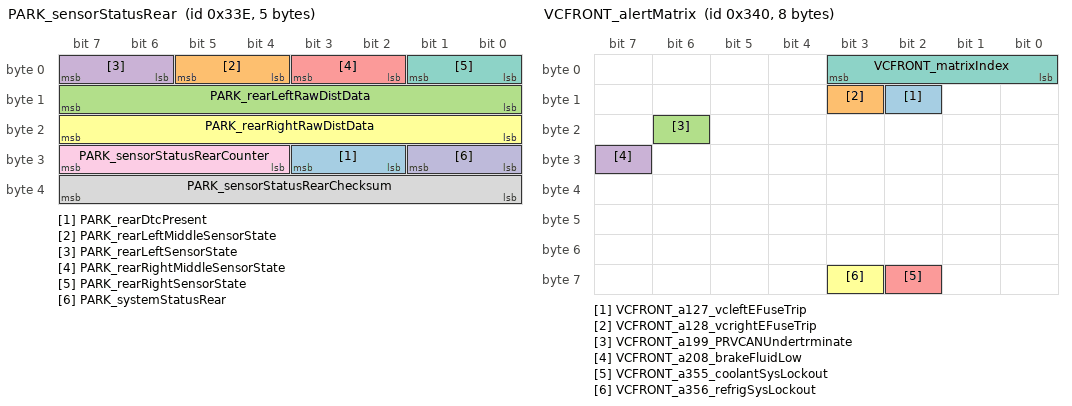
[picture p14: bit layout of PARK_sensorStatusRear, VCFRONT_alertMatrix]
BO_ 830 PARK_sensorStatusRear: 5 CH
 SG_ PARK_rearDtcPresent: 26|2@1+ (1,0) [0|0] "" X
 SG_ PARK_rearLeftMiddleSensorState: 4|2@1+ (1,0) [0|0] "" X
 SG_ PARK_rearLeftRawDistData: 8|8@1+ (1,0) [0|0] "cm" X
 SG_ PARK_rearLeftSensorState: 6|2@1+ (1,0) [0|0] "" X
 SG_ PARK_rearRightMiddleSensorState: 2|2@1+ (1,0) [0|0] "cm" X
 SG_ PARK_rearRightRawDistData: 16|8@1+ (1,0) [0|0] "cm" X
 SG_ PARK_rearRightSensorState: 0|2@1+ (1,0) [0|0] "" X
 SG_ PARK_sensorStatusRearChecksum: 32|8@1+ (1,0) [0|0] "" X
 SG_ PARK_sensorStatusRearCounter: 28|4@1+ (1,0) [0|0] "" X
 SG_ PARK_systemStatusRear: 24|2@1+ (1,0) [0|0] "" X

BO_ 831 FC_alertMatrix2: 8 VEH
 SG_ FC_a065_userData: 0|1@1+ (1,0) [0|0] "" X

BO_ 832 VCFRONT_alertMatrix: 8 GTW
 SG_ VCFRONT_a127_vcleftEFuseTrip : 10|1@1+ (1,0) [0|1] "" ODIN,UI
 SG_ VCFRONT_a128_vcrightEFuseTrip : 11|1@1+ (1,0) [0|1] "" ODIN,UI
 SG_ VCFRONT_a199_PRVCANUndertrminate : 22|1@1+ (1,0) [0|1] "" ODIN,UI
 SG_ VCFRONT_a208_brakeFluidLow : 31|1@1+ (1,0) [0|1] "" ODIN,UI
 SG_ VCFRONT_a355_coolantSysLockout : 58|1@1+ (1,0) [0|1] "" ODIN,UI
 SG_ VCFRONT_a356_refrigSysLockout : 59|1@1+ (1,0) [0|1] "" ODIN,UI
 SG_ VCFRONT_matrixIndex : 0|4@1+ (1,0) [0|15] "" UI

BO_ 837 PTC_info: 8 VEH
 SG_ PTC_infoIndex M: 0|8@1+ (1,0) [0|0] "" X
 SG_ PTC_infoBuildType m10: 8|3@1+ (1,0) [0|0] "" X
 SG_ PTC_infoBuildConfigId m10: 16|16@1+ (1,0) [0|0] "" X
 SG_ PTC_infoHardwareId m10: 32|16@1+ (1,0) [0|0] "" X
 SG_ PTC_infoComponentId m10: 48|16@1+ (1,0) [0|0] "" X
 SG_ PTC_infoPcbaId m11: 16|8@1+ (1,0) [0|0] "" X
 SG_ PTC_infoAssemblyId m11: 24|8@1+ (1,0) [0|0] "" X
 SG_ PTC_infoUsageId m11: 32|16@1+ (1,0) [0|0] "" X
 SG_ PTC_infoSubUsageId m11: 48|16@1+ (1,0) [0|0] "" X
 SG_ PTC_infoBootUdsProtoVersion m20: 8|8@1+ (1,0) [0|0] "" X
 SG_ PTC_infoBootCrc m20: 32|32@1+ (1,0) [0|0] "" X
 SG_ PTC_infoPlatformType m13: 8|8@1+ (1,0) [0|0] "" X
 SG_ PTC_infoAppCrc m13: 32|32@1+ (1,0) [0|0] "" X

BO_ 840 GTW_status: 1 VEH
 SG_ GTW_autopilotTrial: 0|1@1+ (1,0) [0|0] "" X
 SG_ GTW_vehicleVersionMatchStatus: 1|2@1+ (1,0) [0|0] "" X

BO_ 841 DAS_warningMatrix2: 8 VEH
 SG_ DAS_w129_mainCamExtNotCal: 0|1@1+ (1,0) [0|0] "" X
 SG_ DAS_w130_narrowCamExtNotCal: 1|1@1+ (1,0) [0|0] "" X
 SG_ DAS_w131_mainCamCalSaved: 2|1@1+ (1,0) [0|0] "" X
 SG_ DAS_w132_narrowCamCalSaved: 3|1@1+ (1,0) [0|0] "" X
 SG_ DAS_w133_mainCamInitFault: 4|1@1+ (1,0) [0|0] "" X
 SG_ DAS_w134_narrowCamInitFault: 5|1@1+ (1,0) [0|0] "" X
 SG_ DAS_w135_fisheyeCamInitFault: 6|1@1+ (1,0) [0|0] "" X
 SG_ DAS_w136_lPillarCamInitFault: 7|1@1+ (1,0) [0|0] "" X
 SG_ DAS_w137_rPillarCamInitFault: 8|1@1+ (1,0) [0|0] "" X
 SG_ DAS_w138_lRepeatCamInitFault: 9|1@1+ (1,0) [0|0] "" X
 SG_ DAS_w139_rRepeatCamInitFault: 10|1@1+ (1,0) [0|0] "" X
 SG_ DAS_w140_backupCamInitFault: 11|1@1+ (1,0) [0|0] "" X
 SG_ DAS_w141_ECU_Thermal_Issue: 12|1@1+ (1,0) [0|0] "" X
 SG_ DAS_w142_fwdCamPitchProblem: 13|1@1+ (1,0) [0|0] "" X
 SG_ DAS_w143_IDF_event: 14|1@1+ (1,0) [0|0] "" X
 SG_ DAS_w144_selfieCamInitFault: 15|1@1+ (1,0) [0|0] "" X
 SG_ DAS_w171_fisheyeCamExtNotCal: 42|1@1+ (1,0) [0|0] "" X
 SG_ DAS_w172_lPillarCamExtNotCal: 43|1@1+ (1,0) [0|0] "" X
 SG_ DAS_w173_rPillarCamExtNotCal: 44|1@1+ (1,0) [0|0] "" X
 SG_ DAS_w174_lRepeatCamExtNotCal: 45|1@1+ (1,0) [0|0] "" X
 SG_ DAS_w175_rRepeatCamExtNotCal: 46|1@1+ (1,0) [0|0] "" X
 SG_ DAS_w177_fisheyeCamCalSaved: 48|1@1+ (1,0) [0|0] "" X
 SG_ DAS_w178_lPillarCamCalSaved: 49|1@1+ (1,0) [0|0] "" X
 SG_ DAS_w179_rPillarCamCalSaved: 50|1@1+ (1,0) [0|0] "" X
 SG_ DAS_w180_lRepeatCamCalSaved: 51|1@1+ (1,0) [0|0] "" X
 SG_ DAS_w181_rRepeatCamCalSaved: 52|1@1+ (1,0) [0|0] "" X

BO_ 845 TAS_warningMatrix1: 8 VEH
 SG_ TAS_w001_WatchdogReset: 0|1@1+ (1,0) [0|0] "" X
 SG_ TAS_w002_PowerLossReset: 1|1@1+ (1,0) [0|0] "" X
 SG_ TAS_w003_SWAssertion: 2|1@1+ (1,0) [0|0] "" X
 SG_ TAS_w004_CANMIA: 3|1@1+ (1,0) [0|0] "" X
 SG_ TAS_w005_CANHighError: 4|1@1+ (1,0) [0|0] "" X
 SG_ TAS_w006_CANLowError: 5|1@1+ (1,0) [0|0] "" X
 SG_ TAS_w007_LINTimeout: 6|1@1+ (1,0) [0|0] "" X
 SG_ TAS_w008_LIN2Error: 7|1@1+ (1,0) [0|0] "" X
 SG_ TAS_w009_LIN3Error: 8|1@1+ (1,0) [0|0] "" X
 SG_ TAS_w010_ExtSupplyVoltError: 9|1@1+ (1,0) [0|0] "" X
 SG_ TAS_w011_ECUSupplyVoltError: 10|1@1+ (1,0) [0|0] "" X
 SG_ TAS_w012_CPUReset: 11|1@1+ (1,0) [0|0] "" X
 SG_ TAS_w013_Shared13: 12|1@1+ (1,0) [0|0] "" X
 SG_ TAS_w014_BridgeFault: 13|1@1+ (1,0) [0|0] "" X
 SG_ TAS_w015_NVMMAlert: 14|1@1+ (1,0) [0|0] "" X
 SG_ TAS_w016_MessageTimingError: 15|1@1+ (1,0) [0|0] "" X
 SG_ TAS_w017_AwakeForTooLong: 16|1@1+ (1,0) [0|0] "" X
 SG_ TAS_w018_ADCError: 17|1@1+ (1,0) [0|0] "" X
 SG_ TAS_w019_I2CError: 18|1@1+ (1,0) [0|0] "" X
 SG_ TAS_w020_PWMError: 19|1@1+ (1,0) [0|0] "" X
 SG_ TAS_w021_TaskSchedulerError: 20|1@1+ (1,0) [0|0] "" X
 SG_ TAS_w022_TaskInitError: 21|1@1+ (1,0) [0|0] "" X
 SG_ TAS_w023_SleepError: 22|1@1+ (1,0) [0|0] "" X
 SG_ TAS_w024_WakeError: 23|1@1+ (1,0) [0|0] "" X
 SG_ TAS_w025_CrashEvent: 24|1@1+ (1,0) [0|0] "" X
 SG_ TAS_w026_FlashMemoryError: 25|1@1+ (1,0) [0|0] "" X
 SG_ TAS_w027_NVRAMCorruption: 26|1@1+ (1,0) [0|0] "" X
 SG_ TAS_w028_NVRAMNotResponding: 27|1@1+ (1,0) [0|0] "" X
 SG_ TAS_w029_NVRAMUninitialized: 28|1@1+ (1,0) [0|0] "" X
 SG_ TAS_w030_PWMerrorFL: 29|1@1+ (1,0) [0|0] "" X
 SG_ TAS_w031_PWMerrorFR: 30|1@1+ (1,0) [0|0] "" X
 SG_ TAS_w032_PWMerrorRL: 31|1@1+ (1,0) [0|0] "" X
 SG_ TAS_w033_PWMerrorRR: 32|1@1+ (1,0) [0|0] "" X
 SG_ TAS_w034_PWMshortFL: 33|1@1+ (1,0) [0|0] "" X
 SG_ TAS_w035_PWMshortFR: 34|1@1+ (1,0) [0|0] "" X
 SG_ TAS_w036_PWMshortRL: 35|1@1+ (1,0) [0|0] "" X
 SG_ TAS_w037_PWMshortRR: 36|1@1+ (1,0) [0|0] "" X
 SG_ TAS_w038_PWMopenFL: 37|1@1+ (1,0) [0|0] "" X
 SG_ TAS_w039_PWMopenFR: 38|1@1+ (1,0) [0|0] "" X
 SG_ TAS_w040_PWMopenRL: 39|1@1+ (1,0) [0|0] "" X
 SG_ TAS_w041_PWMopenRR: 40|1@1+ (1,0) [0|0] "" X

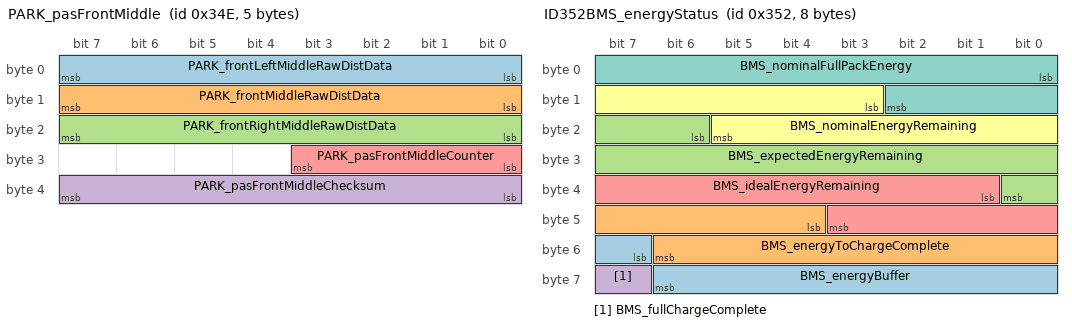
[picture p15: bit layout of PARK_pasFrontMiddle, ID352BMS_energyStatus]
BO_ 846 PARK_pasFrontMiddle: 5 CH
 SG_ PARK_frontLeftMiddleRawDistData: 0|8@1+ (1,0) [0|0] "cm" X
 SG_ PARK_frontMiddleRawDistData: 8|8@1+ (1,0) [0|0] "cm" X
 SG_ PARK_frontRightMiddleRawDistData: 16|8@1+ (1,0) [0|0] "cm" X
 SG_ PARK_pasFrontMiddleChecksum: 32|8@1+ (1,0) [0|0] "" X
 SG_ PARK_pasFrontMiddleCounter: 24|4@1+ (1,0) [0|0] "" X

BO_ 848 APS_warningMatrix3: 8 CH
 SG_ APS_w193_camWindshieldUnclean: 0|1@1+ (1,0) [0|0] "" X
 SG_ APS_w194_accDriverResumeRqrd: 1|1@1+ (1,0) [0|0] "" X
 SG_ APS_w195_scwUnavailable: 2|1@1+ (1,0) [0|0] "" X
 SG_ APS_w196_stopSignWarning: 3|1@1+ (1,0) [0|0] "" X
 SG_ APS_w197_redLightWarning: 4|1@1+ (1,0) [0|0] "" X
 SG_ APS_w198_tsrUnavailable: 5|1@1+ (1,0) [0|0] "" X
 SG_ APS_w199_apcAbort: 6|1@1+ (1,0) [0|0] "" X
 SG_ APS_w200_lcSlowdown: 7|1@1+ (1,0) [0|0] "" X
 SG_ APS_w201_lcAborting: 8|1@1+ (1,0) [0|0] "" X
 SG_ APS_w202_scwNoisyEnvironment: 9|1@1+ (1,0) [0|0] "" X
 SG_ APS_w203_apcActivation: 10|1@1+ (1,0) [0|0] "" X
 SG_ APS_w204_apcFinalFront: 11|1@1+ (1,0) [0|0] "" X
 SG_ APS_w205_apcFinalRear: 12|1@1+ (1,0) [0|0] "" X
 SG_ APS_w206_autosteerNotEnabled: 13|1@1+ (1,0) [0|0] "" X
 SG_ APS_w207_autosteerUnavailable: 14|1@1+ (1,0) [0|0] "" X
 SG_ APS_w208_rackDetected: 15|1@1+ (1,0) [0|0] "" X
 SG_ APS_w209_autoSummonRequest: 16|1@1+ (1,0) [0|0] "" X
 SG_ APS_w210_camObstrcted: 17|1@1+ (1,0) [0|0] "" X
 SG_ APS_w211_accNoSeatBelt: 18|1@1+ (1,0) [0|0] "" X
 SG_ APS_w212_lcUnavailableStrikeOut: 19|1@1+ (1,0) [0|0] "" X
 SG_ APS_w213_autosteerStruckOut: 20|1@1+ (1,0) [0|0] "" X
 SG_ APS_w214_driverNotIntracting: 21|1@1+ (1,0) [0|0] "" X
 SG_ APS_w215_contDriverNotIntracting: 22|1@1+ (1,0) [0|0] "" X
 SG_ APS_w216_driverOverriding: 23|1@1+ (1,0) [0|0] "" X
 SG_ APS_w217_lcUnavailableSpeeding: 24|1@1+ (1,0) [0|0] "" X
 SG_ APS_w218_lcSpeedExceededLimit: 25|1@1+ (1,0) [0|0] "" X
 SG_ APS_w219_lcTempUnavailableSpeed: 26|1@1+ (1,0) [0|0] "" X
 SG_ APS_w220_lcTempUnavailableRoad: 27|1@1+ (1,0) [0|0] "" X
 SG_ APS_w221_accRadarBlind: 28|1@1+ (1,0) [0|0] "" X
 SG_ APS_w222_accCameraBlind: 29|1@1+ (1,0) [0|0] "" X
 SG_ APS_w223_accObjectInPath: 30|1@1+ (1,0) [0|0] "" X
 SG_ APS_w224_accCameraCalibration: 31|1@1+ (1,0) [0|0] "" X
 SG_ APS_w225_lcDegradedVisSpeedLmt: 32|1@1+ (1,0) [0|0] "" X
 SG_ APS_w226_lcCamCalNeededSpeedLmt: 33|1@1+ (1,0) [0|0] "" X
 SG_ APS_w227_virtualWallBlocked: 34|1@1+ (1,0) [0|0] "" X
 SG_ APS_w228_DEPRECATED: 35|1@1+ (1,0) [0|0] "" X
 SG_ APS_w229_alcUltrasoundDamaged: 36|1@1+ (1,0) [0|0] "" X
 SG_ APS_w230_alcUltrasoundBlocked: 37|1@1+ (1,0) [0|0] "" X

BO_ 849 RCM_info: 8 CH
 SG_ RCM_infoIndex M: 0|8@1+ (1,0) [0|0] "" X
 SG_ RCM_infoBuildType m10: 8|8@1+ (1,0) [0|0] "" X
 SG_ RCM_infoComponentID m10: 48|16@1+ (1,0) [0|0] "" X
 SG_ RCM_infoPcbaID m11: 16|8@1+ (1,0) [0|0] "" X
 SG_ RCM_infoAssemblyID m11: 24|8@1+ (1,0) [0|0] "" X
 SG_ RCM_infoUsageID m11: 32|16@1+ (1,0) [0|0] "" X
 SG_ RCM_infoBootUdsProtoVersion m20: 8|8@1+ (1,0) [0|0] "" X
 SG_ RCM_infoBootloaderCRC m20: 32|32@1+ (1,0) [0|0] "" X
 SG_ RCM_infoApplicationCRC m13: 32|32@1+ (1,0) [0|0] "" X
 SG_ RCM_infoVariantCRC m22: 32|32@1+ (1,0) [0|0] "" X

BO_ 850 ID352BMS_energyStatus: 8 VehicleBus
 SG_ BMS_energyBuffer : 55|8@1+ (0.1,0) [0|25.4] "KWh"  Receiver
 SG_ BMS_energyToChargeComplete : 44|11@1+ (0.1,0) [0|204.6] "KWh"  Receiver
 SG_ BMS_expectedEnergyRemaining : 22|11@1+ (0.1,0) [0|204.6] "KWh"  Receiver
 SG_ BMS_fullChargeComplete : 63|1@1+ (1,0) [0|1] ""  Receiver
 SG_ BMS_idealEnergyRemaining : 33|11@1+ (0.1,0) [0|204.6] "KWh"  Receiver
 SG_ BMS_nominalEnergyRemaining : 11|11@1+ (0.1,0) [0|204.6] "KWh"  Receiver
 SG_ BMS_nominalFullPackEnergy : 0|11@1+ (0.1,0) [0|204.6] "KWh"  Receiver

BO_ 851 ID353UI_status: 8 VehicleBus
 SG_ UI_audioActive : 1|1@1+ (1,0) [0|1] ""  Receiver
 SG_ UI_autopilotTrial : 12|2@1+ (1,0) [0|3] ""  Receiver
 SG_ UI_bluetoothActive : 2|1@1+ (1,0) [0|1] ""  Receiver
 SG_ UI_cameraActive : 41|1@1+ (1,0) [0|1] ""  Receiver
 SG_ UI_cellActive : 3|1@1+ (1,0) [0|1] ""  Receiver
 SG_ UI_cellConnected : 10|1@1+ (1,0) [0|1] ""  Receiver
 SG_ UI_cellNetworkTechnology : 19|4@1+ (1,0) [0|15] ""  Receiver
 SG_ UI_cellReceiverPower : 24|8@1+ (1,-128) [-128|127] "dB"  Receiver
 SG_ UI_cellSignalBars : 42|3@1+ (1,0) [0|7] ""  Receiver
 SG_ UI_cpuTemperature : 56|8@1- (1,40) [-20|100] "C"  Receiver
 SG_ UI_developmentCar : 40|1@1+ (1,0) [0|1] ""  Receiver
 SG_ UI_displayOn : 5|1@1+ (1,0) [0|1] ""  Receiver
 SG_ UI_displayReady : 4|1@1+ (1,0) [0|1] ""  Receiver
 SG_ UI_factoryReset : 14|2@1+ (1,0) [0|3] ""  Receiver
 SG_ UI_falseTouchCounter : 32|8@1+ (1,0) [0|255] "1"  Receiver
 SG_ UI_gpsActive : 16|1@1+ (1,0) [0|1] ""  Receiver
 SG_ UI_pcbTemperature : 48|8@1- (1,40) [-20|100] "C"  Receiver
 SG_ UI_radioActive : 18|1@1+ (1,0) [0|1] ""  Receiver
 SG_ UI_readyForDrive : 9|1@1+ (1,0) [0|1] ""  Receiver
 SG_ UI_screenshotActive : 17|1@1+ (1,0) [0|1] ""  Receiver
 SG_ UI_systemActive : 8|1@1+ (1,0) [0|1] ""  Receiver
 SG_ UI_touchActive : 0|1@1+ (1,0) [0|1] ""  Receiver
 SG_ UI_vpnActive : 11|1@1+ (1,0) [0|1] ""  Receiver
 SG_ UI_wifiActive : 6|1@1+ (1,0) [0|1] ""  Receiver
 SG_ UI_wifiConnected : 7|1@1+ (1,0) [0|1] ""  Receiver

BO_ 854 DI_alertMatrix1: 8 VEH
 SG_ DI_a001_hwPhaseAgateDrive: 0|1@1+ (1,0) [0|0] "" X
 SG_ DI_a002_hwPhaseBgateDrive: 1|1@1+ (1,0) [0|0] "" X
 SG_ DI_a003_hwPhaseCgateDrive: 2|1@1+ (1,0) [0|0] "" X
 SG_ DI_a004_hwPhaseApeak: 3|1@1+ (1,0) [0|0] "" X
 SG_ DI_a005_hwPhaseBpeak: 4|1@1+ (1,0) [0|0] "" X
 SG_ DI_a006_hwPhaseCpeak: 5|1@1+ (1,0) [0|0] "" X
 SG_ DI_a007_hwHvilNotPresent: 6|1@1+ (1,0) [0|0] "" X
 SG_ DI_a008_hwEncoderA: 7|1@1+ (1,0) [0|0] "" X
 SG_ DI_a009_hwEncoderB: 8|1@1+ (1,0) [0|0] "" X
 SG_ DI_a011_swPowerStageNotReady: 10|1@1+ (1,0) [0|0] "" X
 SG_ DI_a012_accel5VSupply: 11|1@1+ (1,0) [0|0] "" X
 SG_ DI_a014_activeDamping: 13|1@1+ (1,0) [0|0] "" X
 SG_ DI_a015_immobilizer: 14|1@1+ (1,0) [0|0] "" X
 SG_ DI_a016_safeStateApplied: 15|1@1+ (1,0) [0|0] "" X
 SG_ DI_a017_hwPedalMonitor: 16|1@1+ (1,0) [0|0] "" X
 SG_ DI_a018_hw12vSupplyUV: 17|1@1+ (1,0) [0|0] "" X
 SG_ DI_a019_hwAccelPedalPower: 18|1@1+ (1,0) [0|0] "" X
 SG_ DI_a020_hwMotorEncoder: 19|1@1+ (1,0) [0|0] "" X
 SG_ DI_a021_hwBusOV: 20|1@1+ (1,0) [0|0] "" X
 SG_ DI_a022_hw5vSupplyUV: 21|1@1+ (1,0) [0|0] "" X
 SG_ DI_a023_carNotParked: 22|1@1+ (1,0) [0|0] "" X
 SG_ DI_a024_selfTest: 23|1@1+ (1,0) [0|0] "" X
 SG_ DI_a025_phaseApeak: 24|1@1+ (1,0) [0|0] "" X
 SG_ DI_a026_phaseBpeak: 25|1@1+ (1,0) [0|0] "" X
 SG_ DI_a027_phaseCpeak: 26|1@1+ (1,0) [0|0] "" X
 SG_ DI_a028_phaseArms: 27|1@1+ (1,0) [0|0] "" X
 SG_ DI_a029_phaseBrms: 28|1@1+ (1,0) [0|0] "" X
 SG_ DI_a030_phaseCrms: 29|1@1+ (1,0) [0|0] "" X
 SG_ DI_a031_phaseAcurrentOffset: 30|1@1+ (1,0) [0|0] "" X
 SG_ DI_a032_phaseBcurrentOffset: 31|1@1+ (1,0) [0|0] "" X
 SG_ DI_a033_phaseAcurrentSensor: 32|1@1+ (1,0) [0|0] "" X
 SG_ DI_a034_phaseBcurrentSensor: 33|1@1+ (1,0) [0|0] "" X
 SG_ DI_a035_phaseCurrentBalance: 34|1@1+ (1,0) [0|0] "" X
 SG_ DI_a036_busOV: 35|1@1+ (1,0) [0|0] "" X
 SG_ DI_a037_busUV: 36|1@1+ (1,0) [0|0] "" X
 SG_ DI_a038_busVsensor: 37|1@1+ (1,0) [0|0] "" X
 SG_ DI_a039_noRegen: 38|1@1+ (1,0) [0|0] "" X
 SG_ DI_a040_disMIA: 39|1@1+ (1,0) [0|0] "" X
 SG_ DI_a041_driverBrakeApplyCheck: 40|1@1+ (1,0) [0|0] "" X
 SG_ DI_a042_inletSensor: 41|1@1+ (1,0) [0|0] "" X
 SG_ DI_a043_outletOT: 42|1@1+ (1,0) [0|0] "" X
 SG_ DI_a044_outletUT: 43|1@1+ (1,0) [0|0] "" X
 SG_ DI_a045_outletSensor: 44|1@1+ (1,0) [0|0] "" X
 SG_ DI_a046_statorOT: 45|1@1+ (1,0) [0|0] "" X
 SG_ DI_a047_statorSensor1: 46|1@1+ (1,0) [0|0] "" X
 SG_ DI_a050_noStatorSensor: 49|1@1+ (1,0) [0|0] "" X
 SG_ DI_a051_batteryOvercurrent: 50|1@1+ (1,0) [0|0] "" X
 SG_ DI_a054_driveInverterOT: 53|1@1+ (1,0) [0|0] "" X
 SG_ DI_a055_trqCrossCheck: 54|1@1+ (1,0) [0|0] "" X
 SG_ DI_a056_ambientOT: 55|1@1+ (1,0) [0|0] "" X
 SG_ DI_a057_ambientUT: 56|1@1+ (1,0) [0|0] "" X
 SG_ DI_a058_ambientSensor: 57|1@1+ (1,0) [0|0] "" X
 SG_ DI_a059_heatsinkOT: 58|1@1+ (1,0) [0|0] "" X
 SG_ DI_a060_heatsinkUT: 59|1@1+ (1,0) [0|0] "" X
 SG_ DI_a061_heatsinkSensor: 60|1@1+ (1,0) [0|0] "" X
 SG_ DI_a062_systemLimpMode: 61|1@1+ (1,0) [0|0] "" X
 SG_ DI_a063_systemGracefulPowerOff: 62|1@1+ (1,0) [0|0] "" X
 SG_ DI_a064_torqueIntervention: 63|1@1+ (1,0) [0|0] "" X

BO_ 855 DI_alertMatrix2: 8 VEH
 SG_ DI_a065_canHardwareBusB: 0|1@1+ (1,0) [0|0] "" X
 SG_ DI_a066_canDataBusB: 1|1@1+ (1,0) [0|0] "" X
 SG_ DI_a067_canOverrunBusB: 2|1@1+ (1,0) [0|0] "" X
 SG_ DI_a070_12vSupplySensor: 5|1@1+ (1,0) [0|0] "" X
 SG_ DI_a071_busDisconnected: 6|1@1+ (1,0) [0|0] "" X
 SG_ DI_a072_gateDriveFaultCounter: 7|1@1+ (1,0) [0|0] "" X
 SG_ DI_a073_motorSpeed: 8|1@1+ (1,0) [0|0] "" X
 SG_ DI_a074_motorEncoder: 9|1@1+ (1,0) [0|0] "" X
 SG_ DI_a075_motorSpeedMismatch: 10|1@1+ (1,0) [0|0] "" X
 SG_ DI_a076_12vSupplyOV: 11|1@1+ (1,0) [0|0] "" X
 SG_ DI_a077_12vSupplyUV: 12|1@1+ (1,0) [0|0] "" X
 SG_ DI_a078_adcRefLow: 13|1@1+ (1,0) [0|0] "" X
 SG_ DI_a079_adcRefHigh: 14|1@1+ (1,0) [0|0] "" X
 SG_ DI_a080_accelSynch: 15|1@1+ (1,0) [0|0] "" X
 SG_ DI_a081_accelTrack1: 16|1@1+ (1,0) [0|0] "" X
 SG_ DI_a082_accelTrack2: 17|1@1+ (1,0) [0|0] "" X
 SG_ DI_a083_brakePedalSensor: 18|1@1+ (1,0) [0|0] "" X
 SG_ DI_a085_proximityInEnable: 20|1@1+ (1,0) [0|0] "" X
 SG_ DI_a086_hvilNotPresent: 21|1@1+ (1,0) [0|0] "" X
 SG_ DI_a087_gtwMIA: 22|1@1+ (1,0) [0|0] "" X
 SG_ DI_a088_uiMIA: 23|1@1+ (1,0) [0|0] "" X
 SG_ DI_a089_sccmMIA: 24|1@1+ (1,0) [0|0] "" X
 SG_ DI_a090_pmMIA: 25|1@1+ (1,0) [0|0] "" X
 SG_ DI_a091_espMIA: 26|1@1+ (1,0) [0|0] "" X
 SG_ DI_a092_bmsMIA: 27|1@1+ (1,0) [0|0] "" X
 SG_ DI_a093_canHardwareBusA: 28|1@1+ (1,0) [0|0] "" X
 SG_ DI_a094_canDataBusA: 29|1@1+ (1,0) [0|0] "" X
 SG_ DI_a095_canOverrunBusA: 30|1@1+ (1,0) [0|0] "" X
 SG_ DI_a096_memoryError: 31|1@1+ (1,0) [0|0] "" X
 SG_ DI_a097_eepromError: 32|1@1+ (1,0) [0|0] "" X
 SG_ DI_a098_intTimeTooLong: 33|1@1+ (1,0) [0|0] "" X
 SG_ DI_a099_threadOverrun: 34|1@1+ (1,0) [0|0] "" X
 SG_ DI_a100_assertion: 35|1@1+ (1,0) [0|0] "" X
 SG_ DI_a103_lowFlow: 38|1@1+ (1,0) [0|0] "" X
 SG_ DI_a104_proximityIrrational: 39|1@1+ (1,0) [0|0] "" X
 SG_ DI_a105_cpMIA: 40|1@1+ (1,0) [0|0] "" X
 SG_ DI_a106_absMIA: 41|1@1+ (1,0) [0|0] "" X
 SG_ DI_a108_stateTrans: 43|1@1+ (1,0) [0|0] "" X
 SG_ DI_a109_cruiseMIA: 44|1@1+ (1,0) [0|0] "" X
 SG_ DI_a110_brakeMIA: 45|1@1+ (1,0) [0|0] "" X
 SG_ DI_a112_noPhaseCurrent: 47|1@1+ (1,0) [0|0] "" X
 SG_ DI_a113_noFuncHeatsinkSensor: 48|1@1+ (1,0) [0|0] "" X
 SG_ DI_a114_noMotorSpeed: 49|1@1+ (1,0) [0|0] "" X
 SG_ DI_a115_heatsinkTempImbalance: 50|1@1+ (1,0) [0|0] "" X
 SG_ DI_a116_powerConvIrrational: 51|1@1+ (1,0) [0|0] "" X
 SG_ DI_a117_diMIA: 52|1@1+ (1,0) [0|0] "" X
 SG_ DI_a121_motorControlRegulation: 56|1@1+ (1,0) [0|0] "" X
 SG_ DI_a122_highStackUsage: 57|1@1+ (1,0) [0|0] "" X
 SG_ DI_a123_lossMotorControl: 58|1@1+ (1,0) [0|0] "" X
 SG_ DI_a124_cruiseFault: 59|1@1+ (1,0) [0|0] "" X
 SG_ DI_a125_noBatteryPower: 60|1@1+ (1,0) [0|0] "" X
 SG_ DI_a126_limpMode: 61|1@1+ (1,0) [0|0] "" X
 SG_ DI_a127_gracefulPowerOff: 62|1@1+ (1,0) [0|0] "" X

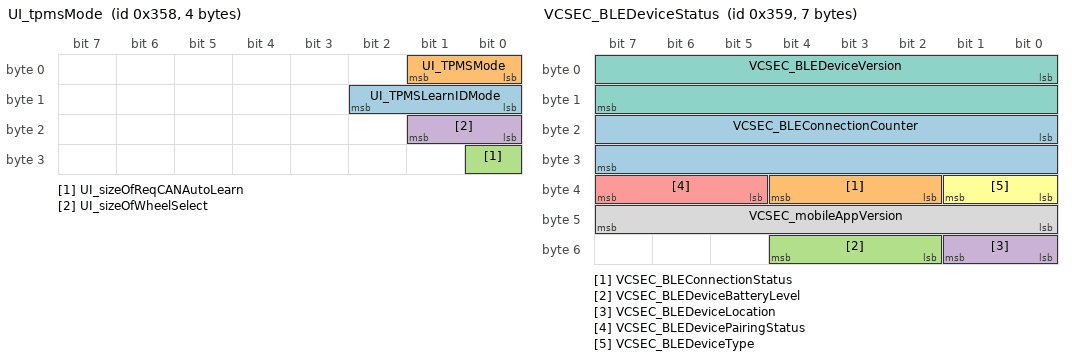
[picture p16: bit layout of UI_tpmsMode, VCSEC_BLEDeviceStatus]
BO_ 856 UI_tpmsMode: 4 VEH
 SG_ UI_TPMSLearnIDMode: 8|3@1+ (1,0) [0|0] "" X
 SG_ UI_TPMSMode: 0|2@1+ (1,0) [0|0] "" X
 SG_ UI_sizeOfReqCANAutoLearn: 24|1@1+ (1,0) [0|0] "" X
 SG_ UI_sizeOfWheelSelect: 16|2@1+ (1,0) [0|0] "" X

BO_ 857 VCSEC_BLEDeviceStatus: 7 VEH
 SG_ VCSEC_BLEConnectionCounter: 16|16@1+ (1,0) [0|0] "" X
 SG_ VCSEC_BLEConnectionStatus: 34|3@1+ (1,0) [0|0] "" X
 SG_ VCSEC_BLEDeviceBatteryLevel: 50|3@1+ (1,0) [0|0] "" X
 SG_ VCSEC_BLEDeviceLocation: 48|2@1+ (1,0) [0|0] "" X
 SG_ VCSEC_BLEDevicePairingStatus: 37|3@1+ (1,0) [0|0] "" X
 SG_ VCSEC_BLEDeviceType: 32|2@1+ (1,0) [0|0] "" X
 SG_ VCSEC_BLEDeviceVersion: 0|16@1+ (1,0) [0|0] "" X
 SG_ VCSEC_mobileAppVersion: 40|8@1+ (1,0) [0|0] "" X

BO_ 858 DIF_alertMatrix3: 8 GTW
 SG_ DIF_a154_resolver : 25|1@1+ (1,0) [0|1] "" ODIN,UI

BO_ 859 DI_alertMatrix4: 8 VEH
 SG_ DI_a193_vdcEspBrakeTorqueFr: 0|1@1+ (1,0) [0|0] "" X
 SG_ DI_a194_vdcEspBrakeTorqueRe: 1|1@1+ (1,0) [0|0] "" X
 SG_ DI_a195_vdcEspSlipFr: 2|1@1+ (1,0) [0|0] "" X
 SG_ DI_a196_vdcEspSlipRe: 3|1@1+ (1,0) [0|0] "" X
 SG_ DI_a197_vdcEspWheelSaturations: 4|1@1+ (1,0) [0|0] "" X
 SG_ DI_a198_vdcEspMCPressAndSteering: 5|1@1+ (1,0) [0|0] "" X
 SG_ DI_a199_vdcFaulted: 6|1@1+ (1,0) [0|0] "" X
 SG_ DI_a200_vdcModelBasedPlausibility: 7|1@1+ (1,0) [0|0] "" X
 SG_ DI_a201_regenLimited: 8|1@1+ (1,0) [0|0] "" X
 SG_ DI_a202_excessHeatUnavailable: 9|1@1+ (1,0) [0|0] "" X
 SG_ DI_a203_TCReducedByADD: 10|1@1+ (1,0) [0|0] "" X
 SG_ DI_a204_vdcRcmLongitudinal: 11|1@1+ (1,0) [0|0] "" X
 SG_ DI_a205_vdcRcmLateral: 12|1@1+ (1,0) [0|0] "" X
 SG_ DI_a206_vdcRcmVertical: 13|1@1+ (1,0) [0|0] "" X
 SG_ DI_a207_vdcPowertrainTorqueFr: 14|1@1+ (1,0) [0|0] "" X
 SG_ DI_a208_vdcPowertrainTorqueRe: 15|1@1+ (1,0) [0|0] "" X
 SG_ DI_a209_vdcVehicleSpeed: 16|1@1+ (1,0) [0|0] "" X
 SG_ DI_a210_vdcOtherControllerStates: 17|1@1+ (1,0) [0|0] "" X
 SG_ DI_a211_vdcMotorSpeeds: 18|1@1+ (1,0) [0|0] "" X
 SG_ DI_a212_velEstWheelSpeedCGFr: 19|1@1+ (1,0) [0|0] "" X
 SG_ DI_a213_velEstWheelSpeedCGRe: 20|1@1+ (1,0) [0|0] "" X
 SG_ DI_a214_velEstWheelSpeedNonCGFr: 21|1@1+ (1,0) [0|0] "" X
 SG_ DI_a215_velEstWheelSpeedNonCGRe: 22|1@1+ (1,0) [0|0] "" X
 SG_ DI_a216_vdcMBPAlmostTripped: 23|1@1+ (1,0) [0|0] "" X
 SG_ DI_a217_vdcOutputIrrational: 24|1@1+ (1,0) [0|0] "" X
 SG_ DI_a218_vdcOSPreControlActive: 25|1@1+ (1,0) [0|0] "" X
 SG_ DI_a219_vdcOversteerdMzActive: 26|1@1+ (1,0) [0|0] "" X
 SG_ DI_a220_vdcUndersteerDecelActive: 27|1@1+ (1,0) [0|0] "" X
 SG_ DI_a221_vdcUndersteerdMzActive: 28|1@1+ (1,0) [0|0] "" X
 SG_ DI_a222_vdcDisabled: 29|1@1+ (1,0) [0|0] "" X
 SG_ DI_a223_tractionControlDisabled: 30|1@1+ (1,0) [0|0] "" X
 SG_ DI_a224_brakeOverTemp: 31|1@1+ (1,0) [0|0] "" X
 SG_ DI_a225_tmpEstPlausibility: 32|1@1+ (1,0) [0|0] "" X
 SG_ DI_a226_sysStartConditionNotMet: 33|1@1+ (1,0) [0|0] "" X
 SG_ DI_a227_contactorsNotClosed: 34|1@1+ (1,0) [0|0] "" X
 SG_ DI_a228_brakeTempEstUnavailable: 35|1@1+ (1,0) [0|0] "" X
 SG_ DI_a229_batteryIsHeating: 36|1@1+ (1,0) [0|0] "" X
 SG_ DI_a230_cmpMIA: 37|1@1+ (1,0) [0|0] "" X
 SG_ DI_a231_ptcMIA: 38|1@1+ (1,0) [0|0] "" X
 SG_ DI_a232_velocityEstimatorDegraded: 39|1@1+ (1,0) [0|0] "" X
 SG_ DI_a233_diMsgMissed: 40|1@1+ (1,0) [0|0] "" X
 SG_ DI_a234_pcsMIA: 41|1@1+ (1,0) [0|0] "" X
 SG_ DI_a235_trackModeActive: 42|1@1+ (1,0) [0|0] "" X
 SG_ DI_a238_brakeOverTempBrembo: 45|1@1+ (1,0) [0|0] "" X
 SG_ DI_a239_neutralRequestByPM: 46|1@1+ (1,0) [0|0] "" X
 SG_ DI_a241_systemThermallyLimited: 48|1@1+ (1,0) [0|0] "" X

BO_ 861 IBST_alertMatrix: 8 CH
 SG_ IBST_matrixIndex M: 0|4@1+ (1,0) [0|0] "" X
 SG_ IBST_a001_microSupplyError m0: 4|1@1+ (1,0) [0|0] "" X
 SG_ IBST_a002_HWBISTError m0: 5|1@1+ (1,0) [0|0] "" X
 SG_ IBST_a003_RAMFault m0: 6|1@1+ (1,0) [0|0] "" X
 SG_ IBST_a004_flashFault m0: 7|1@1+ (1,0) [0|0] "" X
 SG_ IBST_a005_microSafetyFault m0: 8|1@1+ (1,0) [0|0] "" X
 SG_ IBST_a006_microSafetyLogicFault m0: 9|1@1+ (1,0) [0|0] "" X
 SG_ IBST_a007_RBCPUException m0: 10|1@1+ (1,0) [0|0] "" X
 SG_ IBST_a008_stackOverUnderFlow m0: 11|1@1+ (1,0) [0|0] "" X
 SG_ IBST_a009_systemErrorHook m0: 12|1@1+ (1,0) [0|0] "" X
 SG_ IBST_a010_OSErrorHook m0: 13|1@1+ (1,0) [0|0] "" X
 SG_ IBST_a011_systemTaskOverRun m0: 14|1@1+ (1,0) [0|0] "" X
 SG_ IBST_a012_OSTaskSchemeError m0: 15|1@1+ (1,0) [0|0] "" X
 SG_ IBST_a013_systemTaskJitter m0: 16|1@1+ (1,0) [0|0] "" X
 SG_ IBST_a014_DMATransferError m0: 17|1@1+ (1,0) [0|0] "" X
 SG_ IBST_a015_asicOscillatorError m0: 18|1@1+ (1,0) [0|0] "" X
 SG_ IBST_a016_RBBLMShaftShiftError m0: 19|1@1+ (1,0) [0|0] "" X
 SG_ IBST_a017_assertionFault m0: 20|1@1+ (1,0) [0|0] "" X
 SG_ IBST_a018_unsupportedHW m0: 21|1@1+ (1,0) [0|0] "" X
 SG_ IBST_a019_supplyASICInitFault m0: 22|1@1+ (1,0) [0|0] "" X
 SG_ IBST_a020_VPREU5VOutOfRange m0: 23|1@1+ (1,0) [0|0] "" X
 SG_ IBST_a021_IREFOutOfRange m0: 24|1@1+ (1,0) [0|0] "" X
 SG_ IBST_a022_U5VTestFault m0: 25|1@1+ (1,0) [0|0] "" X
 SG_ IBST_a023_U5VOutOfRange m0: 26|1@1+ (1,0) [0|0] "" X
 SG_ IBST_a024_chargePumpFault m0: 27|1@1+ (1,0) [0|0] "" X
 SG_ IBST_a025_ecuClockTestFault m0: 28|1@1+ (1,0) [0|0] "" X
 SG_ IBST_a026_ecuBistCmdTestFault m0: 29|1@1+ (1,0) [0|0] "" X
 SG_ IBST_a027_ecuFastWdTestFault m0: 30|1@1+ (1,0) [0|0] "" X
 SG_ IBST_a028_ecuBistFaultCtrFault m0: 31|1@1+ (1,0) [0|0] "" X
 SG_ IBST_a029_ecuErrpinCounterFault m0: 32|1@1+ (1,0) [0|0] "" X
 SG_ IBST_a030_ecuEnableElLowFault m0: 33|1@1+ (1,0) [0|0] "" X
 SG_ IBST_a031_decoupleBitTestFault m0: 34|1@1+ (1,0) [0|0] "" X
 SG_ IBST_a032_ecuEnableElHighFault m0: 35|1@1+ (1,0) [0|0] "" X
 SG_ IBST_a033_ecuWdStartuptestFault m0: 36|1@1+ (1,0) [0|0] "" X
 SG_ IBST_a034_ecuEnableHyHighFault m0: 37|1@1+ (1,0) [0|0] "" X
 SG_ IBST_a035_ecuEnableHyLowFault m0: 38|1@1+ (1,0) [0|0] "" X
 SG_ IBST_a036_MRGPathTestFault m0: 39|1@1+ (1,0) [0|0] "" X
 SG_ IBST_a037_ecuWdSContinuousError m0: 40|1@1+ (1,0) [0|0] "" X
 SG_ IBST_a038_ecuEnContinuousError m0: 41|1@1+ (1,0) [0|0] "" X
 SG_ IBST_a039_GTMRefFrequencyError m0: 42|1@1+ (1,0) [0|0] "" X
 SG_ IBST_a040_GTMTbuMonError m0: 43|1@1+ (1,0) [0|0] "" X
 SG_ IBST_a041_micAsicClkInError m0: 44|1@1+ (1,0) [0|0] "" X
 SG_ IBST_a042_micAsicInitTestError m0: 45|1@1+ (1,0) [0|0] "" X
 SG_ IBST_a043_micSpiTransferError m0: 46|1@1+ (1,0) [0|0] "" X
 SG_ IBST_a044_NvMEepromWIP m0: 47|1@1+ (1,0) [0|0] "" X
 SG_ IBST_a045_WdhAsicWdErrorCntStuck m0: 48|1@1+ (1,0) [0|0] "" X
 SG_ IBST_a046_WdhAsicWdErrorCntLimit m0: 49|1@1+ (1,0) [0|0] "" X
 SG_ IBST_a047_WdhAsicWdCmdMissing m0: 50|1@1+ (1,0) [0|0] "" X
 SG_ IBST_a048_WdhSwBistConCnt m0: 51|1@1+ (1,0) [0|0] "" X
 SG_ IBST_a049_WdhTaskMonConCnt m0: 52|1@1+ (1,0) [0|0] "" X
 SG_ IBST_a050_VPreExternalFeeding m0: 53|1@1+ (1,0) [0|0] "" X
 SG_ IBST_a051_ecuBandgap m0: 54|1@1+ (1,0) [0|0] "" X
 SG_ IBST_a052_AdcPinTest m0: 55|1@1+ (1,0) [0|0] "" X
 SG_ IBST_a053_AdcSelftestC5P m0: 56|1@1+ (1,0) [0|0] "" X
 SG_ IBST_a054_AdcPeripheralFault m0: 57|1@1+ (1,0) [0|0] "" X
 SG_ IBST_a055_UB6SupplyPathFault m0: 58|1@1+ (1,0) [0|0] "" X
 SG_ IBST_a056_UB6PlausiMonFault m0: 59|1@1+ (1,0) [0|0] "" X
 SG_ IBST_a057_microRegisterFault m0: 60|1@1+ (1,0) [0|0] "" X
 SG_ IBST_a058_NvMWriteCycleExceed m0: 61|1@1+ (1,0) [0|0] "" X
 SG_ IBST_a059_NvMEepromSize m0: 62|1@1+ (1,0) [0|0] "" X
 SG_ IBST_a060_NvMMigrationFault m0: 63|1@1+ (1,0) [0|0] "" X
 SG_ IBST_a061_AswSystemTimeOut m1: 4|1@1+ (1,0) [0|0] "" X
 SG_ IBST_a062_MICB6TransferError m1: 5|1@1+ (1,0) [0|0] "" X
 SG_ IBST_a063_tempSens2ShortToSupply m1: 6|1@1+ (1,0) [0|0] "" X
 SG_ IBST_a064_tempSens1ShortToGround m1: 7|1@1+ (1,0) [0|0] "" X
 SG_ IBST_a065_tempSens2ShortToGround m1: 8|1@1+ (1,0) [0|0] "" X
 SG_ IBST_a066_tempSens1ShortToSupply m1: 9|1@1+ (1,0) [0|0] "" X
 SG_ IBST_a067_tempSensImplausVoltage m1: 10|1@1+ (1,0) [0|0] "" X
 SG_ IBST_a068_chargePumpUndervoltage m1: 11|1@1+ (1,0) [0|0] "" X
 SG_ IBST_a069_greasingRoutineFault m1: 12|1@1+ (1,0) [0|0] "" X
 SG_ IBST_a070_notShutDownNvMWrite m1: 13|1@1+ (1,0) [0|0] "" X
 SG_ IBST_a071_notShutDownNvMRead m1: 14|1@1+ (1,0) [0|0] "" X
 SG_ IBST_a072_notShutDownRight m1: 15|1@1+ (1,0) [0|0] "" X
 SG_ IBST_a073_jumpInAdjustNvMRead m1: 16|1@1+ (1,0) [0|0] "" X
 SG_ IBST_a074_FindIdleDataNvMWrite m1: 17|1@1+ (1,0) [0|0] "" X
 SG_ IBST_a075_FindIdleRoutineFault m1: 18|1@1+ (1,0) [0|0] "" X
 SG_ IBST_a076_masterCylLengthRead m1: 19|1@1+ (1,0) [0|0] "" X
 SG_ IBST_a077_runOutMotorSaturated m1: 20|1@1+ (1,0) [0|0] "" X
 SG_ IBST_a078_wearOffsetCompNVMRead m1: 21|1@1+ (1,0) [0|0] "" X
 SG_ IBST_a079_motorTempHighLevel1 m1: 22|1@1+ (1,0) [0|0] "" X
 SG_ IBST_a080_motorTempHighLevel2 m1: 23|1@1+ (1,0) [0|0] "" X
 SG_ IBST_a081_travelDeviation m1: 24|1@1+ (1,0) [0|0] "" X
 SG_ IBST_a082_motorSpeedDeviation m1: 25|1@1+ (1,0) [0|0] "" X
 SG_ IBST_a083_spindlePositionTooHigh m1: 26|1@1+ (1,0) [0|0] "" X
 SG_ IBST_a084_CANTransceiverHWFault m1: 27|1@1+ (1,0) [0|0] "" X
 SG_ IBST_a085_supplyUndervoltageLvl3 m1: 28|1@1+ (1,0) [0|0] "" X
 SG_ IBST_a086_supplyOvervoltageLvl3 m1: 29|1@1+ (1,0) [0|0] "" X
 SG_ IBST_a087_rotorSinOutOfRangeLow m1: 30|1@1+ (1,0) [0|0] "" X
 SG_ IBST_a088_rotorCosOutOfRangeLow m1: 31|1@1+ (1,0) [0|0] "" X
 SG_ IBST_a089_rotorSinOutOfRangeHigh m1: 32|1@1+ (1,0) [0|0] "" X
 SG_ IBST_a090_rotorCosOutOfRangeHigh m1: 33|1@1+ (1,0) [0|0] "" X
 SG_ IBST_a091_SMMOneRequestsInit m1: 34|1@1+ (1,0) [0|0] "" X
 SG_ IBST_a092_systemStartTimeOut m1: 35|1@1+ (1,0) [0|0] "" X
 SG_ IBST_a093_UEXSOvertemperature m1: 36|1@1+ (1,0) [0|0] "" X
 SG_ IBST_a094_XPASSEchoTimeDeviation m1: 37|1@1+ (1,0) [0|0] "" X
 SG_ IBST_a095_XPASSTimeOut m1: 38|1@1+ (1,0) [0|0] "" X
 SG_ IBST_a096_bridgeDriverMonError m1: 39|1@1+ (1,0) [0|0] "" X
 SG_ IBST_a097_bridgeDriverError m1: 40|1@1+ (1,0) [0|0] "" X
 SG_ IBST_a098_bridgeShortedPhase m1: 41|1@1+ (1,0) [0|0] "" X
 SG_ IBST_a099_bridgeSwitchInitError m1: 42|1@1+ (1,0) [0|0] "" X
 SG_ IBST_a100_current2OffsVEHigh m1: 43|1@1+ (1,0) [0|0] "" X
 SG_ IBST_a101_current2OffsetLow m1: 44|1@1+ (1,0) [0|0] "" X
 SG_ IBST_a102_current1OffsVEHigh m1: 45|1@1+ (1,0) [0|0] "" X
 SG_ IBST_a103_current1OffsetLow m1: 46|1@1+ (1,0) [0|0] "" X
 SG_ IBST_a104_bridgeDriverShort m1: 47|1@1+ (1,0) [0|0] "" X
 SG_ IBST_a105_LiPSUndervoltage m1: 48|1@1+ (1,0) [0|0] "" X
 SG_ IBST_a106_LiPS5VSupply m1: 49|1@1+ (1,0) [0|0] "" X
 SG_ IBST_a107_LiPS2PwmLineHigh m1: 50|1@1+ (1,0) [0|0] "" X
 SG_ IBST_a108_LiPS2PwmLineLow m1: 51|1@1+ (1,0) [0|0] "" X
 SG_ IBST_a109_LiPS2PwmTransmission m1: 52|1@1+ (1,0) [0|0] "" X
 SG_ IBST_a110_LiPS1SentLineHigh m1: 53|1@1+ (1,0) [0|0] "" X
 SG_ IBST_a111_LiPS1SentLineLow m1: 54|1@1+ (1,0) [0|0] "" X
 SG_ IBST_a112_LiPS1SentTransmission m1: 55|1@1+ (1,0) [0|0] "" X
 SG_ IBST_a113_LiPS1SentSensor m1: 56|1@1+ (1,0) [0|0] "" X
 SG_ IBST_a114_partyBusOff m1: 57|1@1+ (1,0) [0|0] "" X
 SG_ IBST_a115_CHOff m1: 58|1@1+ (1,0) [0|0] "" X
 SG_ IBST_a116_supplyUndervoltageLvl2 m1: 59|1@1+ (1,0) [0|0] "" X
 SG_ IBST_a117_supplyOvervoltageLvl2 m1: 60|1@1+ (1,0) [0|0] "" X
 SG_ IBST_a118_RPSNvMReadFault m1: 61|1@1+ (1,0) [0|0] "" X
 SG_ IBST_a119_RPSWrongCalibData m1: 62|1@1+ (1,0) [0|0] "" X
 SG_ IBST_a120_RPSVectorRangeHigh m1: 63|1@1+ (1,0) [0|0] "" X
 SG_ IBST_a121_RPSVectorRangeLow m2: 4|1@1+ (1,0) [0|0] "" X
 SG_ IBST_a122_RPSVectorOscillating m2: 5|1@1+ (1,0) [0|0] "" X
 SG_ IBST_a123_bridgeDriverUnavail m2: 6|1@1+ (1,0) [0|0] "" X
 SG_ IBST_a124_OBDCurrent1OORHigh m2: 7|1@1+ (1,0) [0|0] "" X
 SG_ IBST_a125_OBDCurrent2OORHigh m2: 8|1@1+ (1,0) [0|0] "" X
 SG_ IBST_a126_OBDCurrent1OORLow m2: 9|1@1+ (1,0) [0|0] "" X
 SG_ IBST_a127_OBDCurrent2OORLow m2: 10|1@1+ (1,0) [0|0] "" X
 SG_ IBST_a128_BLMMuxerTimeoutError m2: 11|1@1+ (1,0) [0|0] "" X
 SG_ IBST_a129_loadDumpOnFSLTest m2: 12|1@1+ (1,0) [0|0] "" X
 SG_ IBST_a130_DTSFunctionalRangeLow m2: 13|1@1+ (1,0) [0|0] "" X
 SG_ IBST_a131_DTSFunctionalRangeHigh m2: 14|1@1+ (1,0) [0|0] "" X
 SG_ IBST_a132_DTSPlausiCheck1vs2 m2: 15|1@1+ (1,0) [0|0] "" X
 SG_ IBST_a133_DTSOffsetTooLow m2: 16|1@1+ (1,0) [0|0] "" X
 SG_ IBST_a134_DTSOffsetTooHigh m2: 17|1@1+ (1,0) [0|0] "" X
 SG_ IBST_a135_ESPparty1DLC m2: 18|1@1+ (1,0) [0|0] "" X
 SG_ IBST_a136_ESPparty1Timeout m2: 19|1@1+ (1,0) [0|0] "" X
 SG_ IBST_a137_ESPparty1Checksum m2: 20|1@1+ (1,0) [0|0] "" X
 SG_ IBST_a138_ESPparty1Counter m2: 21|1@1+ (1,0) [0|0] "" X
 SG_ IBST_a139_ESPparty2DLC m2: 22|1@1+ (1,0) [0|0] "" X
 SG_ IBST_a140_ESPparty2Timeout m2: 23|1@1+ (1,0) [0|0] "" X
 SG_ IBST_a141_ESPparty2Checksum m2: 24|1@1+ (1,0) [0|0] "" X
 SG_ IBST_a142_ESPparty2Counter m2: 25|1@1+ (1,0) [0|0] "" X
 SG_ IBST_a143_ESPparty3DLC m2: 26|1@1+ (1,0) [0|0] "" X
 SG_ IBST_a144_ESPparty3Timeout m2: 27|1@1+ (1,0) [0|0] "" X
 SG_ IBST_a145_ESPparty3Checksum m2: 28|1@1+ (1,0) [0|0] "" X
 SG_ IBST_a146_ESPparty3Counter m2: 29|1@1+ (1,0) [0|0] "" X
 SG_ IBST_a147_PSCMotorSizeReadFault m2: 30|1@1+ (1,0) [0|0] "" X
 SG_ IBST_a148_MLIGainMechReadFault m2: 31|1@1+ (1,0) [0|0] "" X
 SG_ IBST_a149_MLITMCAreaReadFault m2: 32|1@1+ (1,0) [0|0] "" X
 SG_ IBST_a150_motorTestFault m2: 33|1@1+ (1,0) [0|0] "" X
 SG_ IBST_a151_PSCGearRatioReadFault m2: 34|1@1+ (1,0) [0|0] "" X
 SG_ IBST_a152_PSCVoltageImplausible m2: 35|1@1+ (1,0) [0|0] "" X
 SG_ IBST_a153_PSCImpedanceTooHigh m2: 36|1@1+ (1,0) [0|0] "" X
 SG_ IBST_a154_PSCImpedanceTooLow m2: 37|1@1+ (1,0) [0|0] "" X
 SG_ IBST_a155_supplyUndervoltageLvl1 m2: 38|1@1+ (1,0) [0|0] "" X
 SG_ IBST_a156_supplyOvervoltageLvl1 m2: 39|1@1+ (1,0) [0|0] "" X
 SG_ IBST_a157_masterCylPressInvalid m2: 40|1@1+ (1,0) [0|0] "" X
 SG_ IBST_a158_DTSOffsHighSuspicious m2: 41|1@1+ (1,0) [0|0] "" X
 SG_ IBST_a159_FindIdleNvMReadError m2: 42|1@1+ (1,0) [0|0] "" X
 SG_ IBST_a160_DTSIDTimeOut m2: 43|1@1+ (1,0) [0|0] "" X
 SG_ IBST_a161_powerPackMismatch m2: 44|1@1+ (1,0) [0|0] "" X
 SG_ IBST_a162_idlePosNotDetected m2: 45|1@1+ (1,0) [0|0] "" X
 SG_ IBST_a163_ESPpEstMaxInvalid m2: 46|1@1+ (1,0) [0|0] "" X
 SG_ IBST_a164_ESPVehicleSpeedInvalid m2: 47|1@1+ (1,0) [0|0] "" X
 SG_ IBST_a165_ESPpForceBlendInvalid m2: 48|1@1+ (1,0) [0|0] "" X
 SG_ IBST_a166_ESPpMcVirtualInvalid m2: 49|1@1+ (1,0) [0|0] "" X
 SG_ IBST_a167_ESPqTargetExterInvalid m2: 50|1@1+ (1,0) [0|0] "" X
 SG_ IBST_a168_CANOvervoltage m2: 51|1@1+ (1,0) [0|0] "" X
 SG_ IBST_a169_CANUndervoltage m2: 52|1@1+ (1,0) [0|0] "" X
 SG_ IBST_a170_LVPowerStateTimeout m2: 53|1@1+ (1,0) [0|0] "" X
 SG_ IBST_a171_LVPowerStateChecksum m2: 54|1@1+ (1,0) [0|0] "" X
 SG_ IBST_a172_LVPowerStateDLC m2: 55|1@1+ (1,0) [0|0] "" X
 SG_ IBST_a173_LVPowerStateCounter m2: 56|1@1+ (1,0) [0|0] "" X
 SG_ IBST_a174_LVOffStateInvalid m2: 57|1@1+ (1,0) [0|0] "" X
 SG_ IBST_a175_LVGoingDownInvalid m2: 58|1@1+ (1,0) [0|0] "" X

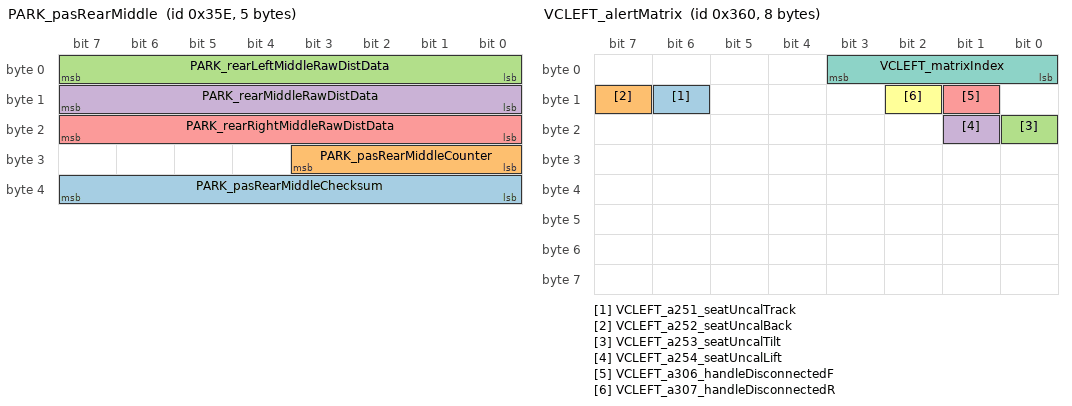
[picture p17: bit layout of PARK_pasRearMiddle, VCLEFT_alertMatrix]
BO_ 862 PARK_pasRearMiddle: 5 CH
 SG_ PARK_pasRearMiddleChecksum: 32|8@1+ (1,0) [0|0] "" X
 SG_ PARK_pasRearMiddleCounter: 24|4@1+ (1,0) [0|0] "" X
 SG_ PARK_rearLeftMiddleRawDistData: 0|8@1+ (1,0) [0|0] "cm" X
 SG_ PARK_rearMiddleRawDistData: 8|8@1+ (1,0) [0|0] "cm" X
 SG_ PARK_rearRightMiddleRawDistData: 16|8@1+ (1,0) [0|0] "cm" X

BO_ 864 VCLEFT_alertMatrix: 8 GTW
 SG_ VCLEFT_a251_seatUncalTrack : 14|1@1+ (1,0) [0|1] "" ODIN,UI
 SG_ VCLEFT_a252_seatUncalBack : 15|1@1+ (1,0) [0|1] "" ODIN,UI
 SG_ VCLEFT_a253_seatUncalTilt : 16|1@1+ (1,0) [0|1] "" ODIN,UI
 SG_ VCLEFT_a254_seatUncalLift : 17|1@1+ (1,0) [0|1] "" ODIN,UI
 SG_ VCLEFT_a306_handleDisconnectedF : 9|1@1+ (1,0) [0|1] "" ODIN,UI
 SG_ VCLEFT_a307_handleDisconnectedR : 10|1@1+ (1,0) [0|1] "" ODIN,UI
 SG_ VCLEFT_matrixIndex : 0|4@1+ (1,0) [0|15] "" UI

BO_ 867 CMP_info: 8 VEH
 SG_ CMP_infoIndex M: 0|8@1+ (1,0) [0|0] "" X
 SG_ CMP_infoBuildType m10: 8|8@1+ (1,0) [0|0] "" X
 SG_ CMP_infoBuildConfigId m10: 16|16@1+ (1,0) [0|0] "" X
 SG_ CMP_infoHardwareId m10: 32|16@1+ (1,0) [0|0] "" X
 SG_ CMP_infoComponentId m10: 48|16@1+ (1,0) [0|0] "" X
 SG_ CMP_infoPcbaId m11: 16|8@1+ (1,0) [0|0] "" X
 SG_ CMP_infoAssemblyId m11: 24|8@1+ (1,0) [0|0] "" X
 SG_ CMP_infoUsageId m11: 32|16@1+ (1,0) [0|0] "" X
 SG_ CMP_infoSubUsageId m11: 48|16@1+ (1,0) [0|0] "" X
 SG_ CMP_infoBootUdsProtoVersion m20: 8|8@1+ (1,0) [0|0] "" X
 SG_ CMP_infoBootCrc m20: 32|32@1+ (1,0) [0|0] "" X
 SG_ CMP_infoPlatformType m13: 8|8@1+ (1,0) [0|0] "" X
 SG_ CMP_infoAppCrc m13: 32|32@1+ (1,0) [0|0] "" X

BO_ 869 SCS_alertMatrix1: 8 VEH
 SG_ SCS_a001_hwDSPfault: 0|1@1+ (1,0) [0|0] "" X
 SG_ SCS_a002_hwIbatOC: 1|1@1+ (1,0) [0|0] "" X
 SG_ SCS_a003_hwCordOT: 2|1@1+ (1,0) [0|0] "" X
 SG_ SCS_a004_hwVbusOV: 3|1@1+ (1,0) [0|0] "" X
 SG_ SCS_a005_hwHVIL: 4|1@1+ (1,0) [0|0] "" X
 SG_ SCS_a006_hwWeld_V1: 5|1@1+ (1,0) [0|0] "" X
 SG_ SCS_a007_hwWeld_V2: 6|1@1+ (1,0) [0|0] "" X
 SG_ SCS_a008_hwOpen_V1: 7|1@1+ (1,0) [0|0] "" X
 SG_ SCS_a009_hwOpen_V2: 8|1@1+ (1,0) [0|0] "" X
 SG_ SCS_a010_hwIllegalCntrCmdV1: 9|1@1+ (1,0) [0|0] "" X
 SG_ SCS_a011_hwIllegalCntrCmdInt: 10|1@1+ (1,0) [0|0] "" X
 SG_ SCS_a012_hwIllegalCntrCmdV2: 11|1@1+ (1,0) [0|0] "" X
 SG_ SCS_a013_cordTempHiFoldBk: 12|1@1+ (1,0) [0|0] "" X
 SG_ SCS_a014_coolantTempHiFoldBk: 13|1@1+ (1,0) [0|0] "" X
 SG_ SCS_a015_unusedHW15: 14|1@1+ (1,0) [0|0] "" X
 SG_ SCS_a016_unusedHW16: 15|1@1+ (1,0) [0|0] "" X
 SG_ SCS_a017_unusedHW17: 16|1@1+ (1,0) [0|0] "" X
 SG_ SCS_a018_unusedHW18: 17|1@1+ (1,0) [0|0] "" X
 SG_ SCS_a019_unusedHW19: 18|1@1+ (1,0) [0|0] "" X
 SG_ SCS_a020_unusedHW20: 19|1@1+ (1,0) [0|0] "" X
 SG_ SCS_a021_unusedHW21: 20|1@1+ (1,0) [0|0] "" X
 SG_ SCS_a022_fastChargeLimitActiveV1: 21|1@1+ (1,0) [0|0] "" X
 SG_ SCS_a023_fastChargeLimitActiveV2: 22|1@1+ (1,0) [0|0] "" X
 SG_ SCS_a024_emergencyShutdown: 23|1@1+ (1,0) [0|0] "" X
 SG_ SCS_a025_internalIsolationFault: 24|1@1+ (1,0) [0|0] "" X
 SG_ SCS_a026_internalIsolationLow: 25|1@1+ (1,0) [0|0] "" X
 SG_ SCS_a027_externalIsolationLow: 26|1@1+ (1,0) [0|0] "" X
 SG_ SCS_a028_isolationRationality: 27|1@1+ (1,0) [0|0] "" X
 SG_ SCS_a029_VbatOV: 28|1@1+ (1,0) [0|0] "" X
 SG_ SCS_a030_VbusOV: 29|1@1+ (1,0) [0|0] "" X
 SG_ SCS_a031_IbatOC: 30|1@1+ (1,0) [0|0] "" X
 SG_ SCS_a032_VBatRationality: 31|1@1+ (1,0) [0|0] "" X
 SG_ SCS_a033_VBusRationality: 32|1@1+ (1,0) [0|0] "" X
 SG_ SCS_a034_IBatRationality: 33|1@1+ (1,0) [0|0] "" X
 SG_ SCS_a035_unexpectedVbusBehavior: 34|1@1+ (1,0) [0|0] "" X
 SG_ SCS_a036_internalContactorWelded: 35|1@1+ (1,0) [0|0] "" X
 SG_ SCS_a037_outputContactorWelded: 36|1@1+ (1,0) [0|0] "" X
 SG_ SCS_a038_contactorFailedOpen: 37|1@1+ (1,0) [0|0] "" X
 SG_ SCS_a039_ibatRegulation: 38|1@1+ (1,0) [0|0] "" X
 SG_ SCS_a040_plus12VOutOfRange: 39|1@1+ (1,0) [0|0] "" X
 SG_ SCS_a041_minus12VOutOfRange: 40|1@1+ (1,0) [0|0] "" X
 SG_ SCS_a042_pilotOutOfRange: 41|1@1+ (1,0) [0|0] "" X
 SG_ SCS_a043_pilotRationality: 42|1@1+ (1,0) [0|0] "" X
 SG_ SCS_a044_proximityRationality: 43|1@1+ (1,0) [0|0] "" X
 SG_ SCS_a045_pcbaOT: 44|1@1+ (1,0) [0|0] "" X
 SG_ SCS_a046_coolantOT: 45|1@1+ (1,0) [0|0] "" X
 SG_ SCS_a047_cordOT: 46|1@1+ (1,0) [0|0] "" X
 SG_ SCS_a048_ambientOT: 47|1@1+ (1,0) [0|0] "" X
 SG_ SCS_a049_pcbaTempRationality: 48|1@1+ (1,0) [0|0] "" X
 SG_ SCS_a050_coolantTempRationality: 49|1@1+ (1,0) [0|0] "" X
 SG_ SCS_a051_cordTempRationality: 50|1@1+ (1,0) [0|0] "" X
 SG_ SCS_a052_ambientTempRationality: 51|1@1+ (1,0) [0|0] "" X
 SG_ SCS_a053_unexpectedThermalBehavi: 52|1@1+ (1,0) [0|0] "" X
 SG_ SCS_a054_pumpRegulation: 53|1@1+ (1,0) [0|0] "" X
 SG_ SCS_a055_coolantLevelLow: 54|1@1+ (1,0) [0|0] "" X
 SG_ SCS_a056_stateTransitionDenied: 55|1@1+ (1,0) [0|0] "" X
 SG_ SCS_a057_watchdogReset: 56|1@1+ (1,0) [0|0] "" X
 SG_ SCS_a058_adcRef: 57|1@1+ (1,0) [0|0] "" X
 SG_ SCS_a059_memoryError: 58|1@1+ (1,0) [0|0] "" X
 SG_ SCS_a060_swHVIL: 59|1@1+ (1,0) [0|0] "" X
 SG_ SCS_a061_postOutOfService: 60|1@1+ (1,0) [0|0] "" X
 SG_ SCS_a062_unused: 61|1@1+ (1,0) [0|0] "" X
 SG_ SCS_a063_canRationality: 62|1@1+ (1,0) [0|0] "" X
 SG_ SCS_a064_vehicleCommandTimeout: 63|1@1+ (1,0) [0|0] "" X

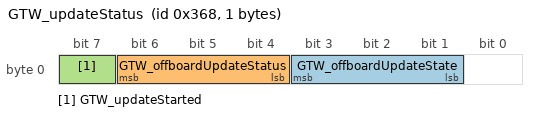
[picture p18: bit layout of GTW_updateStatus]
BO_ 872 GTW_updateStatus: 1 VEH
 SG_ GTW_offboardUpdateState: 1|3@1+ (1,0) [0|0] "" X
 SG_ GTW_offboardUpdateStatus: 4|3@1+ (1,0) [0|0] "" X
 SG_ GTW_updateStarted: 7|1@1+ (1,0) [0|0] "" X

BO_ 873 APP_warningMatrix1: 8 CH
 SG_ APP_w065_deserializerOvercurrent: 0|1@1+ (1,0) [0|0] "" X
 SG_ APP_w066_deserializerLockLost: 1|1@1+ (1,0) [0|0] "" X
 SG_ APP_w067_steeringAlignment: 2|1@1+ (1,0) [0|0] "" X
 SG_ APP_w068_vlInconsistency: 3|1@1+ (1,0) [0|0] "" X
 SG_ APP_w069_apcSpaceMasked: 4|1@1+ (1,0) [0|0] "" X
 SG_ APP_w070_apcIncompleteCal: 5|1@1+ (1,0) [0|0] "" X
 SG_ APP_w071_selfparkStarted: 6|1@1+ (1,0) [0|0] "" X
 SG_ APP_w072_selfparkComplete: 7|1@1+ (1,0) [0|0] "" X
 SG_ APP_w073_issueEscalatedLDW: 8|1@1+ (1,0) [0|0] "" X
 SG_ APP_w074_inPathStationaryObst: 9|1@1+ (1,0) [0|0] "" X
 SG_ APP_w075_scMia: 10|1@1+ (1,0) [0|0] "" X
 SG_ APP_w076_mobilEyeSetC: 11|1@1+ (1,0) [0|0] "" X
 SG_ APP_w077_pmmActive: 12|1@1+ (1,0) [0|0] "" X
 SG_ APP_w078_pmmActive2: 13|1@1+ (1,0) [0|0] "" X
 SG_ APP_w079_edrAvailable: 14|1@1+ (1,0) [0|0] "" X
 SG_ APP_w080_accFailedActivation: 15|1@1+ (1,0) [0|0] "" X
 SG_ APP_w081_pmmActiveBraking: 16|1@1+ (1,0) [0|0] "" X
 SG_ APP_w082_inPathFSviolation: 17|1@1+ (1,0) [0|0] "" X
 SG_ APP_w083_inPathRADObject: 18|1@1+ (1,0) [0|0] "" X
 SG_ APP_w084_pmmIPSO: 19|1@1+ (1,0) [0|0] "" X
 SG_ APP_w085_pmmSteering: 20|1@1+ (1,0) [0|0] "" X
 SG_ APP_w086_robCollision: 21|1@1+ (1,0) [0|0] "" X
 SG_ APP_w087_DEPRECATED: 22|1@1+ (1,0) [0|0] "" X
 SG_ APP_w088_DEPRECATED: 23|1@1+ (1,0) [0|0] "" X
 SG_ APP_w089_DEPRECATED: 24|1@1+ (1,0) [0|0] "" X
 SG_ APP_w090_DEPRECATED: 25|1@1+ (1,0) [0|0] "" X
 SG_ APP_w091_DEPRECATED: 26|1@1+ (1,0) [0|0] "" X
 SG_ APP_w092_DEPRECATED: 27|1@1+ (1,0) [0|0] "" X
 SG_ APP_w093_DEPRECATED: 28|1@1+ (1,0) [0|0] "" X
 SG_ APP_w094_DEPRECATED: 29|1@1+ (1,0) [0|0] "" X
 SG_ APP_w095_DEPRECATED: 30|1@1+ (1,0) [0|0] "" X
 SG_ APP_w096_DEPRECATED: 31|1@1+ (1,0) [0|0] "" X
 SG_ APP_w097_DEPRECATED: 32|1@1+ (1,0) [0|0] "" X
 SG_ APP_w098_DEPRECATED: 33|1@1+ (1,0) [0|0] "" X
 SG_ APP_w099_DEPRECATED: 34|1@1+ (1,0) [0|0] "" X
 SG_ APP_w100_DEPRECATED: 35|1@1+ (1,0) [0|0] "" X
 SG_ APP_w101_DEPRECATED: 36|1@1+ (1,0) [0|0] "" X
 SG_ APP_w102_DEPRECATED: 37|1@1+ (1,0) [0|0] "" X
 SG_ APP_w103_robExperimentalAEB: 38|1@1+ (1,0) [0|0] "" X
 SG_ APP_w104_DEPRECATED: 39|1@1+ (1,0) [0|0] "" X
 SG_ APP_w105_DEPRECATED: 40|1@1+ (1,0) [0|0] "" X
 SG_ APP_w106_torsionBarOffset: 41|1@1+ (1,0) [0|0] "" X

BO_ 874 DAS_warningMatrix1: 8 VEH
 SG_ DAS_w065_deserializerOvercurrent: 0|1@1+ (1,0) [0|0] "" X
 SG_ DAS_w066_deserializerLockLost: 1|1@1+ (1,0) [0|0] "" X
 SG_ DAS_w067_steeringAlignment: 2|1@1+ (1,0) [0|0] "" X
 SG_ DAS_w068_vlInconsistency: 3|1@1+ (1,0) [0|0] "" X
 SG_ DAS_w069_apcSpaceMasked: 4|1@1+ (1,0) [0|0] "" X
 SG_ DAS_w070_apcIncompleteCal: 5|1@1+ (1,0) [0|0] "" X
 SG_ DAS_w071_selfparkStarted: 6|1@1+ (1,0) [0|0] "" X
 SG_ DAS_w072_selfparkComplete: 7|1@1+ (1,0) [0|0] "" X
 SG_ DAS_w073_issueEscalatedLDW: 8|1@1+ (1,0) [0|0] "" X
 SG_ DAS_w074_inPathStationaryObst: 9|1@1+ (1,0) [0|0] "" X
 SG_ DAS_w075_scMia: 10|1@1+ (1,0) [0|0] "" X
 SG_ DAS_w076_mobilEyeSetC: 11|1@1+ (1,0) [0|0] "" X
 SG_ DAS_w077_pmmActive: 12|1@1+ (1,0) [0|0] "" X
 SG_ DAS_w078_pmmActive2: 13|1@1+ (1,0) [0|0] "" X
 SG_ DAS_w079_edrAvailable: 14|1@1+ (1,0) [0|0] "" X
 SG_ DAS_w080_accFailedActivation: 15|1@1+ (1,0) [0|0] "" X
 SG_ DAS_w081_pmmActiveBraking: 16|1@1+ (1,0) [0|0] "" X
 SG_ DAS_w082_inPathFSviolation: 17|1@1+ (1,0) [0|0] "" X
 SG_ DAS_w083_inPathRADObject: 18|1@1+ (1,0) [0|0] "" X
 SG_ DAS_w084_pmmIPSO: 19|1@1+ (1,0) [0|0] "" X
 SG_ DAS_w085_pmmSteering: 20|1@1+ (1,0) [0|0] "" X
 SG_ DAS_w086_robCollision: 21|1@1+ (1,0) [0|0] "" X
 SG_ DAS_w087_DEPRECATED: 22|1@1+ (1,0) [0|0] "" X
 SG_ DAS_w088_DEPRECATED: 23|1@1+ (1,0) [0|0] "" X
 SG_ DAS_w089_DEPRECATED: 24|1@1+ (1,0) [0|0] "" X
 SG_ DAS_w090_DEPRECATED: 25|1@1+ (1,0) [0|0] "" X
 SG_ DAS_w091_DEPRECATED: 26|1@1+ (1,0) [0|0] "" X
 SG_ DAS_w092_DEPRECATED: 27|1@1+ (1,0) [0|0] "" X
 SG_ DAS_w093_DEPRECATED: 28|1@1+ (1,0) [0|0] "" X
 SG_ DAS_w094_DEPRECATED: 29|1@1+ (1,0) [0|0] "" X
 SG_ DAS_w095_DEPRECATED: 30|1@1+ (1,0) [0|0] "" X
 SG_ DAS_w096_DEPRECATED: 31|1@1+ (1,0) [0|0] "" X
 SG_ DAS_w097_DEPRECATED: 32|1@1+ (1,0) [0|0] "" X
 SG_ DAS_w098_DEPRECATED: 33|1@1+ (1,0) [0|0] "" X
 SG_ DAS_w099_DEPRECATED: 34|1@1+ (1,0) [0|0] "" X
 SG_ DAS_w100_DEPRECATED: 35|1@1+ (1,0) [0|0] "" X
 SG_ DAS_w101_DEPRECATED: 36|1@1+ (1,0) [0|0] "" X
 SG_ DAS_w102_DEPRECATED: 37|1@1+ (1,0) [0|0] "" X
 SG_ DAS_w103_robExperimentalAEB: 38|1@1+ (1,0) [0|0] "" X
 SG_ DAS_w104_DEPRECATED: 39|1@1+ (1,0) [0|0] "" X
 SG_ DAS_w105_DEPRECATED: 40|1@1+ (1,0) [0|0] "" X
 SG_ DAS_w106_torsionBarCalibrated: 41|1@1+ (1,0) [0|0] "" X

BO_ 876 APS_warningMatrix1: 8 CH
 SG_ APS_w065_deserializerOvercurrent: 0|1@1+ (1,0) [0|0] "" X
 SG_ APS_w066_deserializerLockLost: 1|1@1+ (1,0) [0|0] "" X
 SG_ APS_w067_steeringAlignment: 2|1@1+ (1,0) [0|0] "" X
 SG_ APS_w068_vlInconsistency: 3|1@1+ (1,0) [0|0] "" X
 SG_ APS_w069_apcSpaceMasked: 4|1@1+ (1,0) [0|0] "" X
 SG_ APS_w070_apcIncompleteCal: 5|1@1+ (1,0) [0|0] "" X
 SG_ APS_w071_selfparkStarted: 6|1@1+ (1,0) [0|0] "" X
 SG_ APS_w072_selfparkComplete: 7|1@1+ (1,0) [0|0] "" X
 SG_ APS_w073_issueEscalatedLDW: 8|1@1+ (1,0) [0|0] "" X
 SG_ APS_w074_inPathStationaryObst: 9|1@1+ (1,0) [0|0] "" X
 SG_ APS_w075_scMia: 10|1@1+ (1,0) [0|0] "" X
 SG_ APS_w076_mobilEyeSetC: 11|1@1+ (1,0) [0|0] "" X
 SG_ APS_w077_pmmActive: 12|1@1+ (1,0) [0|0] "" X
 SG_ APS_w078_pmmActive2: 13|1@1+ (1,0) [0|0] "" X
 SG_ APS_w079_edrAvailable: 14|1@1+ (1,0) [0|0] "" X
 SG_ APS_w080_accFailedActivation: 15|1@1+ (1,0) [0|0] "" X
 SG_ APS_w081_pmmActiveBraking: 16|1@1+ (1,0) [0|0] "" X
 SG_ APS_w082_inPathFSviolation: 17|1@1+ (1,0) [0|0] "" X
 SG_ APS_w083_inPathRADObject: 18|1@1+ (1,0) [0|0] "" X
 SG_ APS_w084_pmmIPSO: 19|1@1+ (1,0) [0|0] "" X
 SG_ APS_w085_pmmSteering: 20|1@1+ (1,0) [0|0] "" X
 SG_ APS_w086_robCollision: 21|1@1+ (1,0) [0|0] "" X
 SG_ APS_w087_DEPRECATED: 22|1@1+ (1,0) [0|0] "" X
 SG_ APS_w088_DEPRECATED: 23|1@1+ (1,0) [0|0] "" X
 SG_ APS_w089_DEPRECATED: 24|1@1+ (1,0) [0|0] "" X
 SG_ APS_w090_DEPRECATED: 25|1@1+ (1,0) [0|0] "" X
 SG_ APS_w091_DEPRECATED: 26|1@1+ (1,0) [0|0] "" X
 SG_ APS_w092_DEPRECATED: 27|1@1+ (1,0) [0|0] "" X
 SG_ APS_w093_DEPRECATED: 28|1@1+ (1,0) [0|0] "" X
 SG_ APS_w094_DEPRECATED: 29|1@1+ (1,0) [0|0] "" X
 SG_ APS_w095_DEPRECATED: 30|1@1+ (1,0) [0|0] "" X
 SG_ APS_w096_DEPRECATED: 31|1@1+ (1,0) [0|0] "" X
 SG_ APS_w097_DEPRECATED: 32|1@1+ (1,0) [0|0] "" X
 SG_ APS_w098_DEPRECATED: 33|1@1+ (1,0) [0|0] "" X
 SG_ APS_w099_DEPRECATED: 34|1@1+ (1,0) [0|0] "" X
 SG_ APS_w100_DEPRECATED: 35|1@1+ (1,0) [0|0] "" X
 SG_ APS_w101_DEPRECATED: 36|1@1+ (1,0) [0|0] "" X
 SG_ APS_w102_DEPRECATED: 37|1@1+ (1,0) [0|0] "" X
 SG_ APS_w103_robExperimentalAEB: 38|1@1+ (1,0) [0|0] "" X
 SG_ APS_w104_DEPRECATED: 39|1@1+ (1,0) [0|0] "" X
 SG_ APS_w105_DEPRECATED: 40|1@1+ (1,0) [0|0] "" X
 SG_ APS_w106_torsionBarOffset: 41|1@1+ (1,0) [0|0] "" X

BO_ 877 TAS_warningMatrix2: 8 VEH
 SG_ TAS_w070_lowVoltage12V: 5|1@1+ (1,0) [0|0] "" X
 SG_ TAS_w071_highVoltage12V: 6|1@1+ (1,0) [0|0] "" X
 SG_ TAS_w072_shortCircuit5VS0: 7|1@1+ (1,0) [0|0] "" X
 SG_ TAS_w073_lowVoltage5VS0: 8|1@1+ (1,0) [0|0] "" X
 SG_ TAS_w074_shortCircuit5VS1: 9|1@1+ (1,0) [0|0] "" X
 SG_ TAS_w075_lowVoltage5VS1: 10|1@1+ (1,0) [0|0] "" X
 SG_ TAS_w076_highVoltage5VS1: 11|1@1+ (1,0) [0|0] "" X
 SG_ TAS_w077_pressureSigVTooLow: 12|1@1+ (1,0) [0|0] "" X
 SG_ TAS_w078_pressureSigVTooHigh: 13|1@1+ (1,0) [0|0] "" X
 SG_ TAS_w079_DvrSideCfgMismatch: 14|1@1+ (1,0) [0|0] "" X
 SG_ TAS_w080_pressureRefVTooLow: 15|1@1+ (1,0) [0|0] "" X
 SG_ TAS_w093_OTPError: 28|1@1+ (1,0) [0|0] "" X
 SG_ TAS_w098_VCFRONT_MIA: 33|1@1+ (1,0) [0|0] "" X
 SG_ TAS_w099_UI_MIA: 34|1@1+ (1,0) [0|0] "" X
 SG_ TAS_w100_RCM_MIA: 35|1@1+ (1,0) [0|0] "" X
 SG_ TAS_w101_ESP_MIA: 36|1@1+ (1,0) [0|0] "" X
 SG_ TAS_w102_DI_MIA: 37|1@1+ (1,0) [0|0] "" X
 SG_ TAS_w103_GTW_MIA: 38|1@1+ (1,0) [0|0] "" X
 SG_ TAS_w105_ECUDebugMode: 40|1@1+ (1,0) [0|0] "" X
 SG_ TAS_w106_HighCPULoad: 41|1@1+ (1,0) [0|0] "" X
 SG_ TAS_w107_HighStackUsage: 42|1@1+ (1,0) [0|0] "" X
 SG_ TAS_w121_maxDutyFL: 56|1@1+ (1,0) [0|0] "" X
 SG_ TAS_w122_maxDutyFR: 57|1@1+ (1,0) [0|0] "" X
 SG_ TAS_w123_maxDutyRL: 58|1@1+ (1,0) [0|0] "" X
 SG_ TAS_w124_maxDutyRR: 59|1@1+ (1,0) [0|0] "" X
 SG_ TAS_w125_maxDutyReservoir: 60|1@1+ (1,0) [0|0] "" X
 SG_ TAS_w126_maxDutyExhaust: 61|1@1+ (1,0) [0|0] "" X
 SG_ TAS_w127_maxDutyBoost: 62|1@1+ (1,0) [0|0] "" X
 SG_ TAS_w128_maxDutyCompressor: 63|1@1+ (1,0) [0|0] "" X

BO_ 879 TPMS_StatusC: 8 CH
 SG_ TPMS_WA_version: 3|1@1+ (1,0) [0|0] "" X
 SG_ TPMS_c_globalHardWarning: 0|1@1+ (1,0) [0|0] "" X
 SG_ TPMS_c_globalSoftWarning: 1|1@1+ (1,0) [0|0] "" X
 SG_ TPMS_deltaPressWarningFL: 20|1@1+ (1,0) [0|0] "" X
 SG_ TPMS_deltaPressWarningFR: 21|1@1+ (1,0) [0|0] "" X
 SG_ TPMS_deltaPressWarningRL: 22|1@1+ (1,0) [0|0] "" X
 SG_ TPMS_deltaPressWarningRR: 23|1@1+ (1,0) [0|0] "" X
 SG_ TPMS_ecuOverVoltage: 41|1@1+ (1,0) [0|0] "" X
 SG_ TPMS_ecuRamRomNvMFail: 42|1@1+ (1,0) [0|0] "" X
 SG_ TPMS_ecuUnderVoltage: 40|1@1+ (1,0) [0|0] "" X
 SG_ TPMS_eolNotCompleted: 47|1@1+ (1,0) [0|0] "" X
 SG_ TPMS_externalTemperatureFail: 46|1@1+ (1,0) [0|0] "" X
 SG_ TPMS_globalDeltaPressure: 4|1@1+ (1,0) [0|0] "" X
 SG_ TPMS_hardWarningFL: 15|1@1+ (1,0) [0|0] "" X
 SG_ TPMS_hardWarningFR: 13|1@1+ (1,0) [0|0] "" X
 SG_ TPMS_hardWarningRL: 11|1@1+ (1,0) [0|0] "" X
 SG_ TPMS_hardWarningRR: 9|1@1+ (1,0) [0|0] "" X
 SG_ TPMS_learningStatus: 16|2@1+ (1,0) [0|0] "" X
 SG_ TPMS_localisationStatus: 18|2@1+ (1,0) [0|0] "" X
 SG_ TPMS_newSensorLearnt: 5|3@1+ (1,0) [0|0] "" X
 SG_ TPMS_rcpFront: 48|8@1+ (0.025,0) [0|0] "bar" X
 SG_ TPMS_rcpRear: 56|8@1+ (0.025,0) [0|0] "bar" X
 SG_ TPMS_rfReceiverFail: 43|1@1+ (1,0) [0|0] "" X
 SG_ TPMS_sensorBatteryLowFL: 32|1@1+ (1,0) [0|0] "" X
 SG_ TPMS_sensorBatteryLowFR: 33|1@1+ (1,0) [0|0] "" X
 SG_ TPMS_sensorBatteryLowRL: 34|1@1+ (1,0) [0|0] "" X
 SG_ TPMS_sensorBatteryLowRR: 35|1@1+ (1,0) [0|0] "" X
 SG_ TPMS_sensorDefectiveFL: 36|1@1+ (1,0) [0|0] "" X
 SG_ TPMS_sensorDefectiveFR: 37|1@1+ (1,0) [0|0] "" X
 SG_ TPMS_sensorDefectiveRL: 38|1@1+ (1,0) [0|0] "" X
 SG_ TPMS_sensorDefectiveRR: 39|1@1+ (1,0) [0|0] "" X
 SG_ TPMS_sensorNoResponseFL: 24|1@1+ (1,0) [0|0] "" X
 SG_ TPMS_sensorNoResponseFR: 25|1@1+ (1,0) [0|0] "" X
 SG_ TPMS_sensorNoResponseRL: 26|1@1+ (1,0) [0|0] "" X
 SG_ TPMS_sensorNoResponseRR: 27|1@1+ (1,0) [0|0] "" X
 SG_ TPMS_sensorThermShutdownFL: 28|1@1+ (1,0) [0|0] "" X
 SG_ TPMS_sensorThermShutdownFR: 29|1@1+ (1,0) [0|0] "" X
 SG_ TPMS_sensorThermShutdownRL: 30|1@1+ (1,0) [0|0] "" X
 SG_ TPMS_sensorThermShutdownRR: 31|1@1+ (1,0) [0|0] "" X
 SG_ TPMS_softWarningFL: 14|1@1+ (1,0) [0|0] "" X
 SG_ TPMS_softWarningFR: 12|1@1+ (1,0) [0|0] "" X
 SG_ TPMS_softWarningRL: 10|1@1+ (1,0) [0|0] "" X
 SG_ TPMS_softWarningRR: 8|1@1+ (1,0) [0|0] "" X
 SG_ TPMS_systemMalfunction: 2|1@1+ (1,0) [0|0] "" X
 SG_ TPMS_vehicleSpeedFail: 45|1@1+ (1,0) [0|0] "" X
 SG_ TPMS_wheelPulseMissing: 44|1@1+ (1,0) [0|0] "" X

VAL_ 694 DI_ptcStateUI 0 "FAULTED" 1 "BACKUP" 2 "ON" 3 "SNA" ;
VAL_ 694 DI_tractionControlModeUI 0 "NORMAL" 1 "SLIP_START" 2 "DEV_MODE_1" 3 "DEV_MODE_2" 4 "ROLLS_MODE" 5 "DYNO_MODE" 6 "OFFROAD_ASSIST" ;
VAL_ 697 DAS_accState 1 "ACC_CANCEL_CAMERA_BLIND" 0 "ACC_CANCEL_GENERIC" 13 "ACC_CANCEL_GENERIC_SILENT" 14 "ACC_CANCEL_OUT_OF_CALIBRATION" 12 "ACC_CANCEL_PATH_NOT_CLEAR" 2 "ACC_CANCEL_RADAR_BLIND" 3 "ACC_HOLD" 4 "ACC_ON" 8 "APC_ABORT" 5 "APC_BACKWARD" 7 "APC_COMPLETE" 6 "APC_FORWARD" 9 "APC_PAUSE" 11 "APC_SELFPARK_START" 10 "APC_UNPARK_COMPLETE" 15 "FAULT_SNA" ;
VAL_ 697 DAS_accelMax 511 "SNA" ;
VAL_ 697 DAS_accelMin 511 "SNA" ;
VAL_ 697 DAS_aebEvent 1 "AEB_ACTIVE" 2 "AEB_FAULT" 0 "AEB_NOT_ACTIVE" 3 "AEB_SNA" ;
VAL_ 697 DAS_jerkMax 255 "SNA" ;
VAL_ 697 DAS_jerkMin 511 "SNA" ;
VAL_ 697 DAS_setSpeed 4095 "SNA" ;
VAL_ 698 UI_radarTargetDx 255 "NO_OBJECT";
VAL_ 698 UI_radarTargetDxEnd 255 "NO_OBJECT";
VAL_ 705 VCFRONT_logging10HzIndex 0 "COOLANT_PUMPS" 1 "THERMAL_FAN" 2 "FIVE_WAY_VALVE" 3 "REFRIGERANT_LV8907" 4 "COMPRESSOR" 5 "EXV_EVAP_SOLENOID_AIRFLOW" 6 "END";
VAL_ 705 VCFRONT_pumpBatteryRPMTarget 1023 "SNA";
VAL_ 705 VCFRONT_pumpPowertrainRPMTarget 1023 "SNA";
VAL_ 705 VCFRONT_radiatorFanRPMTarget 1023 "SNA";
VAL_ 705 VCFRONT_coolantTempBasedMode 0 "SERIES" 1 "PARALLEL";
VAL_ 705 VCFRONT_tempDischargeSimulated 2047 "SNA";
VAL_ 705 VCFRONT_exvMotorState 0 "UNPOWERED" 1 "HARD_RESET_SETUP" 2 "HARD_RESET" 3 "INIT_SPI" 4 "SPI_ERROR" 5 "ENABLE_MOTOR" 6 "READY" 7 "STALL" 8 "FAULT_SHORT_COIL" 9 "FAULT_OPEN_COIL" 10 "DRIVER_FAULT" 11 "SPI_COMMS_DOWN";
VAL_ 705 VCFRONT_activeLouverMotorState 0 "UNPOWERED" 1 "INIT_I2C" 2 "INIT_EEPROM" 3 "I2C_ERROR" 4 "READY" 5 "BRAKE" 6 "STALL" 7 "FAULT_MOTOR_DISCONNECTED" 8 "DRIVER_FAULT";
VAL_ 705 VCFRONT_activeLouverState 0 "UNCALIBRATED" 1 "CALIB_CLOSE" 2 "CALIB_OPEN" 3 "READY" 4 "FAULTED";
VAL_ 706 VCLEFT_windowStatusIndex 0 "Mux0" 1 "Mux1" ;
VAL_ 707 VCRIGHT_windowStatusIndex 0 "Mux0" 1 "Mux1" ;
VAL_ 708 PCS_logMessageSelect 0 "PHA_1" 1 "PHB_1" 2 "PHC_1" 3 "CHG_1" 4 "CHG_2" 5 "CHG_3" 6 "DCDC_1" 7 "DCDC_2" 8 "DCDC_3" 9 "SYSTEM_1" 10 "PHA_2" 11 "PHB_2" 12 "PHC_2" 13 "CHG_4" 14 "DLOG_1" 15 "DLOG_2" 16 "DLOG_3" 17 "DLOG_4" 18 "DCDC_4" 19 "DCDC_5" 20 "CHG_NO_FLOW" 21 "CHG_LINE_OFFSET" 22 "DCDC_STATISTICS" 23 "CHG_STATISTICS" 24 "NUM_MSGS";
VAL_ 708 PCS_chgInputFrequencyL1N 0 "FREQUENCY_UNKNOWN";
VAL_ 708 PCS_chgInputFrequencyL2N 0 "FREQUENCY_UNKNOWN";
VAL_ 708 PCS_chgInputFrequencyL3N 0 "FREQUENCY_UNKNOWN";
VAL_ 708 PCS_chgInternalPhaseConfig 0 "SNA" 1 "SINGLE_PHASE" 2 "THREE_PHASE" 3 "THREE_PHASE_DELTA" 4 "SINGLE_PHASE_IEC_GB" 5 "MFG_TEST_CONFIG_1" 6 "MFG_TEST_CONFIG_2" 7 "TOTAL_NUM";
VAL_ 708 PCS_chgPhAState 0 "INIT" 1 "IDLE" 2 "PRECHARGE" 3 "ENABLE" 4 "FAULT" 5 "CLEAR_FAULTS" 6 "SHUTTING_DOWN";
VAL_ 708 PCS_chgPhBState 0 "INIT" 1 "IDLE" 2 "PRECHARGE" 3 "ENABLE" 4 "FAULT" 5 "CLEAR_FAULTS" 6 "SHUTTING_DOWN";
VAL_ 708 PCS_chgPhCState 0 "INIT" 1 "IDLE" 2 "PRECHARGE" 3 "ENABLE" 4 "FAULT" 5 "CLEAR_FAULTS" 6 "SHUTTING_DOWN";
VAL_ 708 PCS_chgPhALastShutdownReason 0 "REASON_NONE" 1 "SW_ENABLE" 2 "HW_ENABLE" 3 "SW_FAULT" 4 "HW_FAULT" 5 "PLL_NOT_LOCKED" 6 "INPUT_UV" 7 "INPUT_OV" 8 "OUTPUT_UV" 9 "OUTPUT_OV" 10 "PRECHARGE_TIMEOUT" 11 "INT_BUS_UV" 12 "CONTROL_REGULATION_FAULT" 13 "OVER_TEMPERATURE" 14 "TEMP_IRRATIONAL" 15 "SENSOR_IRRATIONAL" 16 "FREQ_OUT_OF_RANGE" 17 "LINE_TRANSIENT_FAULT";
VAL_ 708 PCS_chgPhBLastShutdownReason 0 "REASON_NONE" 1 "SW_ENABLE" 2 "HW_ENABLE" 3 "SW_FAULT" 4 "HW_FAULT" 5 "PLL_NOT_LOCKED" 6 "INPUT_UV" 7 "INPUT_OV" 8 "OUTPUT_UV" 9 "OUTPUT_OV" 10 "PRECHARGE_TIMEOUT" 11 "INT_BUS_UV" 12 "CONTROL_REGULATION_FAULT" 13 "OVER_TEMPERATURE" 14 "TEMP_IRRATIONAL" 15 "SENSOR_IRRATIONAL" 16 "FREQ_OUT_OF_RANGE" 17 "LINE_TRANSIENT_FAULT";
VAL_ 708 PCS_chgPhCLastShutdownReason 0 "REASON_NONE" 1 "SW_ENABLE" 2 "HW_ENABLE" 3 "SW_FAULT" 4 "HW_FAULT" 5 "PLL_NOT_LOCKED" 6 "INPUT_UV" 7 "INPUT_OV" 8 "OUTPUT_UV" 9 "OUTPUT_OV" 10 "PRECHARGE_TIMEOUT" 11 "INT_BUS_UV" 12 "CONTROL_REGULATION_FAULT" 13 "OVER_TEMPERATURE" 14 "TEMP_IRRATIONAL" 15 "SENSOR_IRRATIONAL" 16 "FREQ_OUT_OF_RANGE" 17 "LINE_TRANSIENT_FAULT";
VAL_ 708 PCS_dcdcTankVoltage -1024 "TANK_VOLTAGE_SNA";
VAL_ 708 PCS_cpu2BootState 0 "BOOTROM" 1 "BOOTLOADER" 2 "APPLICATION" 3 "ERROR";
VAL_ 708 PCS_acChargeSelfTestState 0 "IDLE" 1 "STARTED";
VAL_ 708 PCS_chgInputFreqWobblePHAPeak 0 "FREQUENCY_UNKNOWN";
VAL_ 708 PCS_chgInputFreqWobblePHBPeak 0 "FREQUENCY_UNKNOWN";
VAL_ 708 PCS_chgInputFreqWobblePHCPeak 0 "FREQUENCY_UNKNOWN";
VAL_ 708 PCS_dLogPhAChannel1Content 0 "INPUT_VOLTAGE" 1 "INPUT_CURRENT" 2 "OUTPUT_CURRENT" 3 "INT_BUS_VOLTAGE";
VAL_ 708 PCS_dLogPhBChannel1Content 0 "INPUT_VOLTAGE" 1 "INPUT_CURRENT" 2 "OUTPUT_CURRENT" 3 "INT_BUS_VOLTAGE";
VAL_ 708 PCS_dLogPhCChannel1Content 0 "INPUT_VOLTAGE" 1 "INPUT_CURRENT" 2 "OUTPUT_CURRENT" 3 "INT_BUS_VOLTAGE";
VAL_ 708 PCS_dLogPhAChannel2Content 0 "INPUT_VOLTAGE" 1 "INPUT_CURRENT" 2 "OUTPUT_CURRENT" 3 "INT_BUS_VOLTAGE";
VAL_ 708 PCS_dLogPhBChannel2Content 0 "INPUT_VOLTAGE" 1 "INPUT_CURRENT" 2 "OUTPUT_CURRENT" 3 "INT_BUS_VOLTAGE";
VAL_ 708 PCS_dLogPhCChannel2Content 0 "INPUT_VOLTAGE" 1 "INPUT_CURRENT" 2 "OUTPUT_CURRENT" 3 "INT_BUS_VOLTAGE";
VAL_ 708 PCS_dLogPhAChannel3Content 0 "INPUT_VOLTAGE" 1 "INPUT_CURRENT" 2 "OUTPUT_CURRENT" 3 "INT_BUS_VOLTAGE";
VAL_ 708 PCS_dLogPhBChannel3Content 0 "INPUT_VOLTAGE" 1 "INPUT_CURRENT" 2 "OUTPUT_CURRENT" 3 "INT_BUS_VOLTAGE";
VAL_ 708 PCS_dLogPhCChannel3Content 0 "INPUT_VOLTAGE" 1 "INPUT_CURRENT" 2 "OUTPUT_CURRENT" 3 "INT_BUS_VOLTAGE";
VAL_ 708 PCS_dLogPhAChannel4Content 0 "INPUT_VOLTAGE" 1 "INPUT_CURRENT" 2 "OUTPUT_CURRENT" 3 "INT_BUS_VOLTAGE";
VAL_ 708 PCS_dLogPhBChannel4Content 0 "INPUT_VOLTAGE" 1 "INPUT_CURRENT" 2 "OUTPUT_CURRENT" 3 "INT_BUS_VOLTAGE";
VAL_ 708 PCS_dLogPhCChannel4Content 0 "INPUT_VOLTAGE" 1 "INPUT_CURRENT" 2 "OUTPUT_CURRENT" 3 "INT_BUS_VOLTAGE";
VAL_ 723 UI_isSunUp 0 "SUN_DOWN" 3 "SUN_SNA" 1 "SUN_UP" ;
VAL_ 723 UI_solarAzimuthAngle 32768 "SNA" ;
VAL_ 723 UI_solarAzimuthAngleCarRef 255 "SNA" ;
VAL_ 723 UI_solarElevationAngle 127 "SNA" ;
VAL_ 725 DIF_wasteState 1 "DI_WASTE_AVAILABLE" 2 "DI_WASTE_ON" 3 "DI_WASTE_STATIONARY" 0 "DI_WASTE_UNAVAILABLE" ;
VAL_ 727 VCLEFT_pitchEstimate -512 "SNA" ;
VAL_ 727 VCLEFT_pitchEstimateArbitratedState 3 "PITCHESTIMATION_ARBITRATEDSTATE_CYCLE_DELTA_CARRYOVER" 4 "PITCHESTIMATION_ARBITRATEDSTATE_CYCLE_DELTA_FROZEN" 2 "PITCHESTIMATION_ARBITRATEDSTATE_CYCLE_DELTA_LIVE" 1 "PITCHESTIMATION_ARBITRATEDSTATE_FUSION" 5 "PITCHESTIMATION_ARBITRATEDSTATE_LIVE_AX_NO_DELTA" 0 "PITCHESTIMATION_ARBITRATEDSTATE_UNAVAILABLE" 7 "PITCHESTIMATION_ARBITRATEDSTATE_UNKNOWN" ;
VAL_ 737 VCFRONT_statusIndex 0 "VCF_STS_IDX_BODY_CONTROLS" 2 "VCF_STS_IDX_HOMELINK" 6 "VCF_STS_IDX_INVALID" 4 "VCF_STS_IDX_LV_BATTERY" 3 "VCF_STS_IDX_REFRIGERANT_SYSTEM" 5 "VCF_STS_IDX_SYSTEM_HEALTH" 1 "VCF_STS_IDX_VEHICLE_STATE" ;
VAL_ 737 VCFRONT_AS8510Voltage 4095 "SNA" ;
VAL_ 737 VCFRONT_airCompressorStatus 4 "VCFRONT_AIR_COMPRESSOR_STATUS_FAULT" 0 "VCFRONT_AIR_COMPRESSOR_STATUS_OFF" 1 "VCFRONT_AIR_COMPRESSOR_STATUS_ON" 5 "VCFRONT_AIR_COMPRESSOR_STATUS_RETRY_AVAILABLE" 7 "VCFRONT_AIR_COMPRESSOR_STATUS_SNA" 2 "VCFRONT_AIR_COMPRESSOR_STATUS_TURNING_OFF" 3 "VCFRONT_AIR_COMPRESSOR_STATUS_TURNING_ON" ;
VAL_ 737 VCFRONT_batterySMState 1 "BATTERY_SM_STATE_CHARGE" 2 "BATTERY_SM_STATE_DISCHARGE" 6 "BATTERY_SM_STATE_DISCONNECTED_BATTERY_TEST" 8 "BATTERY_SM_STATE_FAULT" 0 "BATTERY_SM_STATE_INIT" 5 "BATTERY_SM_STATE_OTA_STANDBY" 4 "BATTERY_SM_STATE_RESISTANCE_ESTIMATION" 7 "BATTERY_SM_STATE_SHORTED_CELL_TEST" 3 "BATTERY_SM_STATE_STANDBY" ;
VAL_ 737 VCFRONT_coolantFillRoutineStatus 3 "FAULTED" 1 "MOVING_TO_FILL_POSITION" 0 "NOT_READY" 2 "READY_TO_FILL" ;
VAL_ 737 VCFRONT_crashDetectedType 1 "CRASH_DETECTED_TYPE_MINOR_1" 2 "CRASH_DETECTED_TYPE_MINOR_2" 0 "CRASH_DETECTED_TYPE_NONE" 3 "CRASH_DETECTED_TYPE_SEVERE" ;
VAL_ 737 VCFRONT_crashState 0 "CRASH_STATE_IDLE" 1 "CRASH_STATE_MINOR_1" 2 "CRASH_STATE_MINOR_2" 3 "CRASH_STATE_SEVERE" ;
VAL_ 737 VCFRONT_frunkLatchStatus 5 "LATCH_AJAR" 2 "LATCH_CLOSED" 3 "LATCH_CLOSING" 7 "LATCH_DEFAULT" 8 "LATCH_FAULT" 1 "LATCH_OPENED" 4 "LATCH_OPENING" 0 "LATCH_SNA" 6 "LATCH_TIMEOUT" ;
VAL_ 737 VCFRONT_frunkLatchType 1 "FRUNK_LATCH_TYPE_DOUBLE_ACTUATOR" 2 "FRUNK_LATCH_TYPE_DOUBLE_PULL" 0 "FRUNK_LATCH_TYPE_UNKNOWN" ;
VAL_ 737 VCFRONT_homelinkCommStatus 3 "HOMELINK_COMM_STATUS_FAULT" 1 "HOMELINK_COMM_STATUS_OFF" 2 "HOMELINK_COMM_STATUS_ON" 0 "HOMELINK_COMM_STATUS_SNA" ;
VAL_ 737 VCFRONT_hvacPerfTestCommand 2 "BLOW" 1 "INIT" 0 "NOT_STARTED" 3 "STOP" ;
VAL_ 737 VCFRONT_iBoosterStateDBG 4 "IBOOSTER_FORCE_OFF" 2 "IBOOSTER_GOING_DOWN" 0 "IBOOSTER_OFF" 1 "IBOOSTER_ON" 3 "IBOOSTER_WRITING_DATA_SHUTDOWN" ;
VAL_ 737 VCFRONT_passengerBuckleStatus 1 "BUCKLED" 0 "UNBUCKLED" ;
VAL_ 737 VCFRONT_pressureRefrigDischarge 255 "SNA" ;
VAL_ 737 VCFRONT_pressureRefrigSuction 127 "SNA" ;
VAL_ 737 VCFRONT_radarHeaterState 4 "HEATER_STATE_FAULT" 2 "HEATER_STATE_OFF" 3 "HEATER_STATE_OFF_UNAVAILABLE" 1 "HEATER_STATE_ON" 0 "HEATER_STATE_SNA" ;
VAL_ 737 VCFRONT_refrigFillRoutineStatus 3 "FAULTED" 1 "MOVING_TO_FILL_POSITION" 0 "NOT_READY" 2 "READY_TO_FILL" ;
VAL_ 737 VCFRONT_vbatMonitorVoltage 4095 "SNA" ;
VAL_ 737 VCFRONT_vehicleStatusDBG 10 "VEHICLE_STATUS_ACCESSORY" 11 "VEHICLE_STATUS_ACCESSORY_PLUS" 3 "VEHICLE_STATUS_BATTERY_POST_WAKE" 12 "VEHICLE_STATUS_CONDITIONING" 14 "VEHICLE_STATUS_CRASH" 13 "VEHICLE_STATUS_DRIVE" 9 "VEHICLE_STATUS_HV_UP_STANDBY" 0 "VEHICLE_STATUS_INIT" 1 "VEHICLE_STATUS_LOW_POWER_STANDBY" 8 "VEHICLE_STATUS_LV_AWAKE" 7 "VEHICLE_STATUS_LV_SHUTDOWN" 15 "VEHICLE_STATUS_OTA" 17 "VEHICLE_STATUS_RESET" 2 "VEHICLE_STATUS_SILENT_WAKE" 5 "VEHICLE_STATUS_SLEEP_SHUTDOWN" 6 "VEHICLE_STATUS_SLEEP_STANDBY" 4 "VEHICLE_STATUS_SYSTEM_CHECKS" 16 "VEHICLE_STATUS_TURN_ON_RAILS" ;
VAL_ 737 VCFRONT_voltageProfile 3 "VOLTAGE_PROFILE_ALWAYS_CLOSED_CONTACTORS" 0 "VOLTAGE_PROFILE_CHARGE" 1 "VOLTAGE_PROFILE_FLOAT" 2 "VOLTAGE_PROFILE_REDUCED_FLOAT" ;
VAL_ 737 VCFRONT_wiperPosition 3 "WIPER_POSITION_DELAYED_REST" 2 "WIPER_POSITION_DEPRESSED_PARK" 1 "WIPER_POSITION_SERVICE" 0 "WIPER_POSITION_SNA" 4 "WIPER_POSITION_WIPING" ;
VAL_ 737 VCFRONT_wiperSpeed 2 "WIPER_SPEED_1" 3 "WIPER_SPEED_2" 4 "WIPER_SPEED_3" 5 "WIPER_SPEED_4" 6 "WIPER_SPEED_5" 8 "WIPER_SPEED_HIGH" 7 "WIPER_SPEED_LOW" 1 "WIPER_SPEED_OFF" 0 "WIPER_SPEED_SNA" ;
VAL_ 737 VCFRONT_wiperState 9 "WIPER_STATE_CONT_FAST" 10 "WIPER_STATE_CONT_SLOW" 3 "WIPER_STATE_DELAYED_REST" 2 "WIPER_STATE_FAULT" 7 "WIPER_STATE_INTERMITTENT_HIGH" 8 "WIPER_STATE_INTERMITTENT_LOW" 12 "WIPER_STATE_INT_AUTO_HIGH" 11 "WIPER_STATE_INT_AUTO_LOW" 6 "WIPER_STATE_MOMENTARY_WIPE" 4 "WIPER_STATE_PARK" 1 "WIPER_STATE_SERVICE" 0 "WIPER_STATE_SNA" 5 "WIPER_STATE_WASH" ;
VAL_ 744 EPBR_systemStatus 3 "EPB_VEHICLE_STATUS_DYNAMIC" 6 "EPB_VEHICLE_STATUS_FAULT" 7 "EPB_VEHICLE_STATUS_FAULT_SECURE" 8 "EPB_VEHICLE_STATUS_MISMATCH" 2 "EPB_VEHICLE_STATUS_PARKED" 4 "EPB_VEHICLE_STATUS_PARKING" 1 "EPB_VEHICLE_STATUS_RELEASED" 5 "EPB_VEHICLE_STATUS_RELEASING" 0 "EPB_VEHICLE_STATUS_UNKNOWN" ;
VAL_ 753 VCFRONT_eFuseDebugStatusIndex 8 "VCF_DBG_STS_AUTOPILOT_1" 9 "VCF_DBG_STS_AUTOPILOT_2" 4 "VCF_DBG_STS_EPAS3P" 5 "VCF_DBG_STS_EPAS3S" 6 "VCF_DBG_STS_ESP_MOTOR" 7 "VCF_DBG_STS_ESP_VALVE" 12 "VCF_DBG_STS_HEADLAMPS" 3 "VCF_DBG_STS_IBOOSTER" 18 "VCF_DBG_STS_INVALID" 17 "VCF_DBG_STS_LV_BATTERY_DEBUG" 16 "VCF_DBG_STS_MISC_RAILS" 2 "VCF_DBG_STS_PCS" 14 "VCF_DBG_STS_PUMPS" 15 "VCF_DBG_STS_RAILS_A_B" 10 "VCF_DBG_STS_SLEEP_BYPASS" 11 "VCF_DBG_STS_UI" 13 "VCF_DBG_STS_VBAT_FUSED_HIGH_CURRENT" 1 "VCF_DBG_STS_VCLEFT" 0 "VCF_DBG_STS_VCRIGHT" ;
VAL_ 753 VCFRONT_EPAS3PSelfTestResult 4 "EFUSE_SELF_TEST_EFUSE_RESULT_FAILED_EFUSE_OUTPUT_SHORT" 8 "EFUSE_SELF_TEST_EFUSE_RESULT_FAILED_ENABLE_HIGH_MALFUNCTION" 6 "EFUSE_SELF_TEST_EFUSE_RESULT_FAILED_ENABLE_LOW_MALFUNCTION" 10 "EFUSE_SELF_TEST_EFUSE_RESULT_FAILED_NOT_LATCHED" 7 "EFUSE_SELF_TEST_EFUSE_RESULT_FAILED_POWER_FET_CHANNEL_OPEN" 5 "EFUSE_SELF_TEST_EFUSE_RESULT_FAILED_POWER_FET_STUCK_ON" 3 "EFUSE_SELF_TEST_EFUSE_RESULT_FAILED_RAILS_UNSTABLE" 9 "EFUSE_SELF_TEST_EFUSE_RESULT_FAILED_TURN_OFF_PATH_TOO_SLOW" 0 "EFUSE_SELF_TEST_EFUSE_RESULT_NOT_RUN" 2 "EFUSE_SELF_TEST_EFUSE_RESULT_PASSED" 1 "EFUSE_SELF_TEST_EFUSE_RESULT_RUNNING" 11 "EFUSE_SELF_TEST_EFUSE_RESULT_SKIPPED" ;
VAL_ 753 VCFRONT_EPAS3PState 2 "EFUSE_STATE_LOCKED_OUT" 0 "EFUSE_STATE_OFF" 1 "EFUSE_STATE_ON" ;
VAL_ 753 VCFRONT_EPAS3SSelfTestResult 4 "EFUSE_SELF_TEST_EFUSE_RESULT_FAILED_EFUSE_OUTPUT_SHORT" 8 "EFUSE_SELF_TEST_EFUSE_RESULT_FAILED_ENABLE_HIGH_MALFUNCTION" 6 "EFUSE_SELF_TEST_EFUSE_RESULT_FAILED_ENABLE_LOW_MALFUNCTION" 10 "EFUSE_SELF_TEST_EFUSE_RESULT_FAILED_NOT_LATCHED" 7 "EFUSE_SELF_TEST_EFUSE_RESULT_FAILED_POWER_FET_CHANNEL_OPEN" 5 "EFUSE_SELF_TEST_EFUSE_RESULT_FAILED_POWER_FET_STUCK_ON" 3 "EFUSE_SELF_TEST_EFUSE_RESULT_FAILED_RAILS_UNSTABLE" 9 "EFUSE_SELF_TEST_EFUSE_RESULT_FAILED_TURN_OFF_PATH_TOO_SLOW" 0 "EFUSE_SELF_TEST_EFUSE_RESULT_NOT_RUN" 2 "EFUSE_SELF_TEST_EFUSE_RESULT_PASSED" 1 "EFUSE_SELF_TEST_EFUSE_RESULT_RUNNING" 11 "EFUSE_SELF_TEST_EFUSE_RESULT_SKIPPED" ;
VAL_ 753 VCFRONT_EPAS3SState 2 "EFUSE_STATE_LOCKED_OUT" 0 "EFUSE_STATE_OFF" 1 "EFUSE_STATE_ON" ;
VAL_ 753 VCFRONT_ESPMotorSelfTestResult 4 "EFUSE_SELF_TEST_EFUSE_RESULT_FAILED_EFUSE_OUTPUT_SHORT" 8 "EFUSE_SELF_TEST_EFUSE_RESULT_FAILED_ENABLE_HIGH_MALFUNCTION" 6 "EFUSE_SELF_TEST_EFUSE_RESULT_FAILED_ENABLE_LOW_MALFUNCTION" 10 "EFUSE_SELF_TEST_EFUSE_RESULT_FAILED_NOT_LATCHED" 7 "EFUSE_SELF_TEST_EFUSE_RESULT_FAILED_POWER_FET_CHANNEL_OPEN" 5 "EFUSE_SELF_TEST_EFUSE_RESULT_FAILED_POWER_FET_STUCK_ON" 3 "EFUSE_SELF_TEST_EFUSE_RESULT_FAILED_RAILS_UNSTABLE" 9 "EFUSE_SELF_TEST_EFUSE_RESULT_FAILED_TURN_OFF_PATH_TOO_SLOW" 0 "EFUSE_SELF_TEST_EFUSE_RESULT_NOT_RUN" 2 "EFUSE_SELF_TEST_EFUSE_RESULT_PASSED" 1 "EFUSE_SELF_TEST_EFUSE_RESULT_RUNNING" 11 "EFUSE_SELF_TEST_EFUSE_RESULT_SKIPPED" ;
VAL_ 753 VCFRONT_ESPMotorState 2 "EFUSE_STATE_LOCKED_OUT" 0 "EFUSE_STATE_OFF" 1 "EFUSE_STATE_ON" ;
VAL_ 753 VCFRONT_ESPValveState 2 "EFUSE_STATE_LOCKED_OUT" 0 "EFUSE_STATE_OFF" 1 "EFUSE_STATE_ON" ;
VAL_ 753 VCFRONT_PCSState 2 "EFUSE_STATE_LOCKED_OUT" 0 "EFUSE_STATE_OFF" 1 "EFUSE_STATE_ON" ;
VAL_ 753 VCFRONT_autopilot1State 2 "EFUSE_STATE_LOCKED_OUT" 0 "EFUSE_STATE_OFF" 1 "EFUSE_STATE_ON" ;
VAL_ 753 VCFRONT_autopilot2State 2 "EFUSE_STATE_LOCKED_OUT" 0 "EFUSE_STATE_OFF" 1 "EFUSE_STATE_ON" ;
VAL_ 753 VCFRONT_headlampLeftTemperature 128 "SNA" ;
VAL_ 753 VCFRONT_headlampLeftVoltage 255 "SNA" ;
VAL_ 753 VCFRONT_headlampRightTemperature 128 "SNA" ;
VAL_ 753 VCFRONT_headlampRightVoltage 255 "SNA" ;
VAL_ 753 VCFRONT_iBoosterSelfTestResult 4 "EFUSE_SELF_TEST_EFUSE_RESULT_FAILED_EFUSE_OUTPUT_SHORT" 8 "EFUSE_SELF_TEST_EFUSE_RESULT_FAILED_ENABLE_HIGH_MALFUNCTION" 6 "EFUSE_SELF_TEST_EFUSE_RESULT_FAILED_ENABLE_LOW_MALFUNCTION" 10 "EFUSE_SELF_TEST_EFUSE_RESULT_FAILED_NOT_LATCHED" 7 "EFUSE_SELF_TEST_EFUSE_RESULT_FAILED_POWER_FET_CHANNEL_OPEN" 5 "EFUSE_SELF_TEST_EFUSE_RESULT_FAILED_POWER_FET_STUCK_ON" 3 "EFUSE_SELF_TEST_EFUSE_RESULT_FAILED_RAILS_UNSTABLE" 9 "EFUSE_SELF_TEST_EFUSE_RESULT_FAILED_TURN_OFF_PATH_TOO_SLOW" 0 "EFUSE_SELF_TEST_EFUSE_RESULT_NOT_RUN" 2 "EFUSE_SELF_TEST_EFUSE_RESULT_PASSED" 1 "EFUSE_SELF_TEST_EFUSE_RESULT_RUNNING" 11 "EFUSE_SELF_TEST_EFUSE_RESULT_SKIPPED" ;
VAL_ 753 VCFRONT_iBoosterState 2 "EFUSE_STATE_LOCKED_OUT" 0 "EFUSE_STATE_OFF" 1 "EFUSE_STATE_ON" ;
VAL_ 753 VCFRONT_leftControllerState 2 "EFUSE_STATE_LOCKED_OUT" 0 "EFUSE_STATE_OFF" 1 "EFUSE_STATE_ON" ;
VAL_ 753 VCFRONT_pcsSelfTestResult 4 "EFUSE_SELF_TEST_EFUSE_RESULT_FAILED_EFUSE_OUTPUT_SHORT" 8 "EFUSE_SELF_TEST_EFUSE_RESULT_FAILED_ENABLE_HIGH_MALFUNCTION" 6 "EFUSE_SELF_TEST_EFUSE_RESULT_FAILED_ENABLE_LOW_MALFUNCTION" 10 "EFUSE_SELF_TEST_EFUSE_RESULT_FAILED_NOT_LATCHED" 7 "EFUSE_SELF_TEST_EFUSE_RESULT_FAILED_POWER_FET_CHANNEL_OPEN" 5 "EFUSE_SELF_TEST_EFUSE_RESULT_FAILED_POWER_FET_STUCK_ON" 3 "EFUSE_SELF_TEST_EFUSE_RESULT_FAILED_RAILS_UNSTABLE" 9 "EFUSE_SELF_TEST_EFUSE_RESULT_FAILED_TURN_OFF_PATH_TOO_SLOW" 0 "EFUSE_SELF_TEST_EFUSE_RESULT_NOT_RUN" 2 "EFUSE_SELF_TEST_EFUSE_RESULT_PASSED" 1 "EFUSE_SELF_TEST_EFUSE_RESULT_RUNNING" 11 "EFUSE_SELF_TEST_EFUSE_RESULT_SKIPPED" ;
VAL_ 753 VCFRONT_rightControllerState 2 "EFUSE_STATE_LOCKED_OUT" 0 "EFUSE_STATE_OFF" 1 "EFUSE_STATE_ON" ;
VAL_ 753 VCFRONT_vbatFusedSelfTestResult 4 "EFUSE_SELF_TEST_EFUSE_RESULT_FAILED_EFUSE_OUTPUT_SHORT" 8 "EFUSE_SELF_TEST_EFUSE_RESULT_FAILED_ENABLE_HIGH_MALFUNCTION" 6 "EFUSE_SELF_TEST_EFUSE_RESULT_FAILED_ENABLE_LOW_MALFUNCTION" 10 "EFUSE_SELF_TEST_EFUSE_RESULT_FAILED_NOT_LATCHED" 7 "EFUSE_SELF_TEST_EFUSE_RESULT_FAILED_POWER_FET_CHANNEL_OPEN" 5 "EFUSE_SELF_TEST_EFUSE_RESULT_FAILED_POWER_FET_STUCK_ON" 3 "EFUSE_SELF_TEST_EFUSE_RESULT_FAILED_RAILS_UNSTABLE" 9 "EFUSE_SELF_TEST_EFUSE_RESULT_FAILED_TURN_OFF_PATH_TOO_SLOW" 0 "EFUSE_SELF_TEST_EFUSE_RESULT_NOT_RUN" 2 "EFUSE_SELF_TEST_EFUSE_RESULT_PASSED" 1 "EFUSE_SELF_TEST_EFUSE_RESULT_RUNNING" 11 "EFUSE_SELF_TEST_EFUSE_RESULT_SKIPPED" ;
VAL_ 753 VCFRONT_vcleftSelfTestResult 4 "EFUSE_SELF_TEST_EFUSE_RESULT_FAILED_EFUSE_OUTPUT_SHORT" 8 "EFUSE_SELF_TEST_EFUSE_RESULT_FAILED_ENABLE_HIGH_MALFUNCTION" 6 "EFUSE_SELF_TEST_EFUSE_RESULT_FAILED_ENABLE_LOW_MALFUNCTION" 10 "EFUSE_SELF_TEST_EFUSE_RESULT_FAILED_NOT_LATCHED" 7 "EFUSE_SELF_TEST_EFUSE_RESULT_FAILED_POWER_FET_CHANNEL_OPEN" 5 "EFUSE_SELF_TEST_EFUSE_RESULT_FAILED_POWER_FET_STUCK_ON" 3 "EFUSE_SELF_TEST_EFUSE_RESULT_FAILED_RAILS_UNSTABLE" 9 "EFUSE_SELF_TEST_EFUSE_RESULT_FAILED_TURN_OFF_PATH_TOO_SLOW" 0 "EFUSE_SELF_TEST_EFUSE_RESULT_NOT_RUN" 2 "EFUSE_SELF_TEST_EFUSE_RESULT_PASSED" 1 "EFUSE_SELF_TEST_EFUSE_RESULT_RUNNING" 11 "EFUSE_SELF_TEST_EFUSE_RESULT_SKIPPED" ;
VAL_ 753 VCFRONT_vcrightSelfTestResult 4 "EFUSE_SELF_TEST_EFUSE_RESULT_FAILED_EFUSE_OUTPUT_SHORT" 8 "EFUSE_SELF_TEST_EFUSE_RESULT_FAILED_ENABLE_HIGH_MALFUNCTION" 6 "EFUSE_SELF_TEST_EFUSE_RESULT_FAILED_ENABLE_LOW_MALFUNCTION" 10 "EFUSE_SELF_TEST_EFUSE_RESULT_FAILED_NOT_LATCHED" 7 "EFUSE_SELF_TEST_EFUSE_RESULT_FAILED_POWER_FET_CHANNEL_OPEN" 5 "EFUSE_SELF_TEST_EFUSE_RESULT_FAILED_POWER_FET_STUCK_ON" 3 "EFUSE_SELF_TEST_EFUSE_RESULT_FAILED_RAILS_UNSTABLE" 9 "EFUSE_SELF_TEST_EFUSE_RESULT_FAILED_TURN_OFF_PATH_TOO_SLOW" 0 "EFUSE_SELF_TEST_EFUSE_RESULT_NOT_RUN" 2 "EFUSE_SELF_TEST_EFUSE_RESULT_PASSED" 1 "EFUSE_SELF_TEST_EFUSE_RESULT_RUNNING" 11 "EFUSE_SELF_TEST_EFUSE_RESULT_SKIPPED" ;
VAL_ 754 BMS_nmKeepAwakeReason 0 "NONE_SNA" 1 "CTRS_CLOSED" 2 "CRITICAL_ALERT" 3 "FC_CTR_CLEANING" 4 "HVP_ACTIVE" 5 "BMS_ACTIVE" 6 "CP_ACTIVE";
VAL_ 754 BMS_nmWakeUpReason 0 "NONE" 1 "CAN_VEH" 2 "CAN_HVS" 3 "WANTTOCHARGE" 4 "CRITICALALERT" 5 "WANTTOWARM";
VAL_ 755 UI_hvacReqACDisable 0 "AUTO" 1 "OFF" 2 "ON" ;
VAL_ 755 UI_hvacReqAirDistributionMode 0 "AUTO" 4 "MANUAL_DEFROST" 5 "MANUAL_DEFROST_FLOOR" 6 "MANUAL_DEFROST_PANEL" 7 "MANUAL_DEFROST_PANEL_FLOOR" 1 "MANUAL_FLOOR" 2 "MANUAL_PANEL" 3 "MANUAL_PANEL_FLOOR" ;
VAL_ 755 UI_hvacReqBlowerSegment 1 "1" 10 "10" 2 "2" 3 "3" 4 "4" 5 "5" 6 "6" 7 "7" 8 "8" 9 "9" 11 "AUTO" 0 "OFF" ;
VAL_ 755 UI_hvacReqKeepClimateOn 2 "KEEP_CLIMATE_ON_REQ_DOG" 0 "KEEP_CLIMATE_ON_REQ_OFF" 1 "KEEP_CLIMATE_ON_REQ_ON" 3 "KEEP_CLIMATE_ON_REQ_PARTY" ;
VAL_ 755 UI_hvacReqManualDefogState 1 "DEFOG" 2 "DEFROST" 0 "NONE" ;
VAL_ 755 UI_hvacReqRecirc 0 "AUTO" 2 "FRESH" 1 "RECIRC" ;
VAL_ 755 UI_hvacReqSecondRowState 0 "AUTO" 4 "HIGH" 2 "LOW" 3 "MED" 1 "OFF" ;
VAL_ 755 UI_hvacReqTempSetpointLeft 26 "HI" 0 "LO" ;
VAL_ 755 UI_hvacReqTempSetpointRight 26 "HI" 0 "LO" ;
VAL_ 755 UI_hvacReqUserPowerState 0 "OFF" 1 "ON" 4 "OVERHEAT_PROTECT" 3 "OVERHEAT_PROTECT_FANONLY" 2 "PRECONDITION" ;
VAL_ 768 BMS_infoIndex 13 "INFO_APP_CRC" 17 "INFO_APP_GITHASH" 15 "INFO_BOOTLOADER_CRC" 18 "INFO_BOOTLOADER_GITHASH" 14 "INFO_BOOTLOADER_SVN" 10 "INFO_BUILD_HWID_COMPONENTID" 0 "INFO_DEPRECATED_0" 1 "INFO_DEPRECATED_1" 2 "INFO_DEPRECATED_2" 3 "INFO_DEPRECATED_3" 4 "INFO_DEPRECATED_4" 5 "INFO_DEPRECATED_5" 6 "INFO_DEPRECATED_6" 7 "INFO_DEPRECATED_7" 8 "INFO_DEPRECATED_8" 9 "INFO_DEPRECATED_9" 255 "INFO_END" 27 "INFO_PACKAGE_PN_15_20" 25 "INFO_PACKAGE_PN_1_7" 26 "INFO_PACKAGE_PN_8_14" 29 "INFO_PACKAGE_SN_1_7" 30 "INFO_PACKAGE_SN_8_14" 11 "INFO_PCBAID_ASSYID_USAGEID" 16 "INFO_SUBCOMPONENT" 31 "INFO_SUBCOMPONENT_GITHASH" 20 "INFO_UDS_PROTOCOL_BOOTCRC" 22 "INFO_VARIANTCRC" 19 "INFO_VERSION_DEPRECATED" ;
VAL_ 768 BMS_buildType 2 "INFO_LOCAL_BUILD" 4 "INFO_MFG_BUILD" 1 "INFO_PLATFORM_BUILD" 3 "INFO_TRACEABLE_CI_BUILD" 0 "INFO_UNKNOWN_BUILD" ;
VAL_ 769 VCFRONT_infoIndex 13 "BC_INFO_APP_CRC" 17 "BC_INFO_APP_GITHASH" 15 "BC_INFO_BOOTLOADER_CRC" 18 "BC_INFO_BOOTLOADER_GITHASH" 14 "BC_INFO_BOOTLOADER_SVN" 10 "BC_INFO_BUILD_HWID_COMPONENTID" 0 "BC_INFO_DEPRECATED_0" 1 "BC_INFO_DEPRECATED_1" 2 "BC_INFO_DEPRECATED_2" 3 "BC_INFO_DEPRECATED_3" 4 "BC_INFO_DEPRECATED_4" 5 "BC_INFO_DEPRECATED_5" 6 "BC_INFO_DEPRECATED_6" 7 "BC_INFO_DEPRECATED_7" 8 "BC_INFO_DEPRECATED_8" 9 "BC_INFO_DEPRECATED_9" 255 "BC_INFO_END" 11 "BC_INFO_PCBAID_ASSYID_USAGEID" 16 "BC_INFO_SUBCOMPONENT1" 23 "BC_INFO_SUBCOMPONENT2" 24 "BC_INFO_SUBCOMPONENT3" 31 "BC_INFO_SUBCOMPONENT4" 32 "BC_INFO_SUBCOMPONENT5" 33 "BC_INFO_SUBCOMPONENT6" 20 "BC_INFO_UDS_PROTOCOL_BOOTCRC" 19 "BC_INFO_VERSION_DEPRECATED" ;
VAL_ 769 VCFRONT_infoAssemblyId 1 "ASSEMBLY1" 255 "ASSEMBLY_SNA" ;
VAL_ 769 VCFRONT_infoBuildType 2 "INFO_LOCAL_BUILD" 4 "INFO_MFG_BUILD" 1 "INFO_PLATFORM_BUILD" 3 "INFO_TRACEABLE_CI_BUILD" 0 "INFO_UNKNOWN_BUILD" ;
VAL_ 770 VCLEFT_infoIndex 0 "DEPRECATED_0" 1 "DEPRECATED_1" 2 "DEPRECATED_2" 3 "DEPRECATED_3" 4 "DEPRECATED_4" 5 "DEPRECATED_5" 6 "DEPRECATED_6" 7 "DEPRECATED_7" 8 "DEPRECATED_8" 9 "DEPRECATED_9" 10 "BUILD_HWID_COMPONENTID" 11 "PCBAID_ASSYID_USAGEID" 13 "APP_CRC" 14 "BOOTLOADER_SVN" 15 "BOOTLOADER_CRC" 16 "SUBCOMPONENT1" 17 "APP_GITHASH" 18 "BOOTLOADER_GITHASH" 19 "VERSION_DEPRECATED" 20 "UDS_PROTOCOL_BOOTCRC" 23 "SUBCOMPONENT2" 24 "SUBCOMPONENT3" 31 "SUBCOMPONENT4" 255 "END";
VAL_ 770 VCLEFT_infoBuildType 0 "UNKNOWN_BUILD" 1 "PLATFORM_BUILD" 2 "LOCAL_BUILD" 3 "TRACEABLE_CI_BUILD" 4 "MFG_BUILD";
VAL_ 770 VCLEFT_infoAssemblyId 1 "ASSEMBLY1" 255 "ASSEMBLY_SNA";
VAL_ 771 OCS1P_occupiedState 1 "OCCUPIED_STATE_OCCUPIED" 3 "OCCUPIED_STATE_SNA" 0 "OCCUPIED_STATE_UNOCCUPIED" ;
VAL_ 774 VCRIGHT_infoIndex 0 "DEPRECATED_0" 1 "DEPRECATED_1" 2 "DEPRECATED_2" 3 "DEPRECATED_3" 4 "DEPRECATED_4" 5 "DEPRECATED_5" 6 "DEPRECATED_6" 7 "DEPRECATED_7" 8 "DEPRECATED_8" 9 "DEPRECATED_9" 10 "BUILD_HWID_COMPONENTID" 11 "PCBAID_ASSYID_USAGEID" 13 "APP_CRC" 14 "BOOTLOADER_SVN" 15 "BOOTLOADER_CRC" 16 "SUBCOMPONENT1" 17 "APP_GITHASH" 18 "BOOTLOADER_GITHASH" 19 "VERSION_DEPRECATED" 20 "UDS_PROTOCOL_BOOTCRC" 23 "SUBCOMPONENT2" 24 "SUBCOMPONENT3" 31 "SUBCOMPONENT4" 255 "END";
VAL_ 774 VCRIGHT_infoBuildType 0 "UNKNOWN_BUILD" 1 "PLATFORM_BUILD" 2 "LOCAL_BUILD" 3 "TRACEABLE_CI_BUILD" 4 "MFG_BUILD";
VAL_ 774 VCRIGHT_infoAssemblyId 1 "ASSEMBLY1" 255 "ASSEMBLY_SNA";
VAL_ 777 DAS_objectId 3 "CUTIN_VEHICLE" 0 "LEAD_VEHICLES" 1 "LEFT_VEHICLES" 2 "RIGHT_VEHICLES" 4 "ROAD_SIGN" 5 "VEHICLE_HEADINGS" ;
VAL_ 777 DAS_cutinVehDx 255 "SNA" ;
VAL_ 777 DAS_cutinVehHeading 255 "SNA" ;
VAL_ 777 DAS_cutinVehId 127 "SNA" ;
VAL_ 777 DAS_cutinVehType 4 "BICYCLE" 2 "CAR" 3 "MOTORCYCLE" 5 "PEDESTRIAN" 1 "TRUCK" 0 "UNKNOWN" ;
VAL_ 777 DAS_cutinVehVxRel 15 "SNA" ;
VAL_ 777 DAS_leadVeh2Dx 255 "SNA" ;
VAL_ 777 DAS_leadVeh2Heading 255 "SNA" ;
VAL_ 777 DAS_leadVeh2Id 0 "SNA" ;
VAL_ 777 DAS_leadVeh2Type 4 "BICYCLE" 2 "CAR" 3 "MOTORCYCLE" 5 "PEDESTRIAN" 1 "TRUCK" 0 "UNKNOWN" ;
VAL_ 777 DAS_leadVeh2VxRel 15 "SNA" ;
VAL_ 777 DAS_leadVehDx 255 "SNA" ;
VAL_ 777 DAS_leadVehHeading 255 "SNA" ;
VAL_ 777 DAS_leadVehId 127 "SNA" ;
VAL_ 777 DAS_leadVehType 4 "BICYCLE" 2 "CAR" 6 "IPSO" 3 "MOTORCYCLE" 5 "PEDESTRIAN" 1 "TRUCK" 0 "UNKNOWN" ;
VAL_ 777 DAS_leadVehVxRel 15 "SNA" ;
VAL_ 777 DAS_leftVeh2Dx 255 "SNA" ;
VAL_ 777 DAS_leftVeh2Heading 255 "SNA" ;
VAL_ 777 DAS_leftVeh2Id 0 "SNA" ;
VAL_ 777 DAS_leftVeh2Type 4 "BICYCLE" 2 "CAR" 3 "MOTORCYCLE" 5 "PEDESTRIAN" 1 "TRUCK" 0 "UNKNOWN" ;
VAL_ 777 DAS_leftVeh2VxRel 15 "SNA" ;
VAL_ 777 DAS_leftVehDx 255 "SNA" ;
VAL_ 777 DAS_leftVehHeading 255 "SNA" ;
VAL_ 777 DAS_leftVehId 127 "SNA" ;
VAL_ 777 DAS_leftVehType 4 "BICYCLE" 2 "CAR" 3 "MOTORCYCLE" 5 "PEDESTRIAN" 1 "TRUCK" 0 "UNKNOWN" ;
VAL_ 777 DAS_leftVehVxRel 15 "SNA" ;
VAL_ 777 DAS_rightVeh2Dx 255 "SNA" ;
VAL_ 777 DAS_rightVeh2Heading 255 "SNA" ;
VAL_ 777 DAS_rightVeh2Id 0 "SNA" ;
VAL_ 777 DAS_rightVeh2Type 4 "BICYCLE" 2 "CAR" 3 "MOTORCYCLE" 5 "PEDESTRIAN" 1 "TRUCK" 0 "UNKNOWN" ;
VAL_ 777 DAS_rightVeh2VxRel 15 "SNA" ;
VAL_ 777 DAS_rightVehDx 255 "SNA" ;
VAL_ 777 DAS_rightVehHeading 255 "SNA" ;
VAL_ 777 DAS_rightVehId 127 "SNA" ;
VAL_ 777 DAS_rightVehType 4 "BICYCLE" 2 "CAR" 3 "MOTORCYCLE" 5 "PEDESTRIAN" 1 "TRUCK" 0 "UNKNOWN" ;
VAL_ 777 DAS_rightVehVxRel 15 "SNA" ;
VAL_ 777 DAS_roadSignArrow 0 "CIRCLE" 1 "LEFT" 2 "RIGHT" 3 "STRAIGHT" 4 "UNKNOWN" ;
VAL_ 777 DAS_roadSignColor 3 "GREEN" 0 "NONE" 1 "RED" 4 "RED_YELLOW" 2 "YELLOW" ;
VAL_ 777 DAS_roadSignId 255 "SNA" 0 "STOP_SIGN" 1 "TRAFFIC_LIGHT" ;
VAL_ 777 DAS_roadSignOrientation 2 "HORIZONTAL_3_LIGHT" 0 "UNKNOWN" 1 "VERTICAL_3_LIGHT" ;
VAL_ 777 DAS_roadSignSource 1 "NAV" 0 "NONE" 2 "VISION" ;
VAL_ 777 DAS_roadSignStopLineDist 1023 "SNA" ;
VAL_ 778 VCLEFT_frontBuckleStatus 2 "SEAT_BELT_BUCKLE_STATUS_FAULTED" 1 "SEAT_BELT_BUCKLE_STATUS_LATCHED" 3 "SEAT_BELT_BUCKLE_STATUS_SNA" 0 "SEAT_BELT_BUCKLE_STATUS_UNLATCHED" ;
VAL_ 778 VCLEFT_frontOccupancyStatus 3 "SEAT_NOT_CONFIGURED" 2 "SEAT_OCCUPANCY_FAULTED" 7 "SEAT_OCCUPANCY_SNA" 1 "SEAT_OCCUPIED" 0 "SEAT_UNOCCUPIED" ;
VAL_ 778 VCLEFT_rearCenterOccupancyStatus 2 "SEAT_OCCUPANCY_FAULTED" 3 "SEAT_OCCUPANCY_SNA" 1 "SEAT_OCCUPIED" 0 "SEAT_UNOCCUPIED" ;
VAL_ 778 VCLEFT_rearLeftOccupancyStatus 2 "SEAT_OCCUPANCY_FAULTED" 3 "SEAT_OCCUPANCY_SNA" 1 "SEAT_OCCUPIED" 0 "SEAT_UNOCCUPIED" ;
VAL_ 778 VCLEFT_rearRightOccupancyStatus 2 "SEAT_OCCUPANCY_FAULTED" 3 "SEAT_OCCUPANCY_SNA" 1 "SEAT_OCCUPIED" 0 "SEAT_UNOCCUPIED" ;
VAL_ 782 PARK_sdiActive 0 "SDI_DISABLED" 1 "SDI_ENABLED" ;
VAL_ 784 HVP_infoIndex 0 "DEPRECATED_0" 1 "DEPRECATED_1" 2 "DEPRECATED_2" 3 "DEPRECATED_3" 4 "DEPRECATED_4" 5 "DEPRECATED_5" 6 "DEPRECATED_6" 7 "DEPRECATED_7" 8 "DEPRECATED_8" 9 "DEPRECATED_9" 10 "BUILD_HWID_COMPONENTID" 11 "PCBAID_ASSYID_USAGEID" 13 "APP_CRC" 14 "BOOTLOADER_SVN" 15 "BOOTLOADER_CRC" 16 "SUBCOMPONENT" 17 "APP_GITHASH" 18 "BOOTLOADER_GITHASH" 19 "VERSION_DEPRECATED" 20 "UDS_PROTOCOL_BOOTCRC" 22 "VARIANTCRC" 25 "PACKAGE_PN_1_7" 26 "PACKAGE_PN_8_14" 27 "PACKAGE_PN_15_20" 29 "PACKAGE_SN_1_7" 30 "PACKAGE_SN_8_14" 31 "SUBCOMPONENT_GITHASH" 255 "END";
VAL_ 784 HVP_buildType 0 "UNKNOWN_BUILD" 1 "PLATFORM_BUILD" 2 "LOCAL_BUILD" 3 "TRACEABLE_CI_BUILD" 4 "MFG_BUILD";
VAL_ 785 EPAS3S_infoIndex 0 "DEPRECATED_0" 1 "DEPRECATED_1" 2 "DEPRECATED_2" 3 "DEPRECATED_3" 4 "DEPRECATED_4" 5 "DEPRECATED_5" 6 "DEPRECATED_6" 7 "DEPRECATED_7" 8 "DEPRECATED_8" 9 "DEPRECATED_9" 10 "BUILD_HWID_COMPONENTID" 11 "PCBAID_ASSYID_USAGEID" 13 "APP_CRC" 14 "BOOTLOADER_SVN" 15 "BOOTLOADER_CRC" 16 "SUBCOMPONENT" 17 "APP_GITHASH" 18 "BOOTLOADER_GITHASH" 19 "VERSION_DEPRECATED" 20 "UDS_PROTOCOL_BOOTCRC" 22 "VARIANTCRC" 25 "PACKAGE_PN_1_7" 26 "PACKAGE_PN_8_14" 27 "PACKAGE_PN_15_20" 29 "PACKAGE_SN_1_7" 30 "PACKAGE_SN_8_14" 31 "SUBCOMPONENT_GITHASH" 255 "END";
VAL_ 785 EPAS3S_infoBuildType 0 "UNKNOWN_BUILD" 1 "PLATFORM_BUILD" 2 "LOCAL_BUILD" 3 "TRACEABLE_CI_BUILD" 4 "MFG_BUILD";
VAL_ 787 UI_trackCmpOverclock 0 "TRACK_MODE_CMP_OVERCLOCK_OFF" 1 "TRACK_MODE_CMP_OVERCLOCK_ON" ;
VAL_ 787 UI_trackModeRequest 0 "TRACK_MODE_REQUEST_IDLE" 2 "TRACK_MODE_REQUEST_OFF" 1 "TRACK_MODE_REQUEST_ON" ;
VAL_ 787 UI_trackPostCooling 0 "TRACK_MODE_POST_COOLING_OFF" 1 "TRACK_MODE_POST_COOLING_ON" ;
VAL_ 789 DIR_inverterTQF 0 "INVERTERT_INIT" 1 "INVERTERT_IRRATIONAL" 2 "INVERTERT_RATIONAL" 3 "INVERTERT_UNKNOWN" ;
VAL_ 790 PM_infoIndex 0 "DEPRECATED_0" 1 "DEPRECATED_1" 2 "DEPRECATED_2" 3 "DEPRECATED_3" 4 "DEPRECATED_4" 5 "DEPRECATED_5" 6 "DEPRECATED_6" 7 "DEPRECATED_7" 8 "DEPRECATED_8" 9 "DEPRECATED_9" 10 "BUILD_HWID_COMPONENTID" 11 "PCBAID_ASSYID_USAGEID" 13 "APP_CRC" 14 "BOOTLOADER_SVN" 15 "BOOTLOADER_CRC" 16 "SUBCOMPONENT" 17 "APP_GITHASH" 18 "BOOTLOADER_GITHASH" 19 "VERSION_DEPRECATED" 20 "UDS_PROTOCOL_BOOTCRC" 22 "VARIANTCRC" 25 "PACKAGE_PN_1_7" 26 "PACKAGE_PN_8_14" 27 "PACKAGE_PN_15_20" 29 "PACKAGE_SN_1_7" 30 "PACKAGE_SN_8_14" 31 "SUBCOMPONENT_GITHASH" 255 "END";
VAL_ 790 PM_buildType 0 "UNKNOWN_BUILD" 1 "PLATFORM_BUILD" 2 "LOCAL_BUILD" 3 "TRACEABLE_CI_BUILD" 4 "MFG_BUILD";
VAL_ 790 PM_hardwareId 252 "CONFIGURABLE_HWID_PLACEHOLDER";
VAL_ 793 VCSEC_infoIndex 0 "DEPRECATED_0" 1 "DEPRECATED_1" 2 "DEPRECATED_2" 3 "DEPRECATED_3" 4 "DEPRECATED_4" 5 "DEPRECATED_5" 6 "DEPRECATED_6" 7 "DEPRECATED_7" 8 "DEPRECATED_8" 9 "DEPRECATED_9" 10 "BUILD_HWID_COMPONENTID" 11 "PCBAID_ASSYID_USAGEID" 13 "APP_CRC" 14 "BOOTLOADER_SVN" 15 "BOOTLOADER_CRC" 16 "SUBCOMPONENT1" 17 "APP_GITHASH" 18 "BOOTLOADER_GITHASH" 19 "VERSION_DEPRECATED" 20 "UDS_PROTOCOL_BOOTCRC" 23 "SUBCOMPONENT2" 24 "SUBCOMPONENT3" 31 "SUBCOMPONENT4" 255 "END";
VAL_ 793 VCSEC_infoBuildType 0 "UNKNOWN_BUILD" 1 "PLATFORM_BUILD" 2 "LOCAL_BUILD" 3 "TRACEABLE_CI_BUILD" 4 "MFG_BUILD";
VAL_ 793 VCSEC_infoAssemblyId 1 "ASSEMBLY1" 255 "ASSEMBLY_SNA";
VAL_ 794 VCRIGHT_frontBuckleStatus 0 "UNLATCHED" 1 "LATCHED" 2 "FAULTED" 3 "SNA";
VAL_ 794 VCRIGHT_frontOccupancyStatus 0 "UNOCCUPIED" 1 "OCCUPIED" 2 "OCCUPANCY_FAULTED" 3 "NOT_CONFIGURED" 7 "OCCUPANCY_SNA";
VAL_ 794 VCRIGHT_rearCenterBuckleStatus 0 "UNLATCHED" 1 "LATCHED" 2 "FAULTED" 3 "SNA";
VAL_ 794 VCRIGHT_rearRightBuckleStatus 0 "UNLATCHED" 1 "LATCHED" 2 "FAULTED" 3 "SNA";
VAL_ 796 CC_currentLimit 255 "SNA" ;
VAL_ 796 CC_gridGrounding 1 "CC_GRID_GROUNDING_IT_SplitPhase" 2 "CC_GRID_GROUNDING_SNA" 0 "CC_GRID_GROUNDING_TN_TT" ;
VAL_ 796 CC_line1Voltage 511 "SNA" ;
VAL_ 796 CC_line2Voltage 511 "SNA" ;
VAL_ 796 CC_line3Voltage 511 "SNA" ;
VAL_ 796 CC_numPhases 0 "SNA" ;
VAL_ 796 CC_pilotState 2 "CC_PILOT_STATE_FAULTED" 1 "CC_PILOT_STATE_IDLE" 0 "CC_PILOT_STATE_READY" 3 "CC_PILOT_STATE_SNA" ;
VAL_ 797 CC_chgStatus2Index 0 "Mux0";
VAL_ 797 CC_buttonState 0 "RELEASED" 1 "PRESSED";
VAL_ 798 CP_matrixIndex 0 "AlertMatrix0" 1 "AlertMatrix1";
VAL_ 800 BMS_matrixIndex 0 "AlertMatrix0" 1 "AlertMatrix1" 2 "AlertMatrix2";
VAL_ 801 VCFRONT_brakeFluidLevel 1 "LOW" 2 "NORMAL" 0 "SNA" ;
VAL_ 801 VCFRONT_coolantLevel 1 "FILLED" 0 "NOT_OK" ;
VAL_ 801 VCFRONT_tempAmbient 0 "SNA" ;
VAL_ 801 VCFRONT_tempAmbientFiltered 0 "SNA" ;
VAL_ 801 VCFRONT_tempCoolantBatInlet 1023 "SNA" ;
VAL_ 801 VCFRONT_tempCoolantPTInlet 2047 "SNA" ;
VAL_ 801 VCFRONT_washerFluidLevel 1 "LOW" 2 "NORMAL" 0 "SNA" ;
VAL_ 806 PARK_infoIndex 0 "DEPRECATED_0" 1 "DEPRECATED_1" 2 "DEPRECATED_2" 3 "DEPRECATED_3" 4 "DEPRECATED_4" 5 "DEPRECATED_5" 6 "DEPRECATED_6" 7 "DEPRECATED_7" 8 "DEPRECATED_8" 9 "DEPRECATED_9" 10 "BUILD_HWID_COMPONENTID" 11 "PCBAID_ASSYID_USAGEID" 13 "APP_CRC" 14 "BOOTLOADER_SVN" 15 "BOOTLOADER_CRC" 16 "SUBCOMPONENT" 17 "APP_GITHASH" 18 "BOOTLOADER_GITHASH" 19 "VERSION_DEPRECATED" 20 "UDS_PROTOCOL_BOOTCRC" 22 "VARIANTCRC" 25 "PACKAGE_PN_1_7" 26 "PACKAGE_PN_8_14" 27 "PACKAGE_PN_15_20" 29 "PACKAGE_SN_1_7" 30 "PACKAGE_SN_8_14" 31 "SUBCOMPONENT_GITHASH" 255 "END";
VAL_ 806 PARK_infoBuildType 0 "UNKNOWN_BUILD" 1 "PLATFORM_BUILD" 2 "LOCAL_BUILD" 3 "TRACEABLE_CI_BUILD" 4 "MFG_BUILD";
VAL_ 808 ESP_infoIndex 0 "DEPRECATED_0" 1 "DEPRECATED_1" 2 "DEPRECATED_2" 3 "DEPRECATED_3" 4 "DEPRECATED_4" 5 "DEPRECATED_5" 6 "DEPRECATED_6" 7 "DEPRECATED_7" 8 "DEPRECATED_8" 9 "DEPRECATED_9" 10 "BUILD_HWID_COMPONENTID" 11 "PCBAID_ASSYID_USAGEID" 13 "APP_CRC" 14 "BOOTLOADER_SVN" 15 "BOOTLOADER_CRC" 16 "SUBCOMPONENT" 17 "APP_GITHASH" 18 "BOOTLOADER_GITHASH" 19 "VERSION_DEPRECATED" 20 "UDS_PROTOCOL_BOOTCRC" 22 "VARIANTCRC" 25 "PACKAGE_PN_1_7" 26 "PACKAGE_PN_8_14" 27 "PACKAGE_PN_15_20" 29 "PACKAGE_SN_1_7" 30 "PACKAGE_SN_8_14" 31 "SUBCOMPONENT_GITHASH" 255 "END";
VAL_ 808 ESP_infoBuildType 0 "UNKNOWN_BUILD" 1 "PLATFORM_BUILD" 2 "LOCAL_BUILD" 3 "TRACEABLE_CI_BUILD" 4 "MFG_BUILD";
VAL_ 808 ESP_infoVehicleVariant 1 "01" 2 "02" 3 "03" 4 "04" 5 "05" 6 "06" 7 "07" 8 "08" 9 "09";
VAL_ 812 CC_logIndex 0 "Mux0" 1 "Mux1" 2 "Mux2" 3 "Mux3" 4 "Mux4" 10 "Mux10" 11 "Mux11" 12 "Mux12" 13 "Mux13";
VAL_ 812 CC_activeConnectorID 255 "SNA";
VAL_ 812 CC_temperature1 127 "SNA";
VAL_ 812 CC_temperature2 127 "SNA";
VAL_ 812 CC_temperature3 127 "SNA";
VAL_ 812 CC_contactor1Closed 0 "OPEN" 1 "CLOSED" 3 "SNA";
VAL_ 812 CC_contactor2Closed 0 "OPEN" 1 "CLOSED" 3 "SNA";
VAL_ 812 CC_temperature4 127 "SNA";
VAL_ 812 CC_conn1Current 255 "SNA";
VAL_ 812 CC_conn2Current 255 "SNA";
VAL_ 812 CC_conn3Current 255 "SNA";
VAL_ 812 CC_conn4Current 255 "SNA";
VAL_ 813 IBST_infoIndex 0 "DEPRECATED_0" 1 "DEPRECATED_1" 2 "DEPRECATED_2" 3 "DEPRECATED_3" 4 "DEPRECATED_4" 5 "DEPRECATED_5" 6 "DEPRECATED_6" 7 "DEPRECATED_7" 8 "DEPRECATED_8" 9 "DEPRECATED_9" 10 "BUILD_HWID_COMPONENTID" 11 "PCBAID_ASSYID_USAGEID" 13 "APP_CRC" 14 "BOOTLOADER_SVN" 15 "BOOTLOADER_CRC" 16 "SUBCOMPONENT" 17 "APP_GITHASH" 18 "BOOTLOADER_GITHASH" 19 "VERSION_DEPRECATED" 20 "UDS_PROTOCOL_BOOTCRC" 22 "VARIANTCRC" 25 "PACKAGE_PN_1_7" 26 "PACKAGE_PN_8_14" 27 "PACKAGE_PN_15_20" 29 "PACKAGE_SN_1_7" 30 "PACKAGE_SN_8_14" 31 "SUBCOMPONENT_GITHASH" 255 "END";
VAL_ 813 IBST_infoBuildType 0 "UNKNOWN_BUILD" 1 "PLATFORM_BUILD" 2 "LOCAL_BUILD" 3 "TRACEABLE_CI_BUILD" 4 "MFG_BUILD";
VAL_ 814 PARK_frontDtcPresent 0 "FALSE" 1 "TRUE" 2 "UNUSED" 3 "SNA";
VAL_ 814 PARK_frontLeftMiddleSensorState 0 "NO_FAILURE" 1 "PERMANENT_FAILURE" 2 "TEMPORARY_FAILURE" 3 "SNA";
VAL_ 814 PARK_frontLeftRawDistData 255 "SNA";
VAL_ 814 PARK_frontLeftSensorState 0 "NO_FAILURE" 1 "PERMANENT_FAILURE" 2 "TEMPORARY_FAILURE" 3 "SNA";
VAL_ 814 PARK_frontRightMiddleSensorState 0 "NO_FAILURE" 1 "PERMANENT_FAILURE" 2 "TEMPORARY_FAILURE" 3 "SNA";
VAL_ 814 PARK_frontRightRawDistData 255 "SNA";
VAL_ 814 PARK_frontRightSensorState 0 "NO_FAILURE" 1 "PERMANENT_FAILURE" 2 "TEMPORARY_FAILURE" 3 "SNA";
VAL_ 814 PARK_systemStatusFront 0 "DISABLED" 1 "ENABLED" 2 "UNUSED" 3 "SNA";
VAL_ 816 SCCM_infoIndex 10 "BUILD_HWID_COMPONENTID" 11 "PCBAID_ASSYID_USAGEID" 13 "APP_CRC" 14 "BOOTLOADER_SVN" 16 "SUBCOMPONENT1" 17 "APP_SVNHASH" 18 "BOOTLOADER_SVNHASH" 20 "UDS_PROTOCOL_BOOTCRC" 255 "END";
VAL_ 816 SCCM_infoBuildType 0 "UNKNOWN_BUILD" 1 "PLATFORM_BUILD" 2 "LOCAL_BUILD" 3 "TRACEABLE_CI_BUILD" 4 "MFG_BUILD";
VAL_ 817 EPAS3P_infoIndex 0 "DEPRECATED_0" 1 "DEPRECATED_1" 2 "DEPRECATED_2" 3 "DEPRECATED_3" 4 "DEPRECATED_4" 5 "DEPRECATED_5" 6 "DEPRECATED_6" 7 "DEPRECATED_7" 8 "DEPRECATED_8" 9 "DEPRECATED_9" 10 "BUILD_HWID_COMPONENTID" 11 "PCBAID_ASSYID_USAGEID" 13 "APP_CRC" 14 "BOOTLOADER_SVN" 15 "BOOTLOADER_CRC" 16 "SUBCOMPONENT" 17 "APP_GITHASH" 18 "BOOTLOADER_GITHASH" 19 "VERSION_DEPRECATED" 20 "UDS_PROTOCOL_BOOTCRC" 22 "VARIANTCRC" 25 "PACKAGE_PN_1_7" 26 "PACKAGE_PN_8_14" 27 "PACKAGE_PN_15_20" 29 "PACKAGE_SN_1_7" 30 "PACKAGE_SN_8_14" 31 "SUBCOMPONENT_GITHASH" 255 "END";
VAL_ 817 EPAS3P_infoBuildType 0 "UNKNOWN_BUILD" 1 "PLATFORM_BUILD" 2 "LOCAL_BUILD" 3 "TRACEABLE_CI_BUILD" 4 "MFG_BUILD";
VAL_ 819 UI_acChargeCurrentLimit 127 "SNA" ;
VAL_ 819 UI_brickBalancingDisabled 0 "FALSE" 1 "TRUE" ;
VAL_ 819 UI_brickVLoggingRequest 0 "FALSE" 1 "TRUE" ;
VAL_ 820 UI_limitMode 2 "LIMIT_FACTORY" 0 "LIMIT_NORMAL" 3 "LIMIT_SERVICE" 1 "LIMIT_VALET" ;
VAL_ 820 UI_motorOnMode 1 "MOTORONMODE_FRONT_ONLY" 0 "MOTORONMODE_NORMAL" 2 "MOTORONMODE_REAR_ONLY" ;
VAL_ 820 UI_pedalMap 0 "CHILL" 2 "PERFORMANCE" 1 "SPORT" ;
VAL_ 820 UI_speedLimit 255 "SNA" ;
VAL_ 820 UI_stoppingMode 1 "CREEP" 2 "HOLD" 0 "STANDARD" ;
VAL_ 820 UI_systemPowerLimit 31 "SNA" ;
VAL_ 820 UI_systemTorqueLimit 63 "SNA" ;
VAL_ 820 UI_wasteMode 2 "WASTE_TYPE_FULL" 0 "WASTE_TYPE_NONE" 1 "WASTE_TYPE_PARTIAL" ;
VAL_ 820 UI_wasteModeRegenLimit 3 "MAX_REGEN_CURRENT_0A" 2 "MAX_REGEN_CURRENT_10A" 1 "MAX_REGEN_CURRENT_30A" 0 "MAX_REGEN_CURRENT_MAX" ;
VAL_ 820 UI_closureConfirmed 1 "CONFIRMED_FRUNK" 0 "CONFIRMED_NONE" 2 "CONFIRMED_PROX" ;
VAL_ 821 DIR_infoIndex 13 "DI_INFO_APP_CRC" 17 "DI_INFO_APP_GITHASH" 15 "DI_INFO_BOOTLOADER_CRC" 18 "DI_INFO_BOOTLOADER_GITHASH" 14 "DI_INFO_BOOTLOADER_SVN" 10 "DI_INFO_BUILD_HWID_COMPONENTID" 0 "DI_INFO_DEPRECATED_0" 1 "DI_INFO_DEPRECATED_1" 2 "DI_INFO_DEPRECATED_2" 3 "DI_INFO_DEPRECATED_3" 4 "DI_INFO_DEPRECATED_4" 5 "DI_INFO_DEPRECATED_5" 6 "DI_INFO_DEPRECATED_6" 7 "DI_INFO_DEPRECATED_7" 8 "DI_INFO_DEPRECATED_8" 9 "DI_INFO_DEPRECATED_9" 255 "DI_INFO_END" 11 "DI_INFO_PCBAID_ASSYID_USAGEID" 16 "DI_INFO_SUBCOMPONENT" 23 "DI_INFO_SUBCOMPONENT2" 31 "DI_INFO_SUBCOMPONENT_GITHASH" 20 "DI_INFO_UDS_PROTOCOL_BOOTCRC" 19 "DI_INFO_VERSION_DEPRECATED" ;
VAL_ 821 DIR_FPGA_version 254 "FPGA_VERSION_LOCAL_BUILD" 255 "FPGA_VERSION_SNA" ;
VAL_ 821 DIR_buildType 2 "INFO_LOCAL_BUILD" 4 "INFO_MFG_BUILD" 1 "INFO_PLATFORM_BUILD" 3 "INFO_TRACEABLE_CI_BUILD" 0 "INFO_UNKNOWN_BUILD" ;
VAL_ 821 DIR_hardwareId 252 "CONFIGURABLE_HWID_PLACEHOLDER" ;
VAL_ 821 DIR_oilPumpBuildType 2 "INFO_LOCAL_BUILD" 4 "INFO_MFG_BUILD" 1 "INFO_PLATFORM_BUILD" 3 "INFO_TRACEABLE_CI_BUILD" 0 "INFO_UNKNOWN_BUILD" ;
VAL_ 822 DI_performancePackage 0 "BASE" 3 "BASE_PLUS" 1 "PERFORMANCE" 4 "SNA" ;
VAL_ 825 VCSEC_MCUCommandType 0 "NONE" 1 "REMOTE_UNLOCK" 2 "REMOTE_START" 3 "COMMAND3" 4 "COMMAND4" 5 "COMMAND5";
VAL_ 825 VCSEC_alarmStatus 0 "DISARMED" 1 "ARMED" 2 "PARTIAL_ARMED" 3 "TRIGGERED_FLASH_ACTIVE" 4 "ERROR" 5 "TRIGGERED_FLASH_INACTIVE" 6 "IMMINENT" 7 "DEFAULT" 15 "SNA";
VAL_ 825 VCSEC_authenticationStatus 0 "NONE" 1 "AUTHENTICATED_FOR_UNLOCK" 2 "AUTHENTICATED_FOR_DRIVE";
VAL_ 825 VCSEC_chargePortLockStatus 0 "UNLOCKED" 1 "LOCKED";
VAL_ 825 VCSEC_frunkRequest 0 "NONE" 1 "OPEN" 2 "SNA";
VAL_ 825 VCSEC_immobilizerState 0 "IDLE" 1 "PREPARE" 2 "ENCRYPT_BEGIN" 3 "ENCRYPT" 4 "SEND_AUTH_RESPONSE" 5 "SEND_NO_GO_AUTH_RESPONSE";
VAL_ 825 VCSEC_keyChannelIndexed 15 "SNA";
VAL_ 825 VCSEC_leftFrontLockStatus 0 "UNLOCKED" 1 "LOCKED";
VAL_ 825 VCSEC_leftRearLockStatus 0 "UNLOCKED" 1 "LOCKED";
VAL_ 825 VCSEC_lockIndicationRequest 0 "NONE_SNA" 1 "SINGLE" 2 "DOUBLE" 3 "TRIPLE" 4 "HOLD";
VAL_ 825 VCSEC_lockRequestType 0 "NONE" 1 "PASSIVE_SHIFT_TO_P_UNLOCK" 2 "PASSIVE_PARKBUTTON_UNLOCK" 3 "PASSIVE_INTERNAL_HANDLE_UNLOCK" 4 "PASSIVE_DRIVE_AWAY_LOCK" 5 "PASSIVE_BLE_WALKUP_UNLOCK" 6 "PASSIVE_BLE_EXTERIOR_CHARGEHANDLEBUTTON_UNLOCK" 7 "PASSIVE_BLE_EXTERIOR_HANDLE_UNLOCK" 8 "PASSIVE_BLE_INTERIOR_HANDLE_UNLOCK" 9 "PASSIVE_BLE_LOCK" 10 "CRASH_UNLOCK" 11 "ACTIVE_UI_BUTTON_UNLOCK" 12 "ACTIVE_UI_BUTTON_LOCK" 13 "ACTIVE_REMOTE_UNLOCK" 14 "ACTIVE_REMOTE_LOCK" 15 "ACTIVE_NFC_UNLOCK" 16 "ACTIVE_NFC_LOCK" 17 "ACTIVE_BLE_UNLOCK" 18 "ACTIVE_BLE_LOCK" 19 "PASSIVE_INTERNAL_LOCK_PROMOTION";
VAL_ 825 VCSEC_rightFrontLockStatus 0 "UNLOCKED" 1 "LOCKED";
VAL_ 825 VCSEC_rightRearLockStatus 0 "UNLOCKED" 1 "LOCKED";
VAL_ 825 VCSEC_simpleLockStatus 0 "SNA" 1 "UNLOCKED" 2 "LOCKED";
VAL_ 825 VCSEC_summonRequest 0 "IDLE" 1 "PRIME" 2 "FORWARD" 3 "BACKWARD" 4 "STOP" 5 "SNA";
VAL_ 825 VCSEC_trunkLockStatus 0 "UNLOCKED" 1 "LOCKED";
VAL_ 825 VCSEC_trunkRequest 0 "NONE" 1 "OPEN" 2 "SNA";
VAL_ 825 VCSEC_vehicleLockStatus 0 "SNA" 1 "ACTIVE_NFC_UNLOCKED" 2 "ACTIVE_NFC_LOCKED" 3 "PASSIVE_SELECTIVE_UNLOCKED" 4 "PASSIVE_BLE_UNLOCKED" 5 "PASSIVE_BLE_LOCKED" 6 "ACTIVE_SELECTIVE_UNLOCKED" 7 "ACTIVE_BLE_UNLOCKED" 8 "ACTIVE_BLE_LOCKED" 9 "ACTIVE_UI_UNLOCKED" 10 "ACTIVE_UI_LOCKED" 11 "ACTIVE_REMOTE_UNLOCKED" 12 "ACTIVE_REMOTE_LOCKED" 13 "CRASH_UNLOCKED" 14 "PASSIVE_INTERNAL_UNLOCKED" 15 "PASSIVE_INTERNAL_LOCKED";
VAL_ 830 PARK_rearDtcPresent 0 "FALSE" 1 "TRUE" 2 "UNUSED" 3 "SNA";
VAL_ 830 PARK_rearLeftMiddleSensorState 0 "NO_FAILURE" 1 "PERMANENT_FAILURE" 2 "TEMPORARY_FAILURE" 3 "SNA";
VAL_ 830 PARK_rearLeftRawDistData 255 "SNA";
VAL_ 830 PARK_rearLeftSensorState 0 "NO_FAILURE" 1 "PERMANENT_FAILURE" 2 "TEMPORARY_FAILURE" 3 "SNA";
VAL_ 830 PARK_rearRightMiddleSensorState 0 "NO_FAILURE" 1 "PERMANENT_FAILURE" 2 "TEMPORARY_FAILURE" 3 "SNA";
VAL_ 830 PARK_rearRightRawDistData 255 "SNA";
VAL_ 830 PARK_rearRightSensorState 0 "NO_FAILURE" 1 "PERMANENT_FAILURE" 2 "TEMPORARY_FAILURE" 3 "SNA";
VAL_ 830 PARK_systemStatusRear 0 "DISABLED" 1 "ENABLED" 2 "UNUSED" 3 "SNA";
VAL_ 832 VCFRONT_matrixIndex 0 "VCFRONT_AlertMatrix0" 1 "VCFRONT_AlertMatrix1" 2 "VCFRONT_AlertMatrix2" 3 "VCFRONT_AlertMatrix3" 4 "VCFRONT_AlertMatrix4" 5 "VCFRONT_AlertMatrix5" 6 "VCFRONT_AlertMatrix6" 7 "VCFRONT_AlertMatrix7" 8 "VCFRONT_AlertMatrix8" 9 "VCFRONT_AlertMatrix9" ;
VAL_ 837 PTC_infoIndex 0 "DEPRECATED_0" 1 "DEPRECATED_1" 2 "DEPRECATED_2" 3 "DEPRECATED_3" 4 "DEPRECATED_4" 5 "DEPRECATED_5" 6 "DEPRECATED_6" 7 "DEPRECATED_7" 8 "DEPRECATED_8" 9 "DEPRECATED_9" 10 "BUILD_HWID_COMPONENTID" 11 "PCBAID_ASSYID_USAGEID" 13 "APP_CRC" 14 "BOOTLOADER_SVN" 15 "BOOTLOADER_CRC" 16 "SUBCOMPONENT" 17 "APP_GITHASH" 18 "BOOTLOADER_GITHASH" 19 "VERSION_DEPRECATED" 20 "UDS_PROTOCOL_BOOTCRC" 22 "VARIANTCRC" 25 "PACKAGE_PN_1_7" 26 "PACKAGE_PN_8_14" 27 "PACKAGE_PN_15_20" 29 "PACKAGE_SN_1_7" 30 "PACKAGE_SN_8_14" 31 "SUBCOMPONENT_GITHASH" 255 "END";
VAL_ 837 PTC_infoBuildType 0 "UNKNOWN_BUILD" 1 "PLATFORM_BUILD" 2 "LOCAL_BUILD" 3 "TRACEABLE_CI_BUILD" 4 "MFG_BUILD";
VAL_ 837 PTC_infoAssemblyId 1 "ASSEMBLY1" 255 "ASSEMBLY_SNA";
VAL_ 840 GTW_vehicleVersionMatchStatus 0 "NOT_CALCULATED_YET" 1 "MISMATCHED" 2 "MATCHED";
VAL_ 846 PARK_frontLeftMiddleRawDistData 255 "SNA";
VAL_ 846 PARK_frontMiddleRawDistData 255 "SNA";
VAL_ 846 PARK_frontRightMiddleRawDistData 255 "SNA";
VAL_ 849 RCM_infoIndex 0 "DEPRECATED_0" 1 "DEPRECATED_1" 2 "DEPRECATED_2" 3 "DEPRECATED_3" 4 "DEPRECATED_4" 5 "DEPRECATED_5" 6 "DEPRECATED_6" 7 "DEPRECATED_7" 8 "DEPRECATED_8" 9 "DEPRECATED_9" 10 "BUILD_HWID_COMPONENTID" 11 "PCBAID_ASSYID_USAGEID" 13 "APP_CRC" 14 "BOOTLOADER_SVN" 15 "BOOTLOADER_CRC" 16 "SUBCOMPONENT" 17 "APP_GITHASH" 18 "BOOTLOADER_GITHASH" 19 "VERSION_DEPRECATED" 20 "UDS_PROTOCOL_BOOTCRC" 22 "VARIANTCRC" 25 "PACKAGE_PN_1_7" 26 "PACKAGE_PN_8_14" 27 "PACKAGE_PN_15_20" 29 "PACKAGE_SN_1_7" 30 "PACKAGE_SN_8_14" 31 "SUBCOMPONENT_GITHASH" 255 "END";
VAL_ 849 RCM_infoBuildType 0 "UNKNOWN_BUILD" 1 "PLATFORM_BUILD" 2 "LOCAL_BUILD" 3 "TRACEABLE_CI_BUILD" 4 "MFG_BUILD";
VAL_ 850 BMS_energyBuffer 255 "SNA" ;
VAL_ 850 BMS_energyToChargeComplete 2047 "SNA" ;
VAL_ 850 BMS_expectedEnergyRemaining 2047 "SNA" ;
VAL_ 850 BMS_idealEnergyRemaining 2047 "SNA" ;
VAL_ 850 BMS_nominalEnergyRemaining 2047 "SNA" ;
VAL_ 850 BMS_nominalFullPackEnergy 2047 "SNA" ;
VAL_ 856 UI_TPMSLearnIDMode 0 "NO_ID_LEARN_FUNCTION" 1 "AUTO_LEARN_ACTIVE_BY_MANUAL" 2 "AUTO_LOCATION_ACTIVE_BY_MANUAL" 3 "AUTO_LEARN_ACTIVE_AFTER_PWR" 4 "AUTO_LOCATION_ACTIVE_AFTER_PWR";
VAL_ 856 UI_TPMSMode 0 "UNUSED_MODE" 1 "NORMAL_MODE" 2 "PERFORMANCE_MODE";
VAL_ 856 UI_sizeOfWheelSelect 0 "UNUSED" 1 "18_INCH_WHEEL" 2 "19_INCH_WHEEL";
VAL_ 857 VCSEC_BLEConnectionStatus 0 "NOT_CONNECTED" 1 "CONNECTED" 2 "WRITE" 3 "NOTIFICATION" 4 "READ" 5 "UPDATE_SPEED";
VAL_ 857 VCSEC_BLEDeviceLocation 0 "NOT_PRESENT" 1 "CONNECTION_RANGE" 2 "AUTHENTICATION_RANGE";
VAL_ 857 VCSEC_BLEDevicePairingStatus 0 "IDLE" 1 "STEP1" 2 "STEP2" 3 "STEP3" 4 "SUCCESS" 5 "FAILURE";
VAL_ 857 VCSEC_BLEDeviceType 0 "UNKNOWN" 1 "ANDROID" 2 "IOS" 3 "OTHER";
VAL_ 861 IBST_matrixIndex 0 "AlertMatrix0" 1 "AlertMatrix1" 2 "AlertMatrix2";
VAL_ 862 PARK_rearLeftMiddleRawDistData 255 "SNA";
VAL_ 862 PARK_rearMiddleRawDistData 255 "SNA";
VAL_ 862 PARK_rearRightMiddleRawDistData 255 "SNA";
VAL_ 864 VCLEFT_matrixIndex 0 "VCLEFT_AlertMatrix0" 1 "VCLEFT_AlertMatrix1" 2 "VCLEFT_AlertMatrix2" 3 "VCLEFT_AlertMatrix3" 4 "VCLEFT_AlertMatrix4" 5 "VCLEFT_AlertMatrix5" 6 "VCLEFT_AlertMatrix6" 7 "VCLEFT_AlertMatrix7" 8 "VCLEFT_AlertMatrix8" 9 "VCLEFT_AlertMatrix9" ;
VAL_ 867 CMP_infoIndex 0 "DEPRECATED_0" 1 "DEPRECATED_1" 2 "DEPRECATED_2" 3 "DEPRECATED_3" 4 "DEPRECATED_4" 5 "DEPRECATED_5" 6 "DEPRECATED_6" 7 "DEPRECATED_7" 8 "DEPRECATED_8" 9 "DEPRECATED_9" 10 "BUILD_HWID_COMPONENTID" 11 "PCBAID_ASSYID_USAGEID" 13 "APP_CRC" 14 "BOOTLOADER_SVN" 15 "BOOTLOADER_CRC" 16 "SUBCOMPONENT" 17 "APP_GITHASH" 18 "BOOTLOADER_GITHASH" 19 "VERSION_DEPRECATED" 20 "UDS_PROTOCOL_BOOTCRC" 22 "VARIANTCRC" 25 "PACKAGE_PN_1_7" 26 "PACKAGE_PN_8_14" 27 "PACKAGE_PN_15_20" 29 "PACKAGE_SN_1_7" 30 "PACKAGE_SN_8_14" 31 "SUBCOMPONENT_GITHASH" 255 "END";
VAL_ 867 CMP_infoBuildType 0 "UNKNOWN_BUILD" 1 "PLATFORM_BUILD" 2 "LOCAL_BUILD" 3 "TRACEABLE_CI_BUILD" 4 "MFG_BUILD";
VAL_ 867 CMP_infoAssemblyId 1 "ASSEMBLY1" 255 "ASSEMBLY_SNA";
VAL_ 872 GTW_offboardUpdateState 0 "WAITING_FOR_CONNECTION" 1 "WAIT_UPDATE_TRIGGER" 2 "PREPARING" 3 "RUNNING" 4 "CONFIRM_UPDATE" 5 "LATCH_RESULT";
VAL_ 872 GTW_offboardUpdateStatus 0 "OK" 1 "FILE_OPEN_ERROR" 2 "UNPLUGGED" 3 "UDS_FAILED" 4 "SUCCESS" 5 "LOST_DIGITAL_COMMS" 6 "NOT_NEEDED" 7 "APPTRIPLE_MISMATCH";
VAL_ 879 TPMS_learningStatus 0 "FAILED" 1 "ONGOING" 2 "STOPPED" 3 "PASSED";
VAL_ 879 TPMS_localisationStatus 0 "FAILED" 1 "ONGOING" 2 "STOPPED" 3 "PASSED";
CM_ BO_ 692 "source: joshwardell/model3dbc (Model3CAN.dbc)";
CM_ BO_ 694 "source: joshwardell/model3dbc (Model3CAN.dbc)";
CM_ BO_ 697 "source: joshwardell/model3dbc (Model3CAN.dbc)";
CM_ BO_ 698 "source: onyx-m2/onyx-m2-dbc (tesla_model3.dbc)";
CM_ BO_ 701 "source: joshwardell/model3dbc (Model3CAN.dbc)";
CM_ BO_ 705 "source: onyx-m2/onyx-m2-dbc (tesla_model3.dbc)";
CM_ BO_ 706 "source: talas9/tesla_can_signals (ModelY_ETH.compact.json)";
CM_ BO_ 707 "source: talas9/tesla_can_signals (ModelY_ETH.compact.json)";
CM_ BO_ 708 "source: onyx-m2/onyx-m2-dbc (tesla_model3.dbc)";
CM_ BO_ 721 "source: onyx-m2/onyx-m2-dbc (tesla_model3.dbc)";
CM_ BO_ 722 "source: joshwardell/model3dbc (Model3CAN.dbc)";
CM_ BO_ 723 "source: joshwardell/model3dbc (Model3CAN.dbc)";
CM_ BO_ 725 "source: talas9/tesla_can_signals (ModelY_ETH.compact.json)";
CM_ BO_ 727 "source: talas9/tesla_can_signals (ModelY_ETH.compact.json)";
CM_ BO_ 737 "source: joshwardell/model3dbc (Model3CAN.dbc)";
CM_ BO_ 741 "source: joshwardell/model3dbc (Model3CAN.dbc)";
CM_ BO_ 742 "source: joshwardell/model3dbc (Model3CAN.dbc)";
CM_ BO_ 744 "source: talas9/tesla_can_signals (ModelY_ETH.compact.json)";
CM_ BO_ 753 "source: joshwardell/model3dbc (Model3CAN.dbc)";
CM_ BO_ 754 "source: onyx-m2/onyx-m2-dbc (tesla_model3.dbc)";
CM_ BO_ 755 "source: joshwardell/model3dbc (Model3CAN.dbc)";
CM_ BO_ 768 "source: joshwardell/model3dbc (Model3CAN.dbc)";
CM_ BO_ 769 "source: joshwardell/model3dbc (Model3CAN.dbc)";
CM_ BO_ 770 "source: onyx-m2/onyx-m2-dbc (tesla_model3.dbc)";
CM_ BO_ 771 "source: talas9/tesla_can_signals (ModelY_ETH.compact.json)";
CM_ BO_ 772 "source: onyx-m2/onyx-m2-dbc (tesla_model3.dbc)";
CM_ BO_ 774 "source: onyx-m2/onyx-m2-dbc (tesla_model3.dbc)";
CM_ BO_ 777 "source: joshwardell/model3dbc (Model3CAN.dbc)";
CM_ BO_ 778 "source: talas9/tesla_can_signals (ModelY_ETH.compact.json)";
CM_ BO_ 782 "source: talas9/tesla_can_signals (ModelY_ETH.compact.json)";
CM_ BO_ 784 "source: onyx-m2/onyx-m2-dbc (tesla_model3.dbc)";
CM_ BO_ 785 "source: onyx-m2/onyx-m2-dbc (tesla_model3.dbc)";
CM_ BO_ 786 "source: joshwardell/model3dbc (Model3CAN.dbc)";
CM_ BO_ 787 "source: joshwardell/model3dbc (Model3CAN.dbc)";
CM_ BO_ 789 "source: joshwardell/model3dbc (Model3CAN.dbc)";
CM_ BO_ 790 "source: onyx-m2/onyx-m2-dbc (tesla_model3.dbc)";
CM_ BO_ 792 "source: joshwardell/model3dbc (Model3CAN.dbc)";
CM_ BO_ 793 "source: onyx-m2/onyx-m2-dbc (tesla_model3.dbc)";
CM_ BO_ 794 "source: onyx-m2/onyx-m2-dbc (tesla_model3.dbc)";
CM_ BO_ 796 "source: joshwardell/model3dbc (Model3CAN.dbc)";
CM_ BO_ 797 "source: onyx-m2/onyx-m2-dbc (tesla_model3.dbc)";
CM_ BO_ 798 "source: onyx-m2/onyx-m2-dbc (tesla_model3.dbc)";
CM_ BO_ 799 "source: joshwardell/model3dbc (Model3CAN.dbc)";
CM_ BO_ 800 "source: onyx-m2/onyx-m2-dbc (tesla_model3.dbc)";
CM_ BO_ 801 "source: joshwardell/model3dbc (Model3CAN.dbc)";
CM_ BO_ 805 "source: onyx-m2/onyx-m2-dbc (tesla_model3.dbc)";
CM_ BO_ 806 "source: onyx-m2/onyx-m2-dbc (tesla_model3.dbc)";
CM_ BO_ 808 "source: onyx-m2/onyx-m2-dbc (tesla_model3.dbc)";
CM_ BO_ 809 "source: onyx-m2/onyx-m2-dbc (tesla_model3.dbc)";
CM_ BO_ 810 "source: onyx-m2/onyx-m2-dbc (tesla_model3.dbc)";
CM_ BO_ 811 "source: onyx-m2/onyx-m2-dbc (tesla_model3.dbc)";
CM_ BO_ 812 "source: onyx-m2/onyx-m2-dbc (tesla_model3.dbc)";
CM_ BO_ 813 "source: onyx-m2/onyx-m2-dbc (tesla_model3.dbc)";
CM_ BO_ 814 "source: onyx-m2/onyx-m2-dbc (tesla_model3.dbc)";
CM_ BO_ 815 "source: onyx-m2/onyx-m2-dbc (tesla_model3.dbc)";
CM_ BO_ 816 "source: onyx-m2/onyx-m2-dbc (tesla_model3.dbc)";
CM_ BO_ 817 "source: onyx-m2/onyx-m2-dbc (tesla_model3.dbc)";
CM_ BO_ 818 "source: joshwardell/model3dbc (Model3CAN.dbc)";
CM_ BO_ 819 "source: joshwardell/model3dbc (Model3CAN.dbc)";
CM_ BO_ 820 "source: joshwardell/model3dbc (Model3CAN.dbc)";
CM_ BO_ 821 "source: joshwardell/model3dbc (Model3CAN.dbc)";
CM_ BO_ 822 "source: joshwardell/model3dbc (Model3CAN.dbc)";
CM_ BO_ 824 "source: onyx-m2/onyx-m2-dbc (tesla_model3.dbc)";
CM_ BO_ 825 "source: onyx-m2/onyx-m2-dbc (tesla_model3.dbc)";
CM_ BO_ 826 "source: joshwardell/model3dbc (Model3CAN.dbc)";
CM_ BO_ 830 "source: onyx-m2/onyx-m2-dbc (tesla_model3.dbc)";
CM_ BO_ 831 "source: onyx-m2/onyx-m2-dbc (tesla_model3.dbc)";
CM_ BO_ 832 "source: talas9/tesla_can_signals (ModelY_ETH.compact.json)";
CM_ BO_ 837 "source: onyx-m2/onyx-m2-dbc (tesla_model3.dbc)";
CM_ BO_ 840 "source: onyx-m2/onyx-m2-dbc (tesla_model3.dbc)";
CM_ BO_ 841 "source: onyx-m2/onyx-m2-dbc (tesla_model3.dbc)";
CM_ BO_ 845 "source: onyx-m2/onyx-m2-dbc (tesla_model3.dbc)";
CM_ BO_ 846 "source: onyx-m2/onyx-m2-dbc (tesla_model3.dbc)";
CM_ BO_ 848 "source: onyx-m2/onyx-m2-dbc (tesla_model3.dbc)";
CM_ BO_ 849 "source: onyx-m2/onyx-m2-dbc (tesla_model3.dbc)";
CM_ BO_ 850 "source: joshwardell/model3dbc (Model3CAN.dbc)";
CM_ BO_ 851 "source: joshwardell/model3dbc (Model3CAN.dbc)";
CM_ BO_ 854 "source: onyx-m2/onyx-m2-dbc (tesla_model3.dbc)";
CM_ BO_ 855 "source: onyx-m2/onyx-m2-dbc (tesla_model3.dbc)";
CM_ BO_ 856 "source: onyx-m2/onyx-m2-dbc (tesla_model3.dbc)";
CM_ BO_ 857 "source: onyx-m2/onyx-m2-dbc (tesla_model3.dbc)";
CM_ BO_ 858 "source: talas9/tesla_can_signals (ModelY_ETH.compact.json)";
CM_ BO_ 859 "source: onyx-m2/onyx-m2-dbc (tesla_model3.dbc)";
CM_ BO_ 861 "source: onyx-m2/onyx-m2-dbc (tesla_model3.dbc)";
CM_ BO_ 862 "source: onyx-m2/onyx-m2-dbc (tesla_model3.dbc)";
CM_ BO_ 864 "source: talas9/tesla_can_signals (ModelY_ETH.compact.json)";
CM_ BO_ 867 "source: onyx-m2/onyx-m2-dbc (tesla_model3.dbc)";
CM_ BO_ 869 "source: onyx-m2/onyx-m2-dbc (tesla_model3.dbc)";
CM_ BO_ 872 "source: onyx-m2/onyx-m2-dbc (tesla_model3.dbc)";
CM_ BO_ 873 "source: onyx-m2/onyx-m2-dbc (tesla_model3.dbc)";
CM_ BO_ 874 "source: onyx-m2/onyx-m2-dbc (tesla_model3.dbc)";
CM_ BO_ 876 "source: onyx-m2/onyx-m2-dbc (tesla_model3.dbc)";
CM_ BO_ 877 "source: onyx-m2/onyx-m2-dbc (tesla_model3.dbc)";
CM_ BO_ 879 "source: onyx-m2/onyx-m2-dbc (tesla_model3.dbc)";
